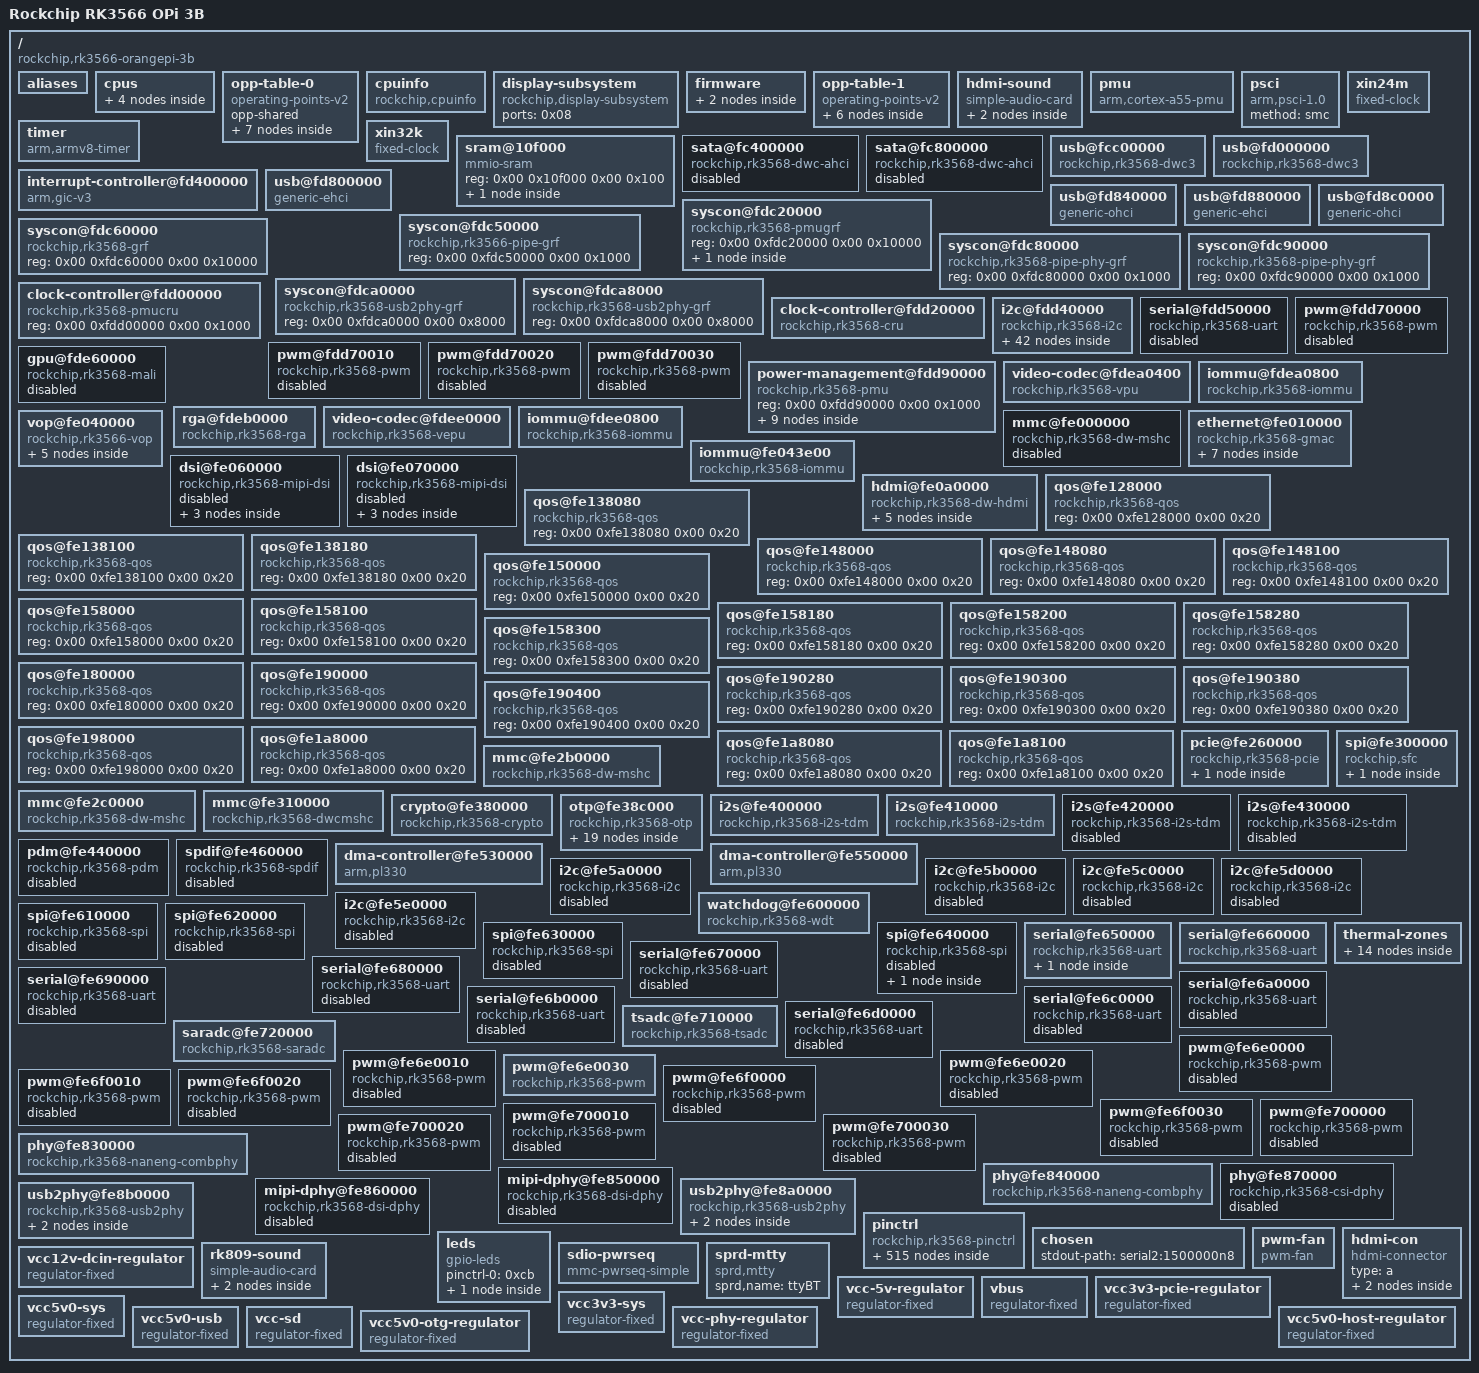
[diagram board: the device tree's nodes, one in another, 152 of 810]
/dts-v1/;

/ {
	interrupt-parent = <0x01>;
	#address-cells = <0x02>;
	#size-cells = <0x02>;
	compatible = "rockchip,rk3566-orangepi-3b\0rockchip,rk3566";
	model = "Rockchip RK3566 OPi 3B";

	aliases {
		gpio0 = "/pinctrl/gpio@fdd60000";
		gpio1 = "/pinctrl/gpio@fe740000";
		gpio2 = "/pinctrl/gpio@fe750000";
		gpio3 = "/pinctrl/gpio@fe760000";
		gpio4 = "/pinctrl/gpio@fe770000";
		i2c0 = "/i2c@fdd40000";
		i2c1 = "/i2c@fe5a0000";
		i2c2 = "/i2c@fe5b0000";
		i2c3 = "/i2c@fe5c0000";
		i2c4 = "/i2c@fe5d0000";
		i2c5 = "/i2c@fe5e0000";
		serial0 = "/serial@fdd50000";
		serial1 = "/serial@fe650000";
		serial2 = "/serial@fe660000";
		serial3 = "/serial@fe670000";
		serial4 = "/serial@fe680000";
		serial5 = "/serial@fe690000";
		serial6 = "/serial@fe6a0000";
		serial7 = "/serial@fe6b0000";
		serial8 = "/serial@fe6c0000";
		serial9 = "/serial@fe6d0000";
		spi0 = "/spi@fe610000";
		spi1 = "/spi@fe620000";
		spi2 = "/spi@fe630000";
		spi3 = "/spi@fe640000";
		ethernet0 = "/ethernet@fe010000";
		mmc0 = "/mmc@fe310000";
		mmc1 = "/mmc@fe2b0000";
	};

	cpus {
		#address-cells = <0x02>;
		#size-cells = <0x00>;

		cpu@0 {
			device_type = "cpu";
			compatible = "arm,cortex-a55";
			reg = <0x00 0x00>;
			clocks = <0x02 0x00>;
			#cooling-cells = <0x02>;
			enable-method = "psci";
			operating-points-v2 = <0x03>;
			cpu-supply = <0x04>;
			phandle = <0x0c>;
		};

		cpu@100 {
			device_type = "cpu";
			compatible = "arm,cortex-a55";
			reg = <0x00 0x100>;
			#cooling-cells = <0x02>;
			enable-method = "psci";
			operating-points-v2 = <0x03>;
			cpu-supply = <0x04>;
			phandle = <0x0d>;
		};

		cpu@200 {
			device_type = "cpu";
			compatible = "arm,cortex-a55";
			reg = <0x00 0x200>;
			#cooling-cells = <0x02>;
			enable-method = "psci";
			operating-points-v2 = <0x03>;
			cpu-supply = <0x04>;
			phandle = <0x0e>;
		};

		cpu@300 {
			device_type = "cpu";
			compatible = "arm,cortex-a55";
			reg = <0x00 0x300>;
			#cooling-cells = <0x02>;
			enable-method = "psci";
			operating-points-v2 = <0x03>;
			cpu-supply = <0x04>;
			phandle = <0x0f>;
		};
	};

	opp-table-0 {
		compatible = "operating-points-v2";
		opp-shared;
		phandle = <0x03>;

		opp-408000000 {
			opp-hz = <0x00 0x18519600>;
			opp-microvolt = <0xdbba0 0xdbba0 0x118c30>;
			clock-latency-ns = <0x9c40>;
		};

		opp-600000000 {
			opp-hz = <0x00 0x23c34600>;
			opp-microvolt = <0xdbba0 0xdbba0 0x118c30>;
		};

		opp-816000000 {
			opp-hz = <0x00 0x30a32c00>;
			opp-microvolt = <0xdbba0 0xdbba0 0x118c30>;
			opp-suspend;
		};

		opp-1104000000 {
			opp-hz = <0x00 0x41cdb400>;
			opp-microvolt = <0xdbba0 0xdbba0 0x118c30>;
		};

		opp-1416000000 {
			opp-hz = <0x00 0x54667200>;
			opp-microvolt = <0xdbba0 0xdbba0 0x118c30>;
		};

		opp-1608000000 {
			opp-hz = <0x00 0x5fd82200>;
			opp-microvolt = <0xee098 0xee098 0x118c30>;
		};

		opp-1800000000 {
			opp-hz = <0x00 0x6b49d200>;
			opp-microvolt = <0x100590 0x100590 0x118c30>;
		};
	};

	cpuinfo {
		compatible = "rockchip,cpuinfo";
		nvmem-cells = <0x05 0x06 0x07>;
		nvmem-cell-names = "id\0cpu-version\0cpu-code";
	};

	display-subsystem {
		compatible = "rockchip,display-subsystem";
		ports = <0x08>;
		phandle = <0xd2>;
	};

	firmware {

		scmi {
			compatible = "arm,scmi-smc";
			arm,smc-id = <0x82000010>;
			shmem = <0x09>;
			#address-cells = <0x01>;
			#size-cells = <0x00>;
			phandle = <0xd3>;

			protocol@14 {
				reg = <0x14>;
				#clock-cells = <0x01>;
				phandle = <0x02>;
			};
		};
	};

	opp-table-1 {
		compatible = "operating-points-v2";
		phandle = <0x4a>;

		opp-200000000 {
			opp-hz = <0x00 0xbebc200>;
			opp-microvolt = <0xc96a8>;
		};

		opp-300000000 {
			opp-hz = <0x00 0x11e1a300>;
			opp-microvolt = <0xc96a8>;
		};

		opp-400000000 {
			opp-hz = <0x00 0x17d78400>;
			opp-microvolt = <0xc96a8>;
		};

		opp-600000000 {
			opp-hz = <0x00 0x23c34600>;
			opp-microvolt = <0xc96a8>;
		};

		opp-700000000 {
			opp-hz = <0x00 0x29b92700>;
			opp-microvolt = <0xdbba0>;
		};

		opp-800000000 {
			opp-hz = <0x00 0x2faf0800>;
			opp-microvolt = <0xf4240>;
		};
	};

	hdmi-sound {
		compatible = "simple-audio-card";
		simple-audio-card,name = "HDMI";
		simple-audio-card,format = "i2s";
		simple-audio-card,mclk-fs = <0x100>;
		status = "okay";
		phandle = <0xd4>;

		simple-audio-card,codec {
			sound-dai = <0x0a>;
		};

		simple-audio-card,cpu {
			sound-dai = <0x0b>;
		};
	};

	pmu {
		compatible = "arm,cortex-a55-pmu";
		interrupts = <0x00 0xe4 0x04 0x00 0xe5 0x04 0x00 0xe6 0x04 0x00 0xe7 0x04>;
		interrupt-affinity = <0x0c 0x0d 0x0e 0x0f>;
	};

	psci {
		compatible = "arm,psci-1.0";
		method = "smc";
	};

	timer {
		compatible = "arm,armv8-timer";
		interrupts = <0x01 0x0d 0x04 0x01 0x0e 0x04 0x01 0x0b 0x04 0x01 0x0a 0x04>;
		arm,no-tick-in-suspend;
	};

	xin24m {
		compatible = "fixed-clock";
		clock-frequency = <0x16e3600>;
		clock-output-names = "xin24m";
		#clock-cells = <0x00>;
		phandle = <0x1f>;
	};

	xin32k {
		compatible = "fixed-clock";
		clock-frequency = <0x8000>;
		clock-output-names = "xin32k";
		pinctrl-0 = <0x10>;
		pinctrl-names = "default";
		#clock-cells = <0x00>;
		phandle = <0xd5>;
	};

	sram@10f000 {
		compatible = "mmio-sram";
		reg = <0x00 0x10f000 0x00 0x100>;
		#address-cells = <0x01>;
		#size-cells = <0x01>;
		ranges = <0x00 0x00 0x10f000 0x100>;

		sram@0 {
			compatible = "arm,scmi-shmem";
			reg = <0x00 0x100>;
			phandle = <0x09>;
		};
	};

	sata@fc400000 {
		compatible = "rockchip,rk3568-dwc-ahci\0snps,dwc-ahci";
		reg = <0x00 0xfc400000 0x00 0x1000>;
		clocks = <0x11 0x9b 0x11 0x9c 0x11 0x9d>;
		clock-names = "sata\0pmalive\0rxoob";
		interrupts = <0x00 0x5f 0x04>;
		phys = <0x12 0x01>;
		phy-names = "sata-phy";
		ports-implemented = <0x01>;
		power-domains = <0x13 0x0f>;
		status = "disabled";
		phandle = <0xd6>;
	};

	sata@fc800000 {
		compatible = "rockchip,rk3568-dwc-ahci\0snps,dwc-ahci";
		reg = <0x00 0xfc800000 0x00 0x1000>;
		clocks = <0x11 0xa0 0x11 0xa1 0x11 0xa2>;
		clock-names = "sata\0pmalive\0rxoob";
		interrupts = <0x00 0x60 0x04>;
		phys = <0x14 0x01>;
		phy-names = "sata-phy";
		ports-implemented = <0x01>;
		power-domains = <0x13 0x0f>;
		status = "disabled";
		phandle = <0xd7>;
	};

	usb@fcc00000 {
		compatible = "rockchip,rk3568-dwc3\0snps,dwc3";
		reg = <0x00 0xfcc00000 0x00 0x400000>;
		interrupts = <0x00 0xa9 0x04>;
		clocks = <0x11 0xa6 0x11 0xa7 0x11 0xa5>;
		clock-names = "ref_clk\0suspend_clk\0bus_clk";
		dr_mode = "host";
		phy_type = "utmi_wide";
		power-domains = <0x13 0x0f>;
		resets = <0x11 0x94>;
		snps,dis_u2_susphy_quirk;
		status = "okay";
		phys = <0x15>;
		phy-names = "usb2-phy";
		extcon = <0x16>;
		maximum-speed = "high-speed";
		phandle = <0xd8>;
	};

	usb@fd000000 {
		compatible = "rockchip,rk3568-dwc3\0snps,dwc3";
		reg = <0x00 0xfd000000 0x00 0x400000>;
		interrupts = <0x00 0xaa 0x04>;
		clocks = <0x11 0xa9 0x11 0xaa 0x11 0xa8>;
		clock-names = "ref_clk\0suspend_clk\0bus_clk";
		dr_mode = "host";
		phys = <0x17 0x12 0x04>;
		phy-names = "usb2-phy\0usb3-phy";
		phy_type = "utmi_wide";
		power-domains = <0x13 0x0f>;
		resets = <0x11 0x95>;
		snps,dis_u2_susphy_quirk;
		status = "okay";
		phandle = <0xd9>;
	};

	interrupt-controller@fd400000 {
		compatible = "arm,gic-v3";
		reg = <0x00 0xfd400000 0x00 0x10000 0x00 0xfd460000 0x00 0x80000>;
		interrupts = <0x01 0x09 0x04>;
		interrupt-controller;
		#interrupt-cells = <0x03>;
		mbi-alias = <0x00 0xfd410000>;
		mbi-ranges = <0x128 0x18>;
		msi-controller;
		phandle = <0x01>;
	};

	usb@fd800000 {
		compatible = "generic-ehci";
		reg = <0x00 0xfd800000 0x00 0x40000>;
		interrupts = <0x00 0x82 0x04>;
		clocks = <0x11 0xbd 0x11 0xbe 0x11 0xbc>;
		phys = <0x18>;
		phy-names = "usb";
		status = "okay";
		phandle = <0xda>;
	};

	usb@fd840000 {
		compatible = "generic-ohci";
		reg = <0x00 0xfd840000 0x00 0x40000>;
		interrupts = <0x00 0x83 0x04>;
		clocks = <0x11 0xbd 0x11 0xbe 0x11 0xbc>;
		phys = <0x18>;
		phy-names = "usb";
		status = "okay";
		phandle = <0xdb>;
	};

	usb@fd880000 {
		compatible = "generic-ehci";
		reg = <0x00 0xfd880000 0x00 0x40000>;
		interrupts = <0x00 0x85 0x04>;
		clocks = <0x11 0xbf 0x11 0xc0 0x11 0xbc>;
		phys = <0x19>;
		phy-names = "usb";
		status = "okay";
		phandle = <0xdc>;
	};

	usb@fd8c0000 {
		compatible = "generic-ohci";
		reg = <0x00 0xfd8c0000 0x00 0x40000>;
		interrupts = <0x00 0x86 0x04>;
		clocks = <0x11 0xbf 0x11 0xc0 0x11 0xbc>;
		phys = <0x19>;
		phy-names = "usb";
		status = "okay";
		phandle = <0xdd>;
	};

	syscon@fdc20000 {
		compatible = "rockchip,rk3568-pmugrf\0syscon\0simple-mfd";
		reg = <0x00 0xfdc20000 0x00 0x10000>;
		phandle = <0xbc>;

		io-domains {
			compatible = "rockchip,rk3568-pmu-io-voltage-domain";
			status = "okay";
			pmuio1-supply = <0x1a>;
			pmuio2-supply = <0x1a>;
			vccio1-supply = <0x1b>;
			vccio2-supply = <0x1c>;
			vccio3-supply = <0x1d>;
			vccio4-supply = <0x1c>;
			vccio5-supply = <0x1e>;
			vccio6-supply = <0x1b>;
			vccio7-supply = <0x1b>;
			phandle = <0xde>;
		};
	};

	syscon@fdc50000 {
		reg = <0x00 0xfdc50000 0x00 0x1000>;
		compatible = "rockchip,rk3566-pipe-grf\0syscon";
		phandle = <0xb6>;
	};

	syscon@fdc60000 {
		compatible = "rockchip,rk3568-grf\0syscon\0simple-mfd";
		reg = <0x00 0xfdc60000 0x00 0x10000>;
		phandle = <0x21>;
	};

	syscon@fdc80000 {
		compatible = "rockchip,rk3568-pipe-phy-grf\0syscon";
		reg = <0x00 0xfdc80000 0x00 0x1000>;
		phandle = <0xb7>;
	};

	syscon@fdc90000 {
		compatible = "rockchip,rk3568-pipe-phy-grf\0syscon";
		reg = <0x00 0xfdc90000 0x00 0x1000>;
		phandle = <0xb8>;
	};

	syscon@fdca0000 {
		compatible = "rockchip,rk3568-usb2phy-grf\0syscon";
		reg = <0x00 0xfdca0000 0x00 0x8000>;
		phandle = <0xb9>;
	};

	syscon@fdca8000 {
		compatible = "rockchip,rk3568-usb2phy-grf\0syscon";
		reg = <0x00 0xfdca8000 0x00 0x8000>;
		phandle = <0xbb>;
	};

	clock-controller@fdd00000 {
		compatible = "rockchip,rk3568-pmucru";
		reg = <0x00 0xfdd00000 0x00 0x1000>;
		#clock-cells = <0x01>;
		#reset-cells = <0x01>;
		phandle = <0x20>;
	};

	clock-controller@fdd20000 {
		compatible = "rockchip,rk3568-cru";
		reg = <0x00 0xfdd20000 0x00 0x1000>;
		clocks = <0x1f>;
		clock-names = "xin24m";
		#clock-cells = <0x01>;
		#reset-cells = <0x01>;
		assigned-clocks = <0x20 0x05 0x11 0x04 0x20 0x01>;
		assigned-clock-rates = <0x8000 0x47868c00 0xbebc200>;
		assigned-clock-parents = <0x20 0x08>;
		rockchip,grf = <0x21>;
		phandle = <0x11>;
	};

	i2c@fdd40000 {
		compatible = "rockchip,rk3568-i2c\0rockchip,rk3399-i2c";
		reg = <0x00 0xfdd40000 0x00 0x1000>;
		interrupts = <0x00 0x2e 0x04>;
		clocks = <0x20 0x07 0x20 0x2d>;
		clock-names = "i2c\0pclk";
		pinctrl-0 = <0x22>;
		pinctrl-names = "default";
		#address-cells = <0x01>;
		#size-cells = <0x00>;
		status = "okay";
		phandle = <0xdf>;

		syr837@40 {
			compatible = "silergy,syr827";
			reg = <0x40>;
			vin-supply = <0x23>;
			regulator-compatible = "fan53555-reg";
			regulator-name = "vdd_cpu";
			regulator-min-microvolt = <0xadf34>;
			regulator-max-microvolt = <0x1535b0>;
			regulator-init-microvolt = <0xdbba0>;
			regulator-initial-mode = <0x01>;
			regulator-ramp-delay = <0x8fc>;
			fcs,suspend-voltage-selector = <0x01>;
			regulator-boot-on;
			regulator-always-on;
			phandle = <0x04>;

			regulator-state-mem {
				regulator-off-in-suspend;
			};
		};

		pmic@20 {
			compatible = "rockchip,rk809";
			reg = <0x20>;
			interrupt-parent = <0x24>;
			interrupts = <0x03 0x08>;
			assigned-clocks = <0x11 0x48>;
			assigned-clock-parents = <0x11 0x196>;
			#clock-cells = <0x01>;
			clock-names = "mclk";
			clocks = <0x11 0x48>;
			pinctrl-names = "default\0pmic-sleep\0pmic-power-off\0pmic-reset";
			pinctrl-0 = <0x25 0x26>;
			pinctrl-1 = <0x27 0x28>;
			pinctrl-2 = <0x29 0x2a>;
			pinctrl-3 = <0x29 0x2b>;
			#sound-dai-cells = <0x00>;
			rockchip,system-power-controller;
			wakeup-source;
			vcc1-supply = <0x2c>;
			vcc2-supply = <0x2c>;
			vcc3-supply = <0x2c>;
			vcc4-supply = <0x2c>;
			vcc5-supply = <0x2c>;
			vcc6-supply = <0x2c>;
			vcc7-supply = <0x2c>;
			vcc8-supply = <0x2c>;
			vcc9-supply = <0x2c>;
			phandle = <0x96>;

			pinctrl_rk8xx {
				gpio-controller;
				#gpio-cells = <0x02>;
				phandle = <0xe0>;

				rk817_slppin_null {
					pins = "gpio_slp";
					function = "pin_fun0";
					phandle = <0xe1>;
				};

				rk817_slppin_slp {
					pins = "gpio_slp";
					function = "pin_fun1";
					phandle = <0x28>;
				};

				rk817_slppin_pwrdn {
					pins = "gpio_slp";
					function = "pin_fun2";
					phandle = <0x2a>;
				};

				rk817_slppin_rst {
					pins = "gpio_slp";
					function = "pin_fun3";
					phandle = <0x2b>;
				};
			};

			regulators {

				DCDC_REG1 {
					regulator-always-on;
					regulator-boot-on;
					regulator-min-microvolt = <0x7a120>;
					regulator-max-microvolt = <0x149970>;
					regulator-init-microvolt = <0xdbba0>;
					regulator-ramp-delay = <0x1771>;
					regulator-initial-mode = <0x02>;
					regulator-name = "vdd_logic";
					phandle = <0xe2>;

					regulator-state-mem {
						regulator-off-in-suspend;
					};
				};

				DCDC_REG2 {
					regulator-always-on;
					regulator-boot-on;
					regulator-min-microvolt = <0x7a120>;
					regulator-max-microvolt = <0x149970>;
					regulator-init-microvolt = <0xdbba0>;
					regulator-ramp-delay = <0x1771>;
					regulator-initial-mode = <0x02>;
					regulator-name = "vdd_gpu";
					phandle = <0x4b>;

					regulator-state-mem {
						regulator-off-in-suspend;
					};
				};

				DCDC_REG3 {
					regulator-always-on;
					regulator-boot-on;
					regulator-initial-mode = <0x02>;
					regulator-name = "vcc_ddr";
					phandle = <0xe3>;

					regulator-state-mem {
						regulator-on-in-suspend;
					};
				};

				DCDC_REG4 {
					regulator-always-on;
					regulator-boot-on;
					regulator-min-microvolt = <0x7a120>;
					regulator-max-microvolt = <0x149970>;
					regulator-init-microvolt = <0xdbba0>;
					regulator-ramp-delay = <0x1771>;
					regulator-initial-mode = <0x02>;
					regulator-name = "vdd_npu";
					phandle = <0xe4>;

					regulator-state-mem {
						regulator-off-in-suspend;
					};
				};

				LDO_REG1 {
					regulator-boot-on;
					regulator-always-on;
					regulator-min-microvolt = <0xdbba0>;
					regulator-max-microvolt = <0xdbba0>;
					regulator-name = "vdda0v9_image";
					phandle = <0x60>;

					regulator-state-mem {
						regulator-off-in-suspend;
					};
				};

				LDO_REG2 {
					regulator-always-on;
					regulator-boot-on;
					regulator-min-microvolt = <0xdbba0>;
					regulator-max-microvolt = <0xdbba0>;
					regulator-name = "vdda_0v9";
					phandle = <0xe5>;

					regulator-state-mem {
						regulator-off-in-suspend;
					};
				};

				LDO_REG3 {
					regulator-always-on;
					regulator-boot-on;
					regulator-min-microvolt = <0xdbba0>;
					regulator-max-microvolt = <0xdbba0>;
					regulator-name = "vdda0v9_pmu";
					phandle = <0xe6>;

					regulator-state-mem {
						regulator-on-in-suspend;
						regulator-suspend-microvolt = <0xdbba0>;
					};
				};

				LDO_REG4 {
					regulator-always-on;
					regulator-boot-on;
					regulator-min-microvolt = <0x2dc6c0>;
					regulator-max-microvolt = <0x2dc6c0>;
					regulator-name = "vccio_acodec";
					phandle = <0xe7>;

					regulator-state-mem {
						regulator-off-in-suspend;
					};
				};

				LDO_REG5 {
					regulator-always-on;
					regulator-boot-on;
					regulator-min-microvolt = <0x1b7740>;
					regulator-max-microvolt = <0x325aa0>;
					regulator-name = "vccio_sd";
					phandle = <0x1d>;

					regulator-state-mem {
						regulator-off-in-suspend;
					};
				};

				LDO_REG6 {
					regulator-always-on;
					regulator-boot-on;
					regulator-min-microvolt = <0x325aa0>;
					regulator-max-microvolt = <0x325aa0>;
					regulator-name = "vcc3v3_pmu";
					phandle = <0x1a>;

					regulator-state-mem {
						regulator-on-in-suspend;
						regulator-suspend-microvolt = <0x325aa0>;
					};
				};

				LDO_REG7 {
					regulator-always-on;
					regulator-boot-on;
					regulator-min-microvolt = <0x1b7740>;
					regulator-max-microvolt = <0x1b7740>;
					regulator-name = "vcca_1v8";
					phandle = <0xa9>;

					regulator-state-mem {
						regulator-off-in-suspend;
					};
				};

				LDO_REG8 {
					regulator-always-on;
					regulator-boot-on;
					regulator-min-microvolt = <0x1b7740>;
					regulator-max-microvolt = <0x1b7740>;
					regulator-name = "vcca1v8_pmu";
					phandle = <0xe8>;

					regulator-state-mem {
						regulator-on-in-suspend;
						regulator-suspend-microvolt = <0x1b7740>;
					};
				};

				LDO_REG9 {
					regulator-always-on;
					regulator-boot-on;
					regulator-min-microvolt = <0x1b7740>;
					regulator-max-microvolt = <0x1b7740>;
					regulator-name = "vcca1v8_image";
					phandle = <0x61>;

					regulator-state-mem {
						regulator-off-in-suspend;
					};
				};

				DCDC_REG5 {
					regulator-always-on;
					regulator-boot-on;
					regulator-min-microvolt = <0x1b7740>;
					regulator-max-microvolt = <0x1b7740>;
					regulator-name = "vcc_1v8";
					phandle = <0x1c>;

					regulator-state-mem {
						regulator-off-in-suspend;
					};
				};

				SWITCH_REG1 {
					regulator-always-on;
					regulator-boot-on;
					regulator-name = "vcc_3v3";
					phandle = <0x1b>;

					regulator-state-mem {
						regulator-off-in-suspend;
					};
				};

				SWITCH_REG2 {
					regulator-always-on;
					regulator-boot-on;
					regulator-name = "vcc3v3_sd";
					phandle = <0xe9>;

					regulator-state-mem {
						regulator-off-in-suspend;
					};
				};
			};

			codec {
				mic-in-differential;
			};
		};
	};

	serial@fdd50000 {
		compatible = "rockchip,rk3568-uart\0snps,dw-apb-uart";
		reg = <0x00 0xfdd50000 0x00 0x100>;
		interrupts = <0x00 0x74 0x04>;
		clocks = <0x20 0x0b 0x20 0x2c>;
		clock-names = "baudclk\0apb_pclk";
		dmas = <0x2d 0x00 0x2d 0x01>;
		pinctrl-0 = <0x2e>;
		pinctrl-names = "default";
		reg-io-width = <0x04>;
		reg-shift = <0x02>;
		status = "disabled";
		phandle = <0xea>;
	};

	pwm@fdd70000 {
		compatible = "rockchip,rk3568-pwm\0rockchip,rk3328-pwm";
		reg = <0x00 0xfdd70000 0x00 0x10>;
		clocks = <0x20 0x0d 0x20 0x30>;
		clock-names = "pwm\0pclk";
		pinctrl-0 = <0x2f>;
		pinctrl-names = "default";
		#pwm-cells = <0x03>;
		status = "disabled";
		phandle = <0xeb>;
	};

	pwm@fdd70010 {
		compatible = "rockchip,rk3568-pwm\0rockchip,rk3328-pwm";
		reg = <0x00 0xfdd70010 0x00 0x10>;
		clocks = <0x20 0x0d 0x20 0x30>;
		clock-names = "pwm\0pclk";
		pinctrl-0 = <0x30>;
		pinctrl-names = "default";
		#pwm-cells = <0x03>;
		status = "disabled";
		phandle = <0xec>;
	};

	pwm@fdd70020 {
		compatible = "rockchip,rk3568-pwm\0rockchip,rk3328-pwm";
		reg = <0x00 0xfdd70020 0x00 0x10>;
		clocks = <0x20 0x0d 0x20 0x30>;
		clock-names = "pwm\0pclk";
		pinctrl-0 = <0x31>;
		pinctrl-names = "default";
		#pwm-cells = <0x03>;
		status = "disabled";
		phandle = <0xed>;
	};

	pwm@fdd70030 {
		compatible = "rockchip,rk3568-pwm\0rockchip,rk3328-pwm";
		reg = <0x00 0xfdd70030 0x00 0x10>;
		clocks = <0x20 0x0d 0x20 0x30>;
		clock-names = "pwm\0pclk";
		pinctrl-0 = <0x32>;
		pinctrl-names = "default";
		#pwm-cells = <0x03>;
		status = "disabled";
		phandle = <0xee>;
	};

	power-management@fdd90000 {
		compatible = "rockchip,rk3568-pmu\0syscon\0simple-mfd";
		reg = <0x00 0xfdd90000 0x00 0x1000>;
		phandle = <0xef>;

		power-controller {
			compatible = "rockchip,rk3568-power-controller";
			#power-domain-cells = <0x01>;
			#address-cells = <0x01>;
			#size-cells = <0x00>;
			phandle = <0x13>;

			power-domain@7 {
				reg = <0x07>;
				clocks = <0x11 0x19 0x11 0x1a>;
				pm_qos = <0x33>;
				#power-domain-cells = <0x00>;
			};

			power-domain@8 {
				reg = <0x08>;
				clocks = <0x11 0xcc 0x11 0xcd>;
				pm_qos = <0x34 0x35 0x36>;
				#power-domain-cells = <0x00>;
			};

			power-domain@9 {
				reg = <0x09>;
				clocks = <0x11 0xda 0x11 0xdb 0x11 0xdc>;
				pm_qos = <0x37 0x38 0x39>;
				#power-domain-cells = <0x00>;
			};

			power-domain@10 {
				reg = <0x0a>;
				clocks = <0x11 0xf1 0x11 0xf2>;
				pm_qos = <0x3a 0x3b 0x3c 0x3d 0x3e 0x3f>;
				#power-domain-cells = <0x00>;
			};

			power-domain@11 {
				reg = <0x0b>;
				clocks = <0x11 0xed>;
				pm_qos = <0x40>;
				#power-domain-cells = <0x00>;
			};

			power-domain@13 {
				clocks = <0x11 0x107>;
				reg = <0x0d>;
				pm_qos = <0x41>;
				#power-domain-cells = <0x00>;
			};

			power-domain@14 {
				reg = <0x0e>;
				clocks = <0x11 0x102>;
				pm_qos = <0x42 0x43 0x44>;
				#power-domain-cells = <0x00>;
			};

			power-domain@15 {
				reg = <0x0f>;
				clocks = <0x11 0x7f>;
				pm_qos = <0x45 0x46 0x47 0x48 0x49>;
				#power-domain-cells = <0x00>;
			};
		};
	};

	gpu@fde60000 {
		compatible = "rockchip,rk3568-mali\0arm,mali-bifrost";
		reg = <0x00 0xfde60000 0x00 0x4000>;
		interrupts = <0x00 0x28 0x04 0x00 0x29 0x04 0x00 0x27 0x04>;
		interrupt-names = "job\0mmu\0gpu";
		clocks = <0x02 0x01 0x11 0x1b>;
		clock-names = "gpu\0bus";
		#cooling-cells = <0x02>;
		operating-points-v2 = <0x4a>;
		power-domains = <0x13 0x07>;
		status = "disabled";
		mali-supply = <0x4b>;
		phandle = <0xa6>;
	};

	video-codec@fdea0400 {
		compatible = "rockchip,rk3568-vpu";
		reg = <0x00 0xfdea0000 0x00 0x800>;
		interrupts = <0x00 0x8b 0x04>;
		clocks = <0x11 0xee 0x11 0xef>;
		clock-names = "aclk\0hclk";
		iommus = <0x4c>;
		power-domains = <0x13 0x0b>;
		phandle = <0xf0>;
	};

	iommu@fdea0800 {
		compatible = "rockchip,rk3568-iommu";
		reg = <0x00 0xfdea0800 0x00 0x40>;
		interrupts = <0x00 0x8a 0x04>;
		clock-names = "aclk\0iface";
		clocks = <0x11 0xee 0x11 0xef>;
		power-domains = <0x13 0x0b>;
		#iommu-cells = <0x00>;
		phandle = <0x4c>;
	};

	rga@fdeb0000 {
		compatible = "rockchip,rk3568-rga\0rockchip,rk3288-rga";
		reg = <0x00 0xfdeb0000 0x00 0x180>;
		interrupts = <0x00 0x5a 0x04>;
		clocks = <0x11 0xf3 0x11 0xf4 0x11 0xf5>;
		clock-names = "aclk\0hclk\0sclk";
		resets = <0x11 0x126 0x11 0x124 0x11 0x125>;
		reset-names = "core\0axi\0ahb";
		power-domains = <0x13 0x0a>;
		phandle = <0xf1>;
	};

	video-codec@fdee0000 {
		compatible = "rockchip,rk3568-vepu";
		reg = <0x00 0xfdee0000 0x00 0x800>;
		interrupts = <0x00 0x40 0x04>;
		clocks = <0x11 0xfd 0x11 0xfe>;
		clock-names = "aclk\0hclk";
		iommus = <0x4d>;
		power-domains = <0x13 0x0a>;
		phandle = <0xf2>;
	};

	iommu@fdee0800 {
		compatible = "rockchip,rk3568-iommu";
		reg = <0x00 0xfdee0800 0x00 0x40>;
		interrupts = <0x00 0x3f 0x04>;
		clocks = <0x11 0xfd 0x11 0xfe>;
		clock-names = "aclk\0iface";
		power-domains = <0x13 0x0a>;
		#iommu-cells = <0x00>;
		phandle = <0x4d>;
	};

	mmc@fe000000 {
		compatible = "rockchip,rk3568-dw-mshc\0rockchip,rk3288-dw-mshc";
		reg = <0x00 0xfe000000 0x00 0x4000>;
		interrupts = <0x00 0x64 0x04>;
		clocks = <0x11 0xc1 0x11 0xc2 0x11 0x18e 0x11 0x18f>;
		clock-names = "biu\0ciu\0ciu-drive\0ciu-sample";
		fifo-depth = <0x100>;
		max-frequency = <0x8f0d180>;
		resets = <0x11 0xeb>;
		reset-names = "reset";
		status = "disabled";
		phandle = <0xf3>;
	};

	ethernet@fe010000 {
		compatible = "rockchip,rk3568-gmac\0snps,dwmac-4.20a";
		reg = <0x00 0xfe010000 0x00 0x10000>;
		interrupts = <0x00 0x20 0x04 0x00 0x1d 0x04>;
		interrupt-names = "macirq\0eth_wake_irq";
		clocks = <0x11 0x186 0x11 0x189 0x11 0x189 0x11 0xc7 0x11 0xc3 0x11 0xc4 0x11 0x189 0x11 0xc8>;
		clock-names = "stmmaceth\0mac_clk_rx\0mac_clk_tx\0clk_mac_refout\0aclk_mac\0pclk_mac\0clk_mac_speed\0ptp_ref";
		resets = <0x11 0xec>;
		reset-names = "stmmaceth";
		rockchip,grf = <0x21>;
		snps,axi-config = <0x4e>;
		snps,mixed-burst;
		snps,mtl-rx-config = <0x4f>;
		snps,mtl-tx-config = <0x50>;
		snps,tso;
		status = "okay";
		assigned-clocks = <0x11 0x189 0x11 0x186>;
		assigned-clock-parents = <0x11 0x187 0x11 0xc5>;
		assigned-clock-rates = <0x00 0x7735940>;
		clock_in_out = "input";
		phy-mode = "rgmii";
		pinctrl-names = "default";
		pinctrl-0 = <0x51 0x52 0x53 0x54 0x55 0x56>;
		snps,reset-gpio = <0x57 0x14 0x01>;
		snps,reset-active-low;
		snps,reset-delays-us = <0x00 0xc350 0x30d40>;
		tx_delay = <0x30>;
		rx_delay = <0x10>;
		phy-handle = <0x58>;
		phandle = <0xf4>;

		mdio {
			compatible = "snps,dwmac-mdio";
			#address-cells = <0x01>;
			#size-cells = <0x00>;
			phandle = <0xf5>;

			phy@0 {
				compatible = "ethernet-phy-ieee802.3-c22";
				reg = <0x00>;
				phandle = <0x58>;
			};
		};

		stmmac-axi-config {
			snps,blen = <0x00 0x00 0x00 0x00 0x10 0x08 0x04>;
			snps,rd_osr_lmt = <0x08>;
			snps,wr_osr_lmt = <0x04>;
			phandle = <0x4e>;
		};

		rx-queues-config {
			snps,rx-queues-to-use = <0x01>;
			phandle = <0x4f>;

			queue0 {
			};
		};

		tx-queues-config {
			snps,tx-queues-to-use = <0x01>;
			phandle = <0x50>;

			queue0 {
			};
		};
	};

	vop@fe040000 {
		reg = <0x00 0xfe040000 0x00 0x3000 0x00 0xfe044000 0x00 0x1000>;
		reg-names = "vop\0gamma-lut";
		interrupts = <0x00 0x94 0x04>;
		clocks = <0x11 0xdd 0x11 0xde 0x11 0xdf 0x11 0xe0 0x11 0xe1>;
		clock-names = "aclk\0hclk\0dclk_vp0\0dclk_vp1\0dclk_vp2";
		iommus = <0x59>;
		power-domains = <0x13 0x09>;
		rockchip,grf = <0x21>;
		status = "okay";
		compatible = "rockchip,rk3566-vop";
		assigned-clocks = <0x11 0xdf 0x11 0xe0>;
		assigned-clock-parents = <0x20 0x02 0x11 0x05>;
		phandle = <0xf6>;

		ports {
			#address-cells = <0x01>;
			#size-cells = <0x00>;
			phandle = <0x08>;

			port@0 {
				reg = <0x00>;
				#address-cells = <0x01>;
				#size-cells = <0x00>;
				phandle = <0xf7>;

				endpoint@2 {
					reg = <0x02>;
					remote-endpoint = <0x5a>;
					status = "okay";
					phandle = <0x62>;
				};
			};

			port@1 {
				reg = <0x01>;
				#address-cells = <0x01>;
				#size-cells = <0x00>;
				phandle = <0xf8>;
			};

			port@2 {
				reg = <0x02>;
				#address-cells = <0x01>;
				#size-cells = <0x00>;
				phandle = <0xf9>;
			};
		};
	};

	iommu@fe043e00 {
		compatible = "rockchip,rk3568-iommu";
		reg = <0x00 0xfe043e00 0x00 0x100 0x00 0xfe043f00 0x00 0x100>;
		interrupts = <0x00 0x94 0x04>;
		clocks = <0x11 0xdd 0x11 0xde>;
		clock-names = "aclk\0iface";
		#iommu-cells = <0x00>;
		status = "okay";
		phandle = <0x59>;
	};

	dsi@fe060000 {
		compatible = "rockchip,rk3568-mipi-dsi\0snps,dw-mipi-dsi";
		reg = <0x00 0xfe060000 0x00 0x10000>;
		interrupts = <0x00 0x44 0x04>;
		clock-names = "pclk";
		clocks = <0x11 0xe8>;
		phy-names = "dphy";
		phys = <0x5b>;
		power-domains = <0x13 0x09>;
		reset-names = "apb";
		resets = <0x11 0x110>;
		rockchip,grf = <0x21>;
		status = "disabled";
		phandle = <0xfa>;

		ports {
			#address-cells = <0x01>;
			#size-cells = <0x00>;

			port@0 {
				reg = <0x00>;
				phandle = <0xfb>;
			};

			port@1 {
				reg = <0x01>;
				phandle = <0xfc>;
			};
		};
	};

	dsi@fe070000 {
		compatible = "rockchip,rk3568-mipi-dsi\0snps,dw-mipi-dsi";
		reg = <0x00 0xfe070000 0x00 0x10000>;
		interrupts = <0x00 0x45 0x04>;
		clock-names = "pclk";
		clocks = <0x11 0xe9>;
		phy-names = "dphy";
		phys = <0x5c>;
		power-domains = <0x13 0x09>;
		reset-names = "apb";
		resets = <0x11 0x111>;
		rockchip,grf = <0x21>;
		status = "disabled";
		phandle = <0xfd>;

		ports {
			#address-cells = <0x01>;
			#size-cells = <0x00>;

			port@0 {
				reg = <0x00>;
				phandle = <0xfe>;
			};

			port@1 {
				reg = <0x01>;
				phandle = <0xff>;
			};
		};
	};

	hdmi@fe0a0000 {
		compatible = "rockchip,rk3568-dw-hdmi";
		reg = <0x00 0xfe0a0000 0x00 0x20000>;
		interrupts = <0x00 0x2d 0x04>;
		clocks = <0x11 0xe6 0x11 0xe7 0x11 0x193 0x20 0x28 0x11 0xda>;
		clock-names = "iahb\0isfr\0cec\0ref";
		pinctrl-names = "default";
		pinctrl-0 = <0x5d 0x5e 0x5f>;
		power-domains = <0x13 0x09>;
		reg-io-width = <0x04>;
		rockchip,grf = <0x21>;
		#sound-dai-cells = <0x00>;
		status = "okay";
		avdd-0v9-supply = <0x60>;
		avdd-1v8-supply = <0x61>;
		phandle = <0x0a>;

		ports {
			#address-cells = <0x01>;
			#size-cells = <0x00>;

			port@0 {
				reg = <0x00>;
				phandle = <0x100>;

				endpoint {
					remote-endpoint = <0x62>;
					status = "okay";
					phandle = <0x5a>;
				};
			};

			port@1 {
				reg = <0x01>;
				phandle = <0x101>;

				endpoint {
					remote-endpoint = <0x63>;
					status = "okay";
					phandle = <0xca>;
				};
			};
		};
	};

	qos@fe128000 {
		compatible = "rockchip,rk3568-qos\0syscon";
		reg = <0x00 0xfe128000 0x00 0x20>;
		phandle = <0x33>;
	};

	qos@fe138080 {
		compatible = "rockchip,rk3568-qos\0syscon";
		reg = <0x00 0xfe138080 0x00 0x20>;
		phandle = <0x42>;
	};

	qos@fe138100 {
		compatible = "rockchip,rk3568-qos\0syscon";
		reg = <0x00 0xfe138100 0x00 0x20>;
		phandle = <0x43>;
	};

	qos@fe138180 {
		compatible = "rockchip,rk3568-qos\0syscon";
		reg = <0x00 0xfe138180 0x00 0x20>;
		phandle = <0x44>;
	};

	qos@fe148000 {
		compatible = "rockchip,rk3568-qos\0syscon";
		reg = <0x00 0xfe148000 0x00 0x20>;
		phandle = <0x34>;
	};

	qos@fe148080 {
		compatible = "rockchip,rk3568-qos\0syscon";
		reg = <0x00 0xfe148080 0x00 0x20>;
		phandle = <0x35>;
	};

	qos@fe148100 {
		compatible = "rockchip,rk3568-qos\0syscon";
		reg = <0x00 0xfe148100 0x00 0x20>;
		phandle = <0x36>;
	};

	qos@fe150000 {
		compatible = "rockchip,rk3568-qos\0syscon";
		reg = <0x00 0xfe150000 0x00 0x20>;
		phandle = <0x40>;
	};

	qos@fe158000 {
		compatible = "rockchip,rk3568-qos\0syscon";
		reg = <0x00 0xfe158000 0x00 0x20>;
		phandle = <0x3a>;
	};

	qos@fe158100 {
		compatible = "rockchip,rk3568-qos\0syscon";
		reg = <0x00 0xfe158100 0x00 0x20>;
		phandle = <0x3b>;
	};

	qos@fe158180 {
		compatible = "rockchip,rk3568-qos\0syscon";
		reg = <0x00 0xfe158180 0x00 0x20>;
		phandle = <0x3c>;
	};

	qos@fe158200 {
		compatible = "rockchip,rk3568-qos\0syscon";
		reg = <0x00 0xfe158200 0x00 0x20>;
		phandle = <0x3d>;
	};

	qos@fe158280 {
		compatible = "rockchip,rk3568-qos\0syscon";
		reg = <0x00 0xfe158280 0x00 0x20>;
		phandle = <0x3e>;
	};

	qos@fe158300 {
		compatible = "rockchip,rk3568-qos\0syscon";
		reg = <0x00 0xfe158300 0x00 0x20>;
		phandle = <0x3f>;
	};

	qos@fe180000 {
		compatible = "rockchip,rk3568-qos\0syscon";
		reg = <0x00 0xfe180000 0x00 0x20>;
		phandle = <0x102>;
	};

	qos@fe190000 {
		compatible = "rockchip,rk3568-qos\0syscon";
		reg = <0x00 0xfe190000 0x00 0x20>;
		phandle = <0x45>;
	};

	qos@fe190280 {
		compatible = "rockchip,rk3568-qos\0syscon";
		reg = <0x00 0xfe190280 0x00 0x20>;
		phandle = <0x46>;
	};

	qos@fe190300 {
		compatible = "rockchip,rk3568-qos\0syscon";
		reg = <0x00 0xfe190300 0x00 0x20>;
		phandle = <0x47>;
	};

	qos@fe190380 {
		compatible = "rockchip,rk3568-qos\0syscon";
		reg = <0x00 0xfe190380 0x00 0x20>;
		phandle = <0x48>;
	};

	qos@fe190400 {
		compatible = "rockchip,rk3568-qos\0syscon";
		reg = <0x00 0xfe190400 0x00 0x20>;
		phandle = <0x49>;
	};

	qos@fe198000 {
		compatible = "rockchip,rk3568-qos\0syscon";
		reg = <0x00 0xfe198000 0x00 0x20>;
		phandle = <0x41>;
	};

	qos@fe1a8000 {
		compatible = "rockchip,rk3568-qos\0syscon";
		reg = <0x00 0xfe1a8000 0x00 0x20>;
		phandle = <0x37>;
	};

	qos@fe1a8080 {
		compatible = "rockchip,rk3568-qos\0syscon";
		reg = <0x00 0xfe1a8080 0x00 0x20>;
		phandle = <0x38>;
	};

	qos@fe1a8100 {
		compatible = "rockchip,rk3568-qos\0syscon";
		reg = <0x00 0xfe1a8100 0x00 0x20>;
		phandle = <0x39>;
	};

	pcie@fe260000 {
		compatible = "rockchip,rk3568-pcie";
		reg = <0x03 0xc0000000 0x00 0x400000 0x00 0xfe260000 0x00 0x10000 0x00 0xf4000000 0x00 0x100000>;
		reg-names = "dbi\0apb\0config";
		interrupts = <0x00 0x4b 0x04 0x00 0x4a 0x04 0x00 0x49 0x04 0x00 0x48 0x04 0x00 0x47 0x04>;
		interrupt-names = "sys\0pmc\0msi\0legacy\0err";
		bus-range = <0x00 0x0f>;
		clocks = <0x11 0x81 0x11 0x82 0x11 0x83 0x11 0x84 0x11 0x85>;
		clock-names = "aclk_mst\0aclk_slv\0aclk_dbi\0pclk\0aux";
		device_type = "pci";
		#interrupt-cells = <0x01>;
		interrupt-map-mask = <0x00 0x00 0x00 0x07>;
		interrupt-map = <0x00 0x00 0x00 0x01 0x64 0x00 0x00 0x00 0x00 0x02 0x64 0x01 0x00 0x00 0x00 0x03 0x64 0x02 0x00 0x00 0x00 0x04 0x64 0x03>;
		linux,pci-domain = <0x00>;
		num-ib-windows = <0x06>;
		num-ob-windows = <0x02>;
		max-link-speed = <0x02>;
		msi-map = <0x00 0x01 0x00 0x1000>;
		num-lanes = <0x01>;
		phys = <0x14 0x02>;
		phy-names = "pcie-phy";
		power-domains = <0x13 0x0f>;
		ranges = <0x1000000 0x00 0xf4100000 0x00 0xf4100000 0x00 0x100000 0x2000000 0x00 0xf4200000 0x00 0xf4200000 0x00 0x1e00000 0x3000000 0x00 0x40000000 0x03 0x00 0x00 0x40000000>;
		resets = <0x11 0xa1>;
		reset-names = "pipe";
		#address-cells = <0x03>;
		#size-cells = <0x02>;
		status = "okay";
		reset-gpios = <0x24 0x0e 0x00>;
		vpcie3v3-supply = <0x65>;
		phandle = <0x103>;

		legacy-interrupt-controller {
			#address-cells = <0x00>;
			#interrupt-cells = <0x01>;
			interrupt-controller;
			interrupt-parent = <0x01>;
			interrupts = <0x00 0x48 0x01>;
			phandle = <0x64>;
		};
	};

	mmc@fe2b0000 {
		compatible = "rockchip,rk3568-dw-mshc\0rockchip,rk3288-dw-mshc";
		reg = <0x00 0xfe2b0000 0x00 0x4000>;
		interrupts = <0x00 0x62 0x04>;
		clocks = <0x11 0xb0 0x11 0xb1 0x11 0x18a 0x11 0x18b>;
		clock-names = "biu\0ciu\0ciu-drive\0ciu-sample";
		fifo-depth = <0x100>;
		max-frequency = <0x8f0d180>;
		resets = <0x11 0xd4>;
		reset-names = "reset";
		status = "okay";
		bus-width = <0x04>;
		cap-mmc-highspeed;
		cap-sd-highspeed;
		disable-wp;
		sd-uhs-sdr104;
		vmmc-supply = <0x66>;
		vqmmc-supply = <0x1d>;
		pinctrl-names = "default";
		pinctrl-0 = <0x67 0x68 0x69 0x6a>;
		phandle = <0x104>;
	};

	mmc@fe2c0000 {
		compatible = "rockchip,rk3568-dw-mshc\0rockchip,rk3288-dw-mshc";
		reg = <0x00 0xfe2c0000 0x00 0x4000>;
		interrupts = <0x00 0x63 0x04>;
		clocks = <0x11 0xb2 0x11 0xb3 0x11 0x18c 0x11 0x18d>;
		clock-names = "biu\0ciu\0ciu-drive\0ciu-sample";
		fifo-depth = <0x100>;
		max-frequency = <0x8f0d180>;
		resets = <0x11 0xd6>;
		reset-names = "reset";
		status = "okay";
		bus-width = <0x04>;
		disable-wp;
		cap-sd-highspeed;
		cap-sdio-irq;
		keep-power-in-suspend;
		mmc-pwrseq = <0x6b>;
		non-removable;
		pinctrl-names = "default";
		pinctrl-0 = <0x6c 0x6d 0x6e>;
		sd-uhs-sdr104;
		phandle = <0x105>;
	};

	spi@fe300000 {
		compatible = "rockchip,sfc";
		reg = <0x00 0xfe300000 0x00 0x4000>;
		interrupts = <0x00 0x65 0x04>;
		clocks = <0x11 0x78 0x11 0x76>;
		clock-names = "clk_sfc\0hclk_sfc";
		pinctrl-0 = <0x6f>;
		pinctrl-names = "default";
		status = "okay";
		#address-cells = <0x01>;
		#size-cells = <0x00>;
		phandle = <0x106>;

		flash@0 {
			compatible = "jedec,spi-nor";
			reg = <0x00>;
			spi-max-frequency = <0x5f5e100>;
			spi-rx-bus-width = <0x04>;
			spi-tx-bus-width = <0x01>;
		};
	};

	mmc@fe310000 {
		compatible = "rockchip,rk3568-dwcmshc";
		reg = <0x00 0xfe310000 0x00 0x10000>;
		interrupts = <0x00 0x13 0x04>;
		assigned-clocks = <0x11 0x7b 0x11 0x7d>;
		assigned-clock-rates = <0xbebc200 0x16e3600>;
		clocks = <0x11 0x7c 0x11 0x7a 0x11 0x79 0x11 0x7b 0x11 0x7d>;
		clock-names = "core\0bus\0axi\0block\0timer";
		status = "okay";
		bus-width = <0x08>;
		max-frequency = <0xbebc200>;
		non-removable;
		pinctrl-names = "default";
		pinctrl-0 = <0x70 0x71 0x72>;
		phandle = <0x107>;
	};

	crypto@fe380000 {
		compatible = "rockchip,rk3568-crypto";
		reg = <0x00 0xfe380000 0x00 0x2000>;
		interrupts = <0x00 0x04 0x04>;
		clocks = <0x11 0x6a 0x11 0x6b 0x11 0x6c>;
		clock-names = "aclk\0hclk\0core";
		resets = <0x11 0x69>;
		reset-names = "core";
		status = "okay";
		phandle = <0x108>;
	};

	otp@fe38c000 {
		compatible = "rockchip,rk3568-otp";
		reg = <0x00 0xfe38c000 0x00 0x4000>;
		#address-cells = <0x01>;
		#size-cells = <0x01>;
		clocks = <0x11 0x73 0x11 0x72 0x11 0x71 0x11 0x181>;
		clock-names = "usr\0sbpi\0apb\0phy";
		resets = <0x11 0x1cf>;
		reset-names = "otp_phy";
		phandle = <0x109>;

		cpu-code@2 {
			reg = <0x02 0x02>;
			phandle = <0x07>;
		};

		cpu-version@8 {
			reg = <0x08 0x01>;
			bits = <0x03 0x03>;
			phandle = <0x06>;
		};

		mbist-vmin@9 {
			reg = <0x09 0x01>;
			bits = <0x00 0x04>;
			phandle = <0x10a>;
		};

		id@a {
			reg = <0x0a 0x10>;
			phandle = <0x05>;
		};

		cpu-leakage@1a {
			reg = <0x1a 0x01>;
			phandle = <0x10b>;
		};

		log-leakage@1b {
			reg = <0x1b 0x01>;
			phandle = <0x10c>;
		};

		npu-leakage@1c {
			reg = <0x1c 0x01>;
			phandle = <0x10d>;
		};

		gpu-leakage@1d {
			reg = <0x1d 0x01>;
			phandle = <0x10e>;
		};

		core-pvtm@2a {
			reg = <0x2a 0x02>;
			phandle = <0x10f>;
		};

		cpu-tsadc-trim-l@2e {
			reg = <0x2e 0x01>;
			phandle = <0x110>;
		};

		cpu-tsadc-trim-h@2f {
			reg = <0x2f 0x01>;
			bits = <0x00 0x04>;
			phandle = <0x111>;
		};

		npu-tsadc-trim-l@30 {
			reg = <0x30 0x01>;
			phandle = <0x112>;
		};

		npu-tsadc-trim-h@31 {
			reg = <0x31 0x01>;
			bits = <0x00 0x04>;
			phandle = <0x113>;
		};

		tsadc-trim-base-frac@31 {
			reg = <0x31 0x01>;
			bits = <0x04 0x04>;
			phandle = <0x114>;
		};

		tsadc-trim-base@32 {
			reg = <0x32 0x01>;
			phandle = <0x115>;
		};

		cpu-opp-info@36 {
			reg = <0x36 0x06>;
			phandle = <0x116>;
		};

		gpu-opp-info@3c {
			reg = <0x3c 0x06>;
			phandle = <0x117>;
		};

		npu-opp-info@42 {
			reg = <0x42 0x06>;
			phandle = <0x118>;
		};

		dmc-opp-info@48 {
			reg = <0x48 0x06>;
			phandle = <0x119>;
		};
	};

	i2s@fe400000 {
		compatible = "rockchip,rk3568-i2s-tdm";
		reg = <0x00 0xfe400000 0x00 0x1000>;
		interrupts = <0x00 0x34 0x04>;
		assigned-clocks = <0x11 0x3d 0x11 0x41>;
		assigned-clock-rates = <0x46cf7100 0x46cf7100>;
		clocks = <0x11 0x3f 0x11 0x43 0x11 0x39>;
		clock-names = "mclk_tx\0mclk_rx\0hclk";
		dmas = <0x73 0x00>;
		dma-names = "tx";
		resets = <0x11 0x50 0x11 0x51>;
		reset-names = "tx-m\0rx-m";
		rockchip,grf = <0x21>;
		#sound-dai-cells = <0x00>;
		status = "okay";
		phandle = <0x0b>;
	};

	i2s@fe410000 {
		compatible = "rockchip,rk3568-i2s-tdm";
		reg = <0x00 0xfe410000 0x00 0x1000>;
		interrupts = <0x00 0x35 0x04>;
		assigned-clocks = <0x11 0x45 0x11 0x49>;
		assigned-clock-rates = <0x46cf7100 0x46cf7100>;
		clocks = <0x11 0x47 0x11 0x4b 0x11 0x3a>;
		clock-names = "mclk_tx\0mclk_rx\0hclk";
		dmas = <0x73 0x03 0x73 0x02>;
		dma-names = "rx\0tx";
		resets = <0x11 0x52 0x11 0x53>;
		reset-names = "tx-m\0rx-m";
		rockchip,grf = <0x21>;
		pinctrl-names = "default";
		pinctrl-0 = <0x74 0x75 0x76 0x77>;
		#sound-dai-cells = <0x00>;
		status = "okay";
		rockchip,trcm-sync-tx-only;
		phandle = <0xcc>;
	};

	i2s@fe420000 {
		compatible = "rockchip,rk3568-i2s-tdm";
		reg = <0x00 0xfe420000 0x00 0x1000>;
		interrupts = <0x00 0x36 0x04>;
		assigned-clocks = <0x11 0x4d>;
		assigned-clock-rates = <0x46cf7100>;
		clocks = <0x11 0x4f 0x11 0x4f 0x11 0x3b>;
		clock-names = "mclk_tx\0mclk_rx\0hclk";
		dmas = <0x73 0x04 0x73 0x05>;
		dma-names = "tx\0rx";
		resets = <0x11 0x54>;
		reset-names = "m";
		rockchip,grf = <0x21>;
		pinctrl-names = "default";
		pinctrl-0 = <0x78 0x79 0x7a 0x7b>;
		#sound-dai-cells = <0x00>;
		status = "disabled";
		phandle = <0x11a>;
	};

	i2s@fe430000 {
		compatible = "rockchip,rk3568-i2s-tdm";
		reg = <0x00 0xfe430000 0x00 0x1000>;
		interrupts = <0x00 0x37 0x04>;
		clocks = <0x11 0x53 0x11 0x57 0x11 0x3c>;
		clock-names = "mclk_tx\0mclk_rx\0hclk";
		dmas = <0x73 0x06 0x73 0x07>;
		dma-names = "tx\0rx";
		resets = <0x11 0x55 0x11 0x56>;
		reset-names = "tx-m\0rx-m";
		rockchip,grf = <0x21>;
		#sound-dai-cells = <0x00>;
		status = "disabled";
		phandle = <0x11b>;
	};

	pdm@fe440000 {
		compatible = "rockchip,rk3568-pdm";
		reg = <0x00 0xfe440000 0x00 0x1000>;
		interrupts = <0x00 0x4c 0x04>;
		clocks = <0x11 0x5a 0x11 0x59>;
		clock-names = "pdm_clk\0pdm_hclk";
		dmas = <0x73 0x09>;
		dma-names = "rx";
		pinctrl-0 = <0x7c 0x7d 0x7e 0x7f 0x80 0x81>;
		pinctrl-names = "default";
		resets = <0x11 0x58>;
		reset-names = "pdm-m";
		#sound-dai-cells = <0x00>;
		status = "disabled";
		phandle = <0x11c>;
	};

	spdif@fe460000 {
		compatible = "rockchip,rk3568-spdif";
		reg = <0x00 0xfe460000 0x00 0x1000>;
		interrupts = <0x00 0x66 0x04>;
		clock-names = "mclk\0hclk";
		clocks = <0x11 0x5f 0x11 0x5c>;
		dmas = <0x73 0x01>;
		dma-names = "tx";
		pinctrl-names = "default";
		pinctrl-0 = <0x82>;
		#sound-dai-cells = <0x00>;
		status = "disabled";
		phandle = <0x11d>;
	};

	dma-controller@fe530000 {
		compatible = "arm,pl330\0arm,primecell";
		reg = <0x00 0xfe530000 0x00 0x4000>;
		interrupts = <0x00 0x0e 0x04 0x00 0x0d 0x04>;
		arm,pl330-periph-burst;
		clocks = <0x11 0x10d>;
		clock-names = "apb_pclk";
		#dma-cells = <0x01>;
		phandle = <0x2d>;
	};

	dma-controller@fe550000 {
		compatible = "arm,pl330\0arm,primecell";
		reg = <0x00 0xfe550000 0x00 0x4000>;
		interrupts = <0x00 0x10 0x04 0x00 0x0f 0x04>;
		arm,pl330-periph-burst;
		clocks = <0x11 0x10d>;
		clock-names = "apb_pclk";
		#dma-cells = <0x01>;
		phandle = <0x73>;
	};

	i2c@fe5a0000 {
		compatible = "rockchip,rk3568-i2c\0rockchip,rk3399-i2c";
		reg = <0x00 0xfe5a0000 0x00 0x1000>;
		interrupts = <0x00 0x2f 0x04>;
		clocks = <0x11 0x148 0x11 0x147>;
		clock-names = "i2c\0pclk";
		pinctrl-0 = <0x83>;
		pinctrl-names = "default";
		#address-cells = <0x01>;
		#size-cells = <0x00>;
		status = "disabled";
		phandle = <0x11e>;
	};

	i2c@fe5b0000 {
		compatible = "rockchip,rk3568-i2c\0rockchip,rk3399-i2c";
		reg = <0x00 0xfe5b0000 0x00 0x1000>;
		interrupts = <0x00 0x30 0x04>;
		clocks = <0x11 0x14a 0x11 0x149>;
		clock-names = "i2c\0pclk";
		pinctrl-0 = <0x84>;
		pinctrl-names = "default";
		#address-cells = <0x01>;
		#size-cells = <0x00>;
		status = "disabled";
		phandle = <0x11f>;
	};

	i2c@fe5c0000 {
		compatible = "rockchip,rk3568-i2c\0rockchip,rk3399-i2c";
		reg = <0x00 0xfe5c0000 0x00 0x1000>;
		interrupts = <0x00 0x31 0x04>;
		clocks = <0x11 0x14c 0x11 0x14b>;
		clock-names = "i2c\0pclk";
		pinctrl-0 = <0x85>;
		pinctrl-names = "default";
		#address-cells = <0x01>;
		#size-cells = <0x00>;
		status = "disabled";
		phandle = <0x120>;
	};

	i2c@fe5d0000 {
		compatible = "rockchip,rk3568-i2c\0rockchip,rk3399-i2c";
		reg = <0x00 0xfe5d0000 0x00 0x1000>;
		interrupts = <0x00 0x32 0x04>;
		clocks = <0x11 0x14e 0x11 0x14d>;
		clock-names = "i2c\0pclk";
		pinctrl-0 = <0x86>;
		pinctrl-names = "default";
		#address-cells = <0x01>;
		#size-cells = <0x00>;
		status = "disabled";
		phandle = <0x121>;
	};

	i2c@fe5e0000 {
		compatible = "rockchip,rk3568-i2c\0rockchip,rk3399-i2c";
		reg = <0x00 0xfe5e0000 0x00 0x1000>;
		interrupts = <0x00 0x33 0x04>;
		clocks = <0x11 0x150 0x11 0x14f>;
		clock-names = "i2c\0pclk";
		pinctrl-0 = <0x87>;
		pinctrl-names = "default";
		#address-cells = <0x01>;
		#size-cells = <0x00>;
		status = "disabled";
		phandle = <0x122>;
	};

	watchdog@fe600000 {
		compatible = "rockchip,rk3568-wdt\0snps,dw-wdt";
		reg = <0x00 0xfe600000 0x00 0x100>;
		interrupts = <0x00 0x95 0x04>;
		clocks = <0x11 0x116 0x11 0x115>;
		clock-names = "tclk\0pclk";
		phandle = <0x123>;
	};

	spi@fe610000 {
		compatible = "rockchip,rk3568-spi\0rockchip,rk3066-spi";
		reg = <0x00 0xfe610000 0x00 0x1000>;
		interrupts = <0x00 0x67 0x04>;
		clocks = <0x11 0x152 0x11 0x151>;
		clock-names = "spiclk\0apb_pclk";
		dmas = <0x2d 0x14 0x2d 0x15>;
		dma-names = "tx\0rx";
		pinctrl-names = "default";
		pinctrl-0 = <0x88 0x89 0x8a>;
		#address-cells = <0x01>;
		#size-cells = <0x00>;
		status = "disabled";
		phandle = <0x124>;
	};

	spi@fe620000 {
		compatible = "rockchip,rk3568-spi\0rockchip,rk3066-spi";
		reg = <0x00 0xfe620000 0x00 0x1000>;
		interrupts = <0x00 0x68 0x04>;
		clocks = <0x11 0x154 0x11 0x153>;
		clock-names = "spiclk\0apb_pclk";
		dmas = <0x2d 0x16 0x2d 0x17>;
		dma-names = "tx\0rx";
		pinctrl-names = "default";
		pinctrl-0 = <0x8b 0x8c 0x8d>;
		#address-cells = <0x01>;
		#size-cells = <0x00>;
		status = "disabled";
		phandle = <0x125>;
	};

	spi@fe630000 {
		compatible = "rockchip,rk3568-spi\0rockchip,rk3066-spi";
		reg = <0x00 0xfe630000 0x00 0x1000>;
		interrupts = <0x00 0x69 0x04>;
		clocks = <0x11 0x156 0x11 0x155>;
		clock-names = "spiclk\0apb_pclk";
		dmas = <0x2d 0x18 0x2d 0x19>;
		dma-names = "tx\0rx";
		pinctrl-names = "default";
		pinctrl-0 = <0x8e 0x8f 0x90>;
		#address-cells = <0x01>;
		#size-cells = <0x00>;
		status = "disabled";
		phandle = <0x126>;
	};

	spi@fe640000 {
		compatible = "rockchip,rk3568-spi\0rockchip,rk3066-spi";
		reg = <0x00 0xfe640000 0x00 0x1000>;
		interrupts = <0x00 0x6a 0x04>;
		clocks = <0x11 0x158 0x11 0x157>;
		clock-names = "spiclk\0apb_pclk";
		dmas = <0x2d 0x1a 0x2d 0x1b>;
		dma-names = "tx\0rx";
		pinctrl-names = "default";
		pinctrl-0 = <0x91 0x92>;
		#address-cells = <0x01>;
		#size-cells = <0x00>;
		status = "disabled";
		phandle = <0x127>;

		spi_dev@0 {
			compatible = "armbian,spi-dev";
			reg = <0x00>;
			spi-max-frequency = <0x2faf080>;
		};
	};

	serial@fe650000 {
		compatible = "rockchip,rk3568-uart\0snps,dw-apb-uart";
		reg = <0x00 0xfe650000 0x00 0x100>;
		interrupts = <0x00 0x75 0x04>;
		clocks = <0x11 0x11f 0x11 0x11c>;
		clock-names = "baudclk\0apb_pclk";
		dmas = <0x2d 0x02 0x2d 0x03>;
		pinctrl-0 = <0x93 0x94 0x95>;
		pinctrl-names = "default";
		reg-io-width = <0x04>;
		reg-shift = <0x02>;
		status = "okay";
		uart-has-rtscts;
		phandle = <0x128>;

		bluetooth {
			compatible = "brcm,bcm4345c5";
			clocks = <0x96 0x01>;
			clock-names = "lpo";
			device-wakeup-gpios = <0x97 0x11 0x00>;
			host-wakeup-gpios = <0x97 0x10 0x00>;
			shutdown-gpios = <0x97 0x0f 0x00>;
			pinctrl-names = "default";
			pinctrl-0 = <0x98 0x99 0x9a>;
		};
	};

	serial@fe660000 {
		compatible = "rockchip,rk3568-uart\0snps,dw-apb-uart";
		reg = <0x00 0xfe660000 0x00 0x100>;
		interrupts = <0x00 0x76 0x04>;
		clocks = <0x11 0x123 0x11 0x120>;
		clock-names = "baudclk\0apb_pclk";
		dmas = <0x2d 0x04 0x2d 0x05>;
		pinctrl-0 = <0x9b>;
		pinctrl-names = "default";
		reg-io-width = <0x04>;
		reg-shift = <0x02>;
		status = "okay";
		phandle = <0x129>;
	};

	serial@fe670000 {
		compatible = "rockchip,rk3568-uart\0snps,dw-apb-uart";
		reg = <0x00 0xfe670000 0x00 0x100>;
		interrupts = <0x00 0x77 0x04>;
		clocks = <0x11 0x127 0x11 0x124>;
		clock-names = "baudclk\0apb_pclk";
		dmas = <0x2d 0x06 0x2d 0x07>;
		pinctrl-0 = <0x9c>;
		pinctrl-names = "default";
		reg-io-width = <0x04>;
		reg-shift = <0x02>;
		status = "disabled";
		phandle = <0x12a>;
	};

	serial@fe680000 {
		compatible = "rockchip,rk3568-uart\0snps,dw-apb-uart";
		reg = <0x00 0xfe680000 0x00 0x100>;
		interrupts = <0x00 0x78 0x04>;
		clocks = <0x11 0x12b 0x11 0x128>;
		clock-names = "baudclk\0apb_pclk";
		dmas = <0x2d 0x08 0x2d 0x09>;
		pinctrl-0 = <0x9d>;
		pinctrl-names = "default";
		reg-io-width = <0x04>;
		reg-shift = <0x02>;
		status = "disabled";
		phandle = <0x12b>;
	};

	serial@fe690000 {
		compatible = "rockchip,rk3568-uart\0snps,dw-apb-uart";
		reg = <0x00 0xfe690000 0x00 0x100>;
		interrupts = <0x00 0x79 0x04>;
		clocks = <0x11 0x12f 0x11 0x12c>;
		clock-names = "baudclk\0apb_pclk";
		dmas = <0x2d 0x0a 0x2d 0x0b>;
		pinctrl-0 = <0x9e>;
		pinctrl-names = "default";
		reg-io-width = <0x04>;
		reg-shift = <0x02>;
		status = "disabled";
		phandle = <0x12c>;
	};

	serial@fe6a0000 {
		compatible = "rockchip,rk3568-uart\0snps,dw-apb-uart";
		reg = <0x00 0xfe6a0000 0x00 0x100>;
		interrupts = <0x00 0x7a 0x04>;
		clocks = <0x11 0x133 0x11 0x130>;
		clock-names = "baudclk\0apb_pclk";
		dmas = <0x2d 0x0c 0x2d 0x0d>;
		pinctrl-0 = <0x9f>;
		pinctrl-names = "default";
		reg-io-width = <0x04>;
		reg-shift = <0x02>;
		status = "disabled";
		phandle = <0x12d>;
	};

	serial@fe6b0000 {
		compatible = "rockchip,rk3568-uart\0snps,dw-apb-uart";
		reg = <0x00 0xfe6b0000 0x00 0x100>;
		interrupts = <0x00 0x7b 0x04>;
		clocks = <0x11 0x137 0x11 0x134>;
		clock-names = "baudclk\0apb_pclk";
		dmas = <0x2d 0x0e 0x2d 0x0f>;
		pinctrl-0 = <0xa0>;
		pinctrl-names = "default";
		reg-io-width = <0x04>;
		reg-shift = <0x02>;
		status = "disabled";
		phandle = <0x12e>;
	};

	serial@fe6c0000 {
		compatible = "rockchip,rk3568-uart\0snps,dw-apb-uart";
		reg = <0x00 0xfe6c0000 0x00 0x100>;
		interrupts = <0x00 0x7c 0x04>;
		clocks = <0x11 0x13b 0x11 0x138>;
		clock-names = "baudclk\0apb_pclk";
		dmas = <0x2d 0x10 0x2d 0x11>;
		pinctrl-0 = <0xa1>;
		pinctrl-names = "default";
		reg-io-width = <0x04>;
		reg-shift = <0x02>;
		status = "disabled";
		phandle = <0x12f>;
	};

	serial@fe6d0000 {
		compatible = "rockchip,rk3568-uart\0snps,dw-apb-uart";
		reg = <0x00 0xfe6d0000 0x00 0x100>;
		interrupts = <0x00 0x7d 0x04>;
		clocks = <0x11 0x13f 0x11 0x13c>;
		clock-names = "baudclk\0apb_pclk";
		dmas = <0x2d 0x12 0x2d 0x13>;
		pinctrl-0 = <0xa2>;
		pinctrl-names = "default";
		reg-io-width = <0x04>;
		reg-shift = <0x02>;
		status = "disabled";
		phandle = <0x130>;
	};

	thermal-zones {
		phandle = <0x131>;

		cpu-thermal {
			polling-delay-passive = <0x64>;
			polling-delay = <0x3e8>;
			thermal-sensors = <0xa3 0x00>;
			phandle = <0x132>;

			trips {

				cpu_alert0 {
					temperature = <0x11170>;
					hysteresis = <0x7d0>;
					type = "passive";
					phandle = <0xa4>;
				};

				cpu_alert1 {
					temperature = <0x124f8>;
					hysteresis = <0x7d0>;
					type = "passive";
					phandle = <0x133>;
				};

				cpu_crit {
					temperature = <0x17318>;
					hysteresis = <0x7d0>;
					type = "critical";
					phandle = <0x134>;
				};
			};

			cooling-maps {

				map0 {
					trip = <0xa4>;
					cooling-device = <0x0c 0xffffffff 0xffffffff 0x0d 0xffffffff 0xffffffff 0x0e 0xffffffff 0xffffffff 0x0f 0xffffffff 0xffffffff>;
				};
			};
		};

		gpu-thermal {
			polling-delay-passive = <0x14>;
			polling-delay = <0x3e8>;
			thermal-sensors = <0xa3 0x01>;
			phandle = <0x135>;

			trips {

				gpu-threshold {
					temperature = <0x11170>;
					hysteresis = <0x7d0>;
					type = "passive";
					phandle = <0x136>;
				};

				gpu-target {
					temperature = <0x124f8>;
					hysteresis = <0x7d0>;
					type = "passive";
					phandle = <0xa5>;
				};

				gpu-crit {
					temperature = <0x17318>;
					hysteresis = <0x7d0>;
					type = "critical";
					phandle = <0x137>;
				};
			};

			cooling-maps {

				map0 {
					trip = <0xa5>;
					cooling-device = <0xa6 0xffffffff 0xffffffff>;
				};
			};
		};
	};

	tsadc@fe710000 {
		compatible = "rockchip,rk3568-tsadc";
		reg = <0x00 0xfe710000 0x00 0x100>;
		interrupts = <0x00 0x73 0x04>;
		assigned-clocks = <0x11 0x110 0x11 0x111>;
		assigned-clock-rates = <0x1036640 0xaae60>;
		clocks = <0x11 0x111 0x11 0x10f>;
		clock-names = "tsadc\0apb_pclk";
		resets = <0x11 0x181 0x11 0x182 0x11 0x1d7>;
		rockchip,grf = <0x21>;
		rockchip,hw-tshut-temp = <0x17318>;
		pinctrl-names = "init\0default\0sleep";
		pinctrl-0 = <0xa7>;
		pinctrl-1 = <0xa8>;
		pinctrl-2 = <0xa7>;
		#thermal-sensor-cells = <0x01>;
		status = "okay";
		phandle = <0xa3>;
	};

	saradc@fe720000 {
		compatible = "rockchip,rk3568-saradc\0rockchip,rk3399-saradc";
		reg = <0x00 0xfe720000 0x00 0x100>;
		interrupts = <0x00 0x5d 0x04>;
		clocks = <0x11 0x113 0x11 0x112>;
		clock-names = "saradc\0apb_pclk";
		resets = <0x11 0x180>;
		reset-names = "saradc-apb";
		#io-channel-cells = <0x01>;
		status = "okay";
		vref-supply = <0xa9>;
		phandle = <0x138>;
	};

	pwm@fe6e0000 {
		compatible = "rockchip,rk3568-pwm\0rockchip,rk3328-pwm";
		reg = <0x00 0xfe6e0000 0x00 0x10>;
		clocks = <0x11 0x15a 0x11 0x159>;
		clock-names = "pwm\0pclk";
		pinctrl-0 = <0xaa>;
		pinctrl-names = "default";
		#pwm-cells = <0x03>;
		status = "disabled";
		phandle = <0x139>;
	};

	pwm@fe6e0010 {
		compatible = "rockchip,rk3568-pwm\0rockchip,rk3328-pwm";
		reg = <0x00 0xfe6e0010 0x00 0x10>;
		clocks = <0x11 0x15a 0x11 0x159>;
		clock-names = "pwm\0pclk";
		pinctrl-0 = <0xab>;
		pinctrl-names = "default";
		#pwm-cells = <0x03>;
		status = "disabled";
		phandle = <0x13a>;
	};

	pwm@fe6e0020 {
		compatible = "rockchip,rk3568-pwm\0rockchip,rk3328-pwm";
		reg = <0x00 0xfe6e0020 0x00 0x10>;
		clocks = <0x11 0x15a 0x11 0x159>;
		clock-names = "pwm\0pclk";
		pinctrl-0 = <0xac>;
		pinctrl-names = "default";
		#pwm-cells = <0x03>;
		status = "disabled";
		phandle = <0x13b>;
	};

	pwm@fe6e0030 {
		compatible = "rockchip,rk3568-pwm\0rockchip,rk3328-pwm";
		reg = <0x00 0xfe6e0030 0x00 0x10>;
		clocks = <0x11 0x15a 0x11 0x159>;
		clock-names = "pwm\0pclk";
		pinctrl-0 = <0xad>;
		pinctrl-names = "default";
		#pwm-cells = <0x03>;
		status = "okay";
		phandle = <0xc9>;
	};

	pwm@fe6f0000 {
		compatible = "rockchip,rk3568-pwm\0rockchip,rk3328-pwm";
		reg = <0x00 0xfe6f0000 0x00 0x10>;
		clocks = <0x11 0x15d 0x11 0x15c>;
		clock-names = "pwm\0pclk";
		pinctrl-0 = <0xae>;
		pinctrl-names = "default";
		#pwm-cells = <0x03>;
		status = "disabled";
		phandle = <0x13c>;
	};

	pwm@fe6f0010 {
		compatible = "rockchip,rk3568-pwm\0rockchip,rk3328-pwm";
		reg = <0x00 0xfe6f0010 0x00 0x10>;
		clocks = <0x11 0x15d 0x11 0x15c>;
		clock-names = "pwm\0pclk";
		pinctrl-0 = <0xaf>;
		pinctrl-names = "default";
		#pwm-cells = <0x03>;
		status = "disabled";
		phandle = <0x13d>;
	};

	pwm@fe6f0020 {
		compatible = "rockchip,rk3568-pwm\0rockchip,rk3328-pwm";
		reg = <0x00 0xfe6f0020 0x00 0x10>;
		clocks = <0x11 0x15d 0x11 0x15c>;
		clock-names = "pwm\0pclk";
		pinctrl-0 = <0xb0>;
		pinctrl-names = "default";
		#pwm-cells = <0x03>;
		status = "disabled";
		phandle = <0x13e>;
	};

	pwm@fe6f0030 {
		compatible = "rockchip,rk3568-pwm\0rockchip,rk3328-pwm";
		reg = <0x00 0xfe6f0030 0x00 0x10>;
		clocks = <0x11 0x15d 0x11 0x15c>;
		clock-names = "pwm\0pclk";
		pinctrl-0 = <0xb1>;
		pinctrl-names = "default";
		#pwm-cells = <0x03>;
		status = "disabled";
		phandle = <0x13f>;
	};

	pwm@fe700000 {
		compatible = "rockchip,rk3568-pwm\0rockchip,rk3328-pwm";
		reg = <0x00 0xfe700000 0x00 0x10>;
		clocks = <0x11 0x160 0x11 0x15f>;
		clock-names = "pwm\0pclk";
		pinctrl-0 = <0xb2>;
		pinctrl-names = "default";
		#pwm-cells = <0x03>;
		status = "disabled";
		phandle = <0x140>;
	};

	pwm@fe700010 {
		compatible = "rockchip,rk3568-pwm\0rockchip,rk3328-pwm";
		reg = <0x00 0xfe700010 0x00 0x10>;
		clocks = <0x11 0x160 0x11 0x15f>;
		clock-names = "pwm\0pclk";
		pinctrl-0 = <0xb3>;
		pinctrl-names = "default";
		#pwm-cells = <0x03>;
		status = "disabled";
		phandle = <0x141>;
	};

	pwm@fe700020 {
		compatible = "rockchip,rk3568-pwm\0rockchip,rk3328-pwm";
		reg = <0x00 0xfe700020 0x00 0x10>;
		clocks = <0x11 0x160 0x11 0x15f>;
		clock-names = "pwm\0pclk";
		pinctrl-0 = <0xb4>;
		pinctrl-names = "default";
		#pwm-cells = <0x03>;
		status = "disabled";
		phandle = <0x142>;
	};

	pwm@fe700030 {
		compatible = "rockchip,rk3568-pwm\0rockchip,rk3328-pwm";
		reg = <0x00 0xfe700030 0x00 0x10>;
		clocks = <0x11 0x160 0x11 0x15f>;
		clock-names = "pwm\0pclk";
		pinctrl-0 = <0xb5>;
		pinctrl-names = "default";
		#pwm-cells = <0x03>;
		status = "disabled";
		phandle = <0x143>;
	};

	phy@fe830000 {
		compatible = "rockchip,rk3568-naneng-combphy";
		reg = <0x00 0xfe830000 0x00 0x100>;
		clocks = <0x20 0x22 0x11 0x17d 0x11 0x7f>;
		clock-names = "ref\0apb\0pipe";
		assigned-clocks = <0x20 0x22>;
		assigned-clock-rates = <0x5f5e100>;
		resets = <0x11 0x1c7>;
		rockchip,pipe-grf = <0xb6>;
		rockchip,pipe-phy-grf = <0xb7>;
		#phy-cells = <0x01>;
		status = "okay";
		phandle = <0x12>;
	};

	phy@fe840000 {
		compatible = "rockchip,rk3568-naneng-combphy";
		reg = <0x00 0xfe840000 0x00 0x100>;
		clocks = <0x20 0x25 0x11 0x17e 0x11 0x7f>;
		clock-names = "ref\0apb\0pipe";
		assigned-clocks = <0x20 0x25>;
		assigned-clock-rates = <0x5f5e100>;
		resets = <0x11 0x1c9>;
		rockchip,pipe-grf = <0xb6>;
		rockchip,pipe-phy-grf = <0xb8>;
		#phy-cells = <0x01>;
		status = "okay";
		phandle = <0x14>;
	};

	phy@fe870000 {
		compatible = "rockchip,rk3568-csi-dphy";
		reg = <0x00 0xfe870000 0x00 0x10000>;
		clocks = <0x11 0x179>;
		clock-names = "pclk";
		#phy-cells = <0x00>;
		resets = <0x11 0x1ba>;
		reset-names = "apb";
		rockchip,grf = <0x21>;
		status = "disabled";
		phandle = <0x144>;
	};

	mipi-dphy@fe850000 {
		compatible = "rockchip,rk3568-dsi-dphy";
		reg = <0x00 0xfe850000 0x00 0x10000>;
		clock-names = "ref\0pclk";
		clocks = <0x20 0x17 0x11 0x17a>;
		#phy-cells = <0x00>;
		power-domains = <0x13 0x09>;
		reset-names = "apb";
		resets = <0x11 0x1bb>;
		status = "disabled";
		phandle = <0x5b>;
	};

	mipi-dphy@fe860000 {
		compatible = "rockchip,rk3568-dsi-dphy";
		reg = <0x00 0xfe860000 0x00 0x10000>;
		clock-names = "ref\0pclk";
		clocks = <0x20 0x19 0x11 0x17b>;
		#phy-cells = <0x00>;
		power-domains = <0x13 0x09>;
		reset-names = "apb";
		resets = <0x11 0x1bc>;
		status = "disabled";
		phandle = <0x5c>;
	};

	usb2phy@fe8a0000 {
		compatible = "rockchip,rk3568-usb2phy";
		reg = <0x00 0xfe8a0000 0x00 0x10000>;
		clocks = <0x20 0x13>;
		clock-names = "phyclk";
		clock-output-names = "clk_usbphy0_480m";
		interrupts = <0x00 0x87 0x04>;
		rockchip,usbgrf = <0xb9>;
		#clock-cells = <0x00>;
		status = "okay";
		phandle = <0x16>;

		host-port {
			#phy-cells = <0x00>;
			status = "okay";
			phy-supply = <0xba>;
			phandle = <0x17>;
		};

		otg-port {
			#phy-cells = <0x00>;
			status = "okay";
			phandle = <0x15>;
		};
	};

	usb2phy@fe8b0000 {
		compatible = "rockchip,rk3568-usb2phy";
		reg = <0x00 0xfe8b0000 0x00 0x10000>;
		clocks = <0x20 0x15>;
		clock-names = "phyclk";
		clock-output-names = "clk_usbphy1_480m";
		interrupts = <0x00 0x88 0x04>;
		rockchip,usbgrf = <0xbb>;
		#clock-cells = <0x00>;
		status = "okay";
		phandle = <0x145>;

		host-port {
			#phy-cells = <0x00>;
			status = "okay";
			phandle = <0x19>;
		};

		otg-port {
			#phy-cells = <0x00>;
			status = "okay";
			phandle = <0x18>;
		};
	};

	pinctrl {
		compatible = "rockchip,rk3568-pinctrl";
		rockchip,grf = <0x21>;
		rockchip,pmu = <0xbc>;
		#address-cells = <0x02>;
		#size-cells = <0x02>;
		ranges;
		phandle = <0xbd>;

		gpio@fdd60000 {
			compatible = "rockchip,gpio-bank";
			reg = <0x00 0xfdd60000 0x00 0x100>;
			interrupts = <0x00 0x21 0x04>;
			clocks = <0x20 0x2e 0x20 0x0c>;
			gpio-controller;
			gpio-ranges = <0xbd 0x00 0x00 0x20>;
			#gpio-cells = <0x02>;
			interrupt-controller;
			#interrupt-cells = <0x02>;
			phandle = <0x24>;
		};

		gpio@fe740000 {
			compatible = "rockchip,gpio-bank";
			reg = <0x00 0xfe740000 0x00 0x100>;
			interrupts = <0x00 0x22 0x04>;
			clocks = <0x11 0x163 0x11 0x164>;
			gpio-controller;
			gpio-ranges = <0xbd 0x00 0x20 0x20>;
			#gpio-cells = <0x02>;
			interrupt-controller;
			#interrupt-cells = <0x02>;
			phandle = <0x146>;
		};

		gpio@fe750000 {
			compatible = "rockchip,gpio-bank";
			reg = <0x00 0xfe750000 0x00 0x100>;
			interrupts = <0x00 0x23 0x04>;
			clocks = <0x11 0x165 0x11 0x166>;
			gpio-controller;
			gpio-ranges = <0xbd 0x00 0x40 0x20>;
			#gpio-cells = <0x02>;
			interrupt-controller;
			#interrupt-cells = <0x02>;
			phandle = <0x97>;
		};

		gpio@fe760000 {
			compatible = "rockchip,gpio-bank";
			reg = <0x00 0xfe760000 0x00 0x100>;
			interrupts = <0x00 0x24 0x04>;
			clocks = <0x11 0x167 0x11 0x168>;
			gpio-controller;
			gpio-ranges = <0xbd 0x00 0x60 0x20>;
			#gpio-cells = <0x02>;
			interrupt-controller;
			#interrupt-cells = <0x02>;
			phandle = <0x147>;
		};

		gpio@fe770000 {
			compatible = "rockchip,gpio-bank";
			reg = <0x00 0xfe770000 0x00 0x100>;
			interrupts = <0x00 0x25 0x04>;
			clocks = <0x11 0x169 0x11 0x16a>;
			gpio-controller;
			gpio-ranges = <0xbd 0x00 0x80 0x20>;
			#gpio-cells = <0x02>;
			interrupt-controller;
			#interrupt-cells = <0x02>;
			phandle = <0x57>;
		};

		pcfg-pull-up {
			bias-pull-up;
			phandle = <0xc0>;
		};

		pcfg-pull-down {
			bias-pull-down;
			phandle = <0xc7>;
		};

		pcfg-pull-none {
			bias-disable;
			phandle = <0xbe>;
		};

		pcfg-pull-none-drv-level-0 {
			bias-disable;
			drive-strength = <0x00>;
			phandle = <0x148>;
		};

		pcfg-pull-none-drv-level-1 {
			bias-disable;
			drive-strength = <0x01>;
			phandle = <0xc2>;
		};

		pcfg-pull-none-drv-level-2 {
			bias-disable;
			drive-strength = <0x02>;
			phandle = <0xc1>;
		};

		pcfg-pull-none-drv-level-3 {
			bias-disable;
			drive-strength = <0x03>;
			phandle = <0xc6>;
		};

		pcfg-pull-none-drv-level-4 {
			bias-disable;
			drive-strength = <0x04>;
			phandle = <0x149>;
		};

		pcfg-pull-none-drv-level-5 {
			bias-disable;
			drive-strength = <0x05>;
			phandle = <0x14a>;
		};

		pcfg-pull-none-drv-level-6 {
			bias-disable;
			drive-strength = <0x06>;
			phandle = <0x14b>;
		};

		pcfg-pull-none-drv-level-7 {
			bias-disable;
			drive-strength = <0x07>;
			phandle = <0x14c>;
		};

		pcfg-pull-none-drv-level-8 {
			bias-disable;
			drive-strength = <0x08>;
			phandle = <0x14d>;
		};

		pcfg-pull-none-drv-level-9 {
			bias-disable;
			drive-strength = <0x09>;
			phandle = <0x14e>;
		};

		pcfg-pull-none-drv-level-10 {
			bias-disable;
			drive-strength = <0x0a>;
			phandle = <0x14f>;
		};

		pcfg-pull-none-drv-level-11 {
			bias-disable;
			drive-strength = <0x0b>;
			phandle = <0x150>;
		};

		pcfg-pull-none-drv-level-12 {
			bias-disable;
			drive-strength = <0x0c>;
			phandle = <0x151>;
		};

		pcfg-pull-none-drv-level-13 {
			bias-disable;
			drive-strength = <0x0d>;
			phandle = <0x152>;
		};

		pcfg-pull-none-drv-level-14 {
			bias-disable;
			drive-strength = <0x0e>;
			phandle = <0x153>;
		};

		pcfg-pull-none-drv-level-15 {
			bias-disable;
			drive-strength = <0x0f>;
			phandle = <0x154>;
		};

		pcfg-pull-up-drv-level-0 {
			bias-pull-up;
			drive-strength = <0x00>;
			phandle = <0x155>;
		};

		pcfg-pull-up-drv-level-1 {
			bias-pull-up;
			drive-strength = <0x01>;
			phandle = <0xc5>;
		};

		pcfg-pull-up-drv-level-2 {
			bias-pull-up;
			drive-strength = <0x02>;
			phandle = <0xbf>;
		};

		pcfg-pull-up-drv-level-3 {
			bias-pull-up;
			drive-strength = <0x03>;
			phandle = <0x156>;
		};

		pcfg-pull-up-drv-level-4 {
			bias-pull-up;
			drive-strength = <0x04>;
			phandle = <0x157>;
		};

		pcfg-pull-up-drv-level-5 {
			bias-pull-up;
			drive-strength = <0x05>;
			phandle = <0x158>;
		};

		pcfg-pull-up-drv-level-6 {
			bias-pull-up;
			drive-strength = <0x06>;
			phandle = <0x159>;
		};

		pcfg-pull-up-drv-level-7 {
			bias-pull-up;
			drive-strength = <0x07>;
			phandle = <0x15a>;
		};

		pcfg-pull-up-drv-level-8 {
			bias-pull-up;
			drive-strength = <0x08>;
			phandle = <0x15b>;
		};

		pcfg-pull-up-drv-level-9 {
			bias-pull-up;
			drive-strength = <0x09>;
			phandle = <0x15c>;
		};

		pcfg-pull-up-drv-level-10 {
			bias-pull-up;
			drive-strength = <0x0a>;
			phandle = <0x15d>;
		};

		pcfg-pull-up-drv-level-11 {
			bias-pull-up;
			drive-strength = <0x0b>;
			phandle = <0x15e>;
		};

		pcfg-pull-up-drv-level-12 {
			bias-pull-up;
			drive-strength = <0x0c>;
			phandle = <0x15f>;
		};

		pcfg-pull-up-drv-level-13 {
			bias-pull-up;
			drive-strength = <0x0d>;
			phandle = <0x160>;
		};

		pcfg-pull-up-drv-level-14 {
			bias-pull-up;
			drive-strength = <0x0e>;
			phandle = <0x161>;
		};

		pcfg-pull-up-drv-level-15 {
			bias-pull-up;
			drive-strength = <0x0f>;
			phandle = <0x162>;
		};

		pcfg-pull-down-drv-level-0 {
			bias-pull-down;
			drive-strength = <0x00>;
			phandle = <0x163>;
		};

		pcfg-pull-down-drv-level-1 {
			bias-pull-down;
			drive-strength = <0x01>;
			phandle = <0x164>;
		};

		pcfg-pull-down-drv-level-2 {
			bias-pull-down;
			drive-strength = <0x02>;
			phandle = <0x165>;
		};

		pcfg-pull-down-drv-level-3 {
			bias-pull-down;
			drive-strength = <0x03>;
			phandle = <0x166>;
		};

		pcfg-pull-down-drv-level-4 {
			bias-pull-down;
			drive-strength = <0x04>;
			phandle = <0x167>;
		};

		pcfg-pull-down-drv-level-5 {
			bias-pull-down;
			drive-strength = <0x05>;
			phandle = <0x168>;
		};

		pcfg-pull-down-drv-level-6 {
			bias-pull-down;
			drive-strength = <0x06>;
			phandle = <0x169>;
		};

		pcfg-pull-down-drv-level-7 {
			bias-pull-down;
			drive-strength = <0x07>;
			phandle = <0x16a>;
		};

		pcfg-pull-down-drv-level-8 {
			bias-pull-down;
			drive-strength = <0x08>;
			phandle = <0x16b>;
		};

		pcfg-pull-down-drv-level-9 {
			bias-pull-down;
			drive-strength = <0x09>;
			phandle = <0x16c>;
		};

		pcfg-pull-down-drv-level-10 {
			bias-pull-down;
			drive-strength = <0x0a>;
			phandle = <0x16d>;
		};

		pcfg-pull-down-drv-level-11 {
			bias-pull-down;
			drive-strength = <0x0b>;
			phandle = <0x16e>;
		};

		pcfg-pull-down-drv-level-12 {
			bias-pull-down;
			drive-strength = <0x0c>;
			phandle = <0x16f>;
		};

		pcfg-pull-down-drv-level-13 {
			bias-pull-down;
			drive-strength = <0x0d>;
			phandle = <0x170>;
		};

		pcfg-pull-down-drv-level-14 {
			bias-pull-down;
			drive-strength = <0x0e>;
			phandle = <0x171>;
		};

		pcfg-pull-down-drv-level-15 {
			bias-pull-down;
			drive-strength = <0x0f>;
			phandle = <0x172>;
		};

		pcfg-pull-up-smt {
			bias-pull-up;
			input-schmitt-enable;
			phandle = <0x173>;
		};

		pcfg-pull-down-smt {
			bias-pull-down;
			input-schmitt-enable;
			phandle = <0x174>;
		};

		pcfg-pull-none-smt {
			bias-disable;
			input-schmitt-enable;
			phandle = <0xc3>;
		};

		pcfg-pull-none-drv-level-0-smt {
			bias-disable;
			drive-strength = <0x00>;
			input-schmitt-enable;
			phandle = <0x175>;
		};

		pcfg-output-high {
			output-high;
			phandle = <0xc8>;
		};

		pcfg-output-low {
			output-low;
			phandle = <0xc4>;
		};

		acodec {

			acodec-pins {
				rockchip,pins = <0x01 0x09 0x05 0xbe 0x01 0x01 0x05 0xbe 0x01 0x00 0x05 0xbe 0x01 0x07 0x05 0xbe 0x01 0x08 0x05 0xbe 0x01 0x03 0x05 0xbe 0x01 0x05 0x05 0xbe>;
				phandle = <0x176>;
			};
		};

		audiopwm {

			audiopwm-lout {
				rockchip,pins = <0x01 0x00 0x04 0xbe>;
				phandle = <0x177>;
			};

			audiopwm-loutn {
				rockchip,pins = <0x01 0x01 0x06 0xbe>;
				phandle = <0x178>;
			};

			audiopwm-loutp {
				rockchip,pins = <0x01 0x00 0x06 0xbe>;
				phandle = <0x179>;
			};

			audiopwm-rout {
				rockchip,pins = <0x01 0x01 0x04 0xbe>;
				phandle = <0x17a>;
			};

			audiopwm-routn {
				rockchip,pins = <0x01 0x07 0x04 0xbe>;
				phandle = <0x17b>;
			};

			audiopwm-routp {
				rockchip,pins = <0x01 0x06 0x04 0xbe>;
				phandle = <0x17c>;
			};
		};

		bt656 {

			bt656m0-pins {
				rockchip,pins = <0x03 0x00 0x02 0xbe 0x02 0x18 0x02 0xbe 0x02 0x19 0x02 0xbe 0x02 0x1a 0x02 0xbe 0x02 0x1b 0x02 0xbe 0x02 0x1c 0x02 0xbe 0x02 0x1d 0x02 0xbe 0x02 0x1e 0x02 0xbe 0x02 0x1f 0x02 0xbe>;
				phandle = <0x17d>;
			};

			bt656m1-pins {
				rockchip,pins = <0x04 0x0c 0x05 0xbe 0x03 0x16 0x05 0xbe 0x03 0x17 0x05 0xbe 0x03 0x18 0x05 0xbe 0x03 0x19 0x05 0xbe 0x03 0x1a 0x05 0xbe 0x03 0x1b 0x05 0xbe 0x03 0x1c 0x05 0xbe 0x03 0x1d 0x05 0xbe>;
				phandle = <0x17e>;
			};
		};

		bt1120 {

			bt1120-pins {
				rockchip,pins = <0x03 0x06 0x02 0xbe 0x03 0x01 0x02 0xbe 0x03 0x02 0x02 0xbe 0x03 0x03 0x02 0xbe 0x03 0x04 0x02 0xbe 0x03 0x05 0x02 0xbe 0x03 0x07 0x02 0xbe 0x03 0x08 0x02 0xbe 0x03 0x09 0x02 0xbe 0x03 0x0a 0x02 0xbe 0x03 0x0b 0x02 0xbe 0x03 0x0c 0x02 0xbe 0x03 0x0d 0x02 0xbe 0x03 0x0e 0x02 0xbe 0x03 0x11 0x02 0xbe 0x03 0x12 0x02 0xbe 0x03 0x13 0x02 0xbe>;
				phandle = <0x17f>;
			};
		};

		cam {

			cam-clkout0 {
				rockchip,pins = <0x04 0x07 0x01 0xbe>;
				phandle = <0x180>;
			};

			cam-clkout1 {
				rockchip,pins = <0x04 0x08 0x01 0xbe>;
				phandle = <0x181>;
			};
		};

		can0 {

			can0m0-pins {
				rockchip,pins = <0x00 0x0c 0x02 0xbe 0x00 0x0b 0x02 0xbe>;
				phandle = <0x182>;
			};

			can0m1-pins {
				rockchip,pins = <0x02 0x02 0x04 0xbe 0x02 0x01 0x04 0xbe>;
				phandle = <0x183>;
			};
		};

		can1 {

			can1m0-pins {
				rockchip,pins = <0x01 0x00 0x03 0xbe 0x01 0x01 0x03 0xbe>;
				phandle = <0x184>;
			};

			can1m1-pins {
				rockchip,pins = <0x04 0x12 0x03 0xbe 0x04 0x13 0x03 0xbe>;
				phandle = <0x185>;
			};
		};

		can2 {

			can2m0-pins {
				rockchip,pins = <0x04 0x0c 0x03 0xbe 0x04 0x0d 0x03 0xbe>;
				phandle = <0x186>;
			};

			can2m1-pins {
				rockchip,pins = <0x02 0x09 0x04 0xbe 0x02 0x0a 0x04 0xbe>;
				phandle = <0x187>;
			};
		};

		cif {

			cif-clk {
				rockchip,pins = <0x04 0x10 0x01 0xbe>;
				phandle = <0x188>;
			};

			cif-dvp-clk {
				rockchip,pins = <0x04 0x11 0x01 0xbe 0x04 0x0e 0x01 0xbe 0x04 0x0f 0x01 0xbe>;
				phandle = <0x189>;
			};

			cif-dvp-bus16 {
				rockchip,pins = <0x03 0x1e 0x01 0xbe 0x03 0x1f 0x01 0xbe 0x04 0x00 0x01 0xbe 0x04 0x01 0x01 0xbe 0x04 0x02 0x01 0xbe 0x04 0x03 0x01 0xbe 0x04 0x04 0x01 0xbe 0x04 0x05 0x01 0xbe>;
				phandle = <0x18a>;
			};

			cif-dvp-bus8 {
				rockchip,pins = <0x03 0x16 0x01 0xbe 0x03 0x17 0x01 0xbe 0x03 0x18 0x01 0xbe 0x03 0x19 0x01 0xbe 0x03 0x1a 0x01 0xbe 0x03 0x1b 0x01 0xbe 0x03 0x1c 0x01 0xbe 0x03 0x1d 0x01 0xbe>;
				phandle = <0x18b>;
			};
		};

		clk32k {

			clk32k-in {
				rockchip,pins = <0x00 0x08 0x01 0xbe>;
				phandle = <0x18c>;
			};

			clk32k-out0 {
				rockchip,pins = <0x00 0x08 0x02 0xbe>;
				phandle = <0x10>;
			};

			clk32k-out1 {
				rockchip,pins = <0x02 0x16 0x01 0xbe>;
				phandle = <0x18d>;
			};
		};

		cpu {

			cpu-pins {
				rockchip,pins = <0x00 0x0f 0x02 0xbe>;
				phandle = <0x18e>;
			};
		};

		ebc {

			ebc-extern {
				rockchip,pins = <0x04 0x07 0x02 0xbe 0x04 0x08 0x02 0xbe 0x04 0x09 0x02 0xbe 0x04 0x0d 0x02 0xbe 0x04 0x0a 0x02 0xbe>;
				phandle = <0x18f>;
			};

			ebc-pins {
				rockchip,pins = <0x04 0x10 0x02 0xbe 0x04 0x0b 0x02 0xbe 0x04 0x0c 0x02 0xbe 0x04 0x06 0x02 0xbe 0x04 0x11 0x02 0xbe 0x03 0x16 0x02 0xbe 0x03 0x17 0x02 0xbe 0x03 0x18 0x02 0xbe 0x03 0x19 0x02 0xbe 0x03 0x1a 0x02 0xbe 0x03 0x1b 0x02 0xbe 0x03 0x1c 0x02 0xbe 0x03 0x1d 0x02 0xbe 0x03 0x1e 0x02 0xbe 0x03 0x1f 0x02 0xbe 0x04 0x00 0x02 0xbe 0x04 0x01 0x02 0xbe 0x04 0x02 0x02 0xbe 0x04 0x03 0x02 0xbe 0x04 0x04 0x02 0xbe 0x04 0x05 0x02 0xbe 0x04 0x0e 0x02 0xbe 0x04 0x0f 0x02 0xbe>;
				phandle = <0x190>;
			};
		};

		edpdp {

			edpdpm0-pins {
				rockchip,pins = <0x04 0x14 0x01 0xbe>;
				phandle = <0x191>;
			};

			edpdpm1-pins {
				rockchip,pins = <0x00 0x12 0x02 0xbe>;
				phandle = <0x192>;
			};
		};

		emmc {

			emmc-rstnout {
				rockchip,pins = <0x01 0x17 0x01 0xbe>;
				phandle = <0x193>;
			};

			emmc-bus8 {
				rockchip,pins = <0x01 0x0c 0x01 0xbf 0x01 0x0d 0x01 0xbf 0x01 0x0e 0x01 0xbf 0x01 0x0f 0x01 0xbf 0x01 0x10 0x01 0xbf 0x01 0x11 0x01 0xbf 0x01 0x12 0x01 0xbf 0x01 0x13 0x01 0xbf>;
				phandle = <0x70>;
			};

			emmc-clk {
				rockchip,pins = <0x01 0x15 0x01 0xbf>;
				phandle = <0x71>;
			};

			emmc-cmd {
				rockchip,pins = <0x01 0x14 0x01 0xbf>;
				phandle = <0x72>;
			};

			emmc-datastrobe {
				rockchip,pins = <0x01 0x16 0x01 0xbe>;
				phandle = <0x194>;
			};
		};

		eth0 {

			eth0-pins {
				rockchip,pins = <0x02 0x11 0x02 0xbe>;
				phandle = <0x195>;
			};
		};

		eth1 {

			eth1m0-pins {
				rockchip,pins = <0x03 0x08 0x03 0xbe>;
				phandle = <0x196>;
			};

			eth1m1-pins {
				rockchip,pins = <0x04 0x0b 0x03 0xbe>;
				phandle = <0x197>;
			};
		};

		flash {

			flash-pins {
				rockchip,pins = <0x01 0x18 0x02 0xbe 0x01 0x16 0x03 0xbe 0x01 0x1b 0x02 0xbe 0x01 0x1c 0x02 0xbe 0x01 0x0c 0x02 0xbe 0x01 0x0d 0x02 0xbe 0x01 0x0e 0x02 0xbe 0x01 0x0f 0x02 0xbe 0x01 0x10 0x02 0xbe 0x01 0x11 0x02 0xbe 0x01 0x12 0x02 0xbe 0x01 0x13 0x02 0xbe 0x01 0x15 0x02 0xbe 0x01 0x1a 0x02 0xbe 0x01 0x19 0x02 0xbe 0x00 0x07 0x01 0xbe 0x01 0x17 0x03 0xbe 0x01 0x14 0x02 0xbe>;
				phandle = <0x198>;
			};
		};

		fspi {

			fspi-pins {
				rockchip,pins = <0x01 0x18 0x01 0xbe 0x01 0x1b 0x01 0xbe 0x01 0x19 0x01 0xbe 0x01 0x1a 0x01 0xbe 0x01 0x17 0x02 0xbe 0x01 0x1c 0x01 0xbe>;
				phandle = <0x6f>;
			};

			fspi-cs1 {
				rockchip,pins = <0x01 0x16 0x02 0xc0>;
				phandle = <0x199>;
			};
		};

		gmac0 {

			gmac0-miim {
				rockchip,pins = <0x02 0x13 0x02 0xbe 0x02 0x14 0x02 0xbe>;
				phandle = <0x19a>;
			};

			gmac0-clkinout {
				rockchip,pins = <0x02 0x12 0x02 0xbe>;
				phandle = <0x19b>;
			};

			gmac0-rx-er {
				rockchip,pins = <0x02 0x15 0x02 0xbe>;
				phandle = <0x19c>;
			};

			gmac0-rx-bus2 {
				rockchip,pins = <0x02 0x0e 0x01 0xbe 0x02 0x0f 0x02 0xbe 0x02 0x10 0x02 0xbe>;
				phandle = <0x19d>;
			};

			gmac0-tx-bus2 {
				rockchip,pins = <0x02 0x0b 0x01 0xc1 0x02 0x0c 0x01 0xc1 0x02 0x0d 0x01 0xbe>;
				phandle = <0x19e>;
			};

			gmac0-rgmii-clk {
				rockchip,pins = <0x02 0x05 0x02 0xbe 0x02 0x08 0x02 0xc2>;
				phandle = <0x19f>;
			};

			gmac0-rgmii-bus {
				rockchip,pins = <0x02 0x03 0x02 0xbe 0x02 0x04 0x02 0xbe 0x02 0x06 0x02 0xc1 0x02 0x07 0x02 0xc1>;
				phandle = <0x1a0>;
			};
		};

		gmac1 {

			gmac1m0-miim {
				rockchip,pins = <0x03 0x14 0x03 0xbe 0x03 0x15 0x03 0xbe>;
				phandle = <0x51>;
			};

			gmac1m0-clkinout {
				rockchip,pins = <0x03 0x10 0x03 0xbe>;
				phandle = <0x55>;
			};

			gmac1m0-rx-er {
				rockchip,pins = <0x03 0x0c 0x03 0xbe>;
				phandle = <0x1a1>;
			};

			gmac1m0-rx-bus2 {
				rockchip,pins = <0x03 0x09 0x03 0xbe 0x03 0x0a 0x03 0xbe 0x03 0x0b 0x03 0xbe>;
				phandle = <0x53>;
			};

			gmac1m0-tx-bus2 {
				rockchip,pins = <0x03 0x0d 0x03 0xc1 0x03 0x0e 0x03 0xc1 0x03 0x0f 0x03 0xbe>;
				phandle = <0x52>;
			};

			gmac1m0-rgmii-clk {
				rockchip,pins = <0x03 0x07 0x03 0xbe 0x03 0x06 0x03 0xc2>;
				phandle = <0x54>;
			};

			gmac1m0-rgmii-bus {
				rockchip,pins = <0x03 0x04 0x03 0xbe 0x03 0x05 0x03 0xbe 0x03 0x02 0x03 0xc1 0x03 0x03 0x03 0xc1>;
				phandle = <0x56>;
			};

			gmac1m1-miim {
				rockchip,pins = <0x04 0x0e 0x03 0xbe 0x04 0x0f 0x03 0xbe>;
				phandle = <0x1a2>;
			};

			gmac1m1-clkinout {
				rockchip,pins = <0x04 0x11 0x03 0xbe>;
				phandle = <0x1a3>;
			};

			gmac1m1-rx-er {
				rockchip,pins = <0x04 0x0a 0x03 0xbe>;
				phandle = <0x1a4>;
			};

			gmac1m1-rx-bus2 {
				rockchip,pins = <0x04 0x07 0x03 0xbe 0x04 0x08 0x03 0xbe 0x04 0x09 0x03 0xbe>;
				phandle = <0x1a5>;
			};

			gmac1m1-tx-bus2 {
				rockchip,pins = <0x04 0x04 0x03 0xc1 0x04 0x05 0x03 0xc1 0x04 0x06 0x03 0xbe>;
				phandle = <0x1a6>;
			};

			gmac1m1-rgmii-clk {
				rockchip,pins = <0x04 0x03 0x03 0xbe 0x04 0x00 0x03 0xc2>;
				phandle = <0x1a7>;
			};

			gmac1m1-rgmii-bus {
				rockchip,pins = <0x04 0x01 0x03 0xbe 0x04 0x02 0x03 0xbe 0x03 0x1e 0x03 0xc1 0x03 0x1f 0x03 0xc1>;
				phandle = <0x1a8>;
			};
		};

		gpu {

			gpu-pins {
				rockchip,pins = <0x00 0x10 0x02 0xbe 0x00 0x06 0x04 0xbe>;
				phandle = <0x1a9>;
			};
		};

		hdmitx {

			hdmitxm0-cec {
				rockchip,pins = <0x04 0x19 0x01 0xbe>;
				phandle = <0x5f>;
			};

			hdmitxm1-cec {
				rockchip,pins = <0x00 0x17 0x01 0xbe>;
				phandle = <0x1aa>;
			};

			hdmitx-scl {
				rockchip,pins = <0x04 0x17 0x01 0xbe>;
				phandle = <0x5d>;
			};

			hdmitx-sda {
				rockchip,pins = <0x04 0x18 0x01 0xbe>;
				phandle = <0x5e>;
			};
		};

		i2c0 {

			i2c0-xfer {
				rockchip,pins = <0x00 0x09 0x01 0xc3 0x00 0x0a 0x01 0xc3>;
				phandle = <0x22>;
			};
		};

		i2c1 {

			i2c1-xfer {
				rockchip,pins = <0x00 0x0b 0x01 0xc3 0x00 0x0c 0x01 0xc3>;
				phandle = <0x83>;
			};
		};

		i2c2 {

			i2c2m0-xfer {
				rockchip,pins = <0x00 0x0d 0x01 0xc3 0x00 0x0e 0x01 0xc3>;
				phandle = <0x1ab>;
			};

			i2c2m1-xfer {
				rockchip,pins = <0x04 0x0d 0x01 0xc3 0x04 0x0c 0x01 0xc3>;
				phandle = <0x84>;
			};
		};

		i2c3 {

			i2c3m0-xfer {
				rockchip,pins = <0x01 0x01 0x01 0xc3 0x01 0x00 0x01 0xc3>;
				phandle = <0x85>;
			};

			i2c3m1-xfer {
				rockchip,pins = <0x03 0x0d 0x04 0xc3 0x03 0x0e 0x04 0xc3>;
				phandle = <0x1ac>;
			};
		};

		i2c4 {

			i2c4m0-xfer {
				rockchip,pins = <0x04 0x0b 0x01 0xc3 0x04 0x0a 0x01 0xc3>;
				phandle = <0x86>;
			};

			i2c4m1-xfer {
				rockchip,pins = <0x02 0x0a 0x02 0xc3 0x02 0x09 0x02 0xc3>;
				phandle = <0x1ad>;
			};
		};

		i2c5 {

			i2c5m0-xfer {
				rockchip,pins = <0x03 0x0b 0x04 0xc3 0x03 0x0c 0x04 0xc3>;
				phandle = <0x87>;
			};

			i2c5m1-xfer {
				rockchip,pins = <0x04 0x17 0x02 0xc3 0x04 0x18 0x02 0xc3>;
				phandle = <0x1ae>;
			};
		};

		i2s1 {

			i2s1m0-lrckrx {
				rockchip,pins = <0x01 0x06 0x01 0xbe>;
				phandle = <0x1af>;
			};

			i2s1m0-lrcktx {
				rockchip,pins = <0x01 0x05 0x01 0xbe>;
				phandle = <0x75>;
			};

			i2s1m0-mclk {
				rockchip,pins = <0x01 0x02 0x01 0xbe>;
				phandle = <0x26>;
			};

			i2s1m0-sclkrx {
				rockchip,pins = <0x01 0x04 0x01 0xbe>;
				phandle = <0x1b0>;
			};

			i2s1m0-sclktx {
				rockchip,pins = <0x01 0x03 0x01 0xbe>;
				phandle = <0x74>;
			};

			i2s1m0-sdi0 {
				rockchip,pins = <0x01 0x0b 0x01 0xbe>;
				phandle = <0x76>;
			};

			i2s1m0-sdi1 {
				rockchip,pins = <0x01 0x0a 0x02 0xbe>;
				phandle = <0x1b1>;
			};

			i2s1m0-sdi2 {
				rockchip,pins = <0x01 0x09 0x02 0xbe>;
				phandle = <0x1b2>;
			};

			i2s1m0-sdi3 {
				rockchip,pins = <0x01 0x08 0x02 0xbe>;
				phandle = <0x1b3>;
			};

			i2s1m0-sdo0 {
				rockchip,pins = <0x01 0x07 0x01 0xbe>;
				phandle = <0x77>;
			};

			i2s1m0-sdo1 {
				rockchip,pins = <0x01 0x08 0x01 0xbe>;
				phandle = <0x1b4>;
			};

			i2s1m0-sdo2 {
				rockchip,pins = <0x01 0x09 0x01 0xbe>;
				phandle = <0x1b5>;
			};

			i2s1m0-sdo3 {
				rockchip,pins = <0x01 0x0a 0x01 0xbe>;
				phandle = <0x1b6>;
			};

			i2s1m1-lrckrx {
				rockchip,pins = <0x04 0x07 0x05 0xbe>;
				phandle = <0x1b7>;
			};

			i2s1m1-lrcktx {
				rockchip,pins = <0x03 0x18 0x04 0xbe>;
				phandle = <0x1b8>;
			};

			i2s1m1-mclk {
				rockchip,pins = <0x03 0x16 0x04 0xbe>;
				phandle = <0x1b9>;
			};

			i2s1m1-sclkrx {
				rockchip,pins = <0x04 0x06 0x05 0xbe>;
				phandle = <0x1ba>;
			};

			i2s1m1-sclktx {
				rockchip,pins = <0x03 0x17 0x04 0xbe>;
				phandle = <0x1bb>;
			};

			i2s1m1-sdi0 {
				rockchip,pins = <0x03 0x1a 0x04 0xbe>;
				phandle = <0x1bc>;
			};

			i2s1m1-sdi1 {
				rockchip,pins = <0x03 0x1b 0x04 0xbe>;
				phandle = <0x1bd>;
			};

			i2s1m1-sdi2 {
				rockchip,pins = <0x03 0x1c 0x04 0xbe>;
				phandle = <0x1be>;
			};

			i2s1m1-sdi3 {
				rockchip,pins = <0x03 0x1d 0x04 0xbe>;
				phandle = <0x1bf>;
			};

			i2s1m1-sdo0 {
				rockchip,pins = <0x03 0x19 0x04 0xbe>;
				phandle = <0x1c0>;
			};

			i2s1m1-sdo1 {
				rockchip,pins = <0x04 0x08 0x05 0xbe>;
				phandle = <0x1c1>;
			};

			i2s1m1-sdo2 {
				rockchip,pins = <0x04 0x09 0x04 0xbe>;
				phandle = <0x1c2>;
			};

			i2s1m1-sdo3 {
				rockchip,pins = <0x04 0x0d 0x04 0xbe>;
				phandle = <0x1c3>;
			};

			i2s1m2-lrckrx {
				rockchip,pins = <0x03 0x15 0x05 0xbe>;
				phandle = <0x1c4>;
			};

			i2s1m2-lrcktx {
				rockchip,pins = <0x02 0x1a 0x05 0xbe>;
				phandle = <0x1c5>;
			};

			i2s1m2-mclk {
				rockchip,pins = <0x02 0x18 0x05 0xbe>;
				phandle = <0x1c6>;
			};

			i2s1m2-sclkrx {
				rockchip,pins = <0x03 0x13 0x05 0xbe>;
				phandle = <0x1c7>;
			};

			i2s1m2-sclktx {
				rockchip,pins = <0x02 0x19 0x05 0xbe>;
				phandle = <0x1c8>;
			};

			i2s1m2-sdi0 {
				rockchip,pins = <0x02 0x1b 0x05 0xbe>;
				phandle = <0x1c9>;
			};

			i2s1m2-sdi1 {
				rockchip,pins = <0x02 0x1c 0x05 0xbe>;
				phandle = <0x1ca>;
			};

			i2s1m2-sdi2 {
				rockchip,pins = <0x02 0x1d 0x05 0xbe>;
				phandle = <0x1cb>;
			};

			i2s1m2-sdi3 {
				rockchip,pins = <0x02 0x1e 0x05 0xbe>;
				phandle = <0x1cc>;
			};

			i2s1m2-sdo0 {
				rockchip,pins = <0x02 0x1f 0x05 0xbe>;
				phandle = <0x1cd>;
			};

			i2s1m2-sdo1 {
				rockchip,pins = <0x03 0x00 0x05 0xbe>;
				phandle = <0x1ce>;
			};

			i2s1m2-sdo2 {
				rockchip,pins = <0x03 0x11 0x05 0xbe>;
				phandle = <0x1cf>;
			};

			i2s1m2-sdo3 {
				rockchip,pins = <0x03 0x12 0x05 0xbe>;
				phandle = <0x1d0>;
			};
		};

		i2s2 {

			i2s2m0-lrckrx {
				rockchip,pins = <0x02 0x10 0x01 0xbe>;
				phandle = <0x1d1>;
			};

			i2s2m0-lrcktx {
				rockchip,pins = <0x02 0x13 0x01 0xbe>;
				phandle = <0x79>;
			};

			i2s2m0-mclk {
				rockchip,pins = <0x02 0x11 0x01 0xbe>;
				phandle = <0x1d2>;
			};

			i2s2m0-sclkrx {
				rockchip,pins = <0x02 0x0f 0x01 0xbe>;
				phandle = <0x1d3>;
			};

			i2s2m0-sclktx {
				rockchip,pins = <0x02 0x12 0x01 0xbe>;
				phandle = <0x78>;
			};

			i2s2m0-sdi {
				rockchip,pins = <0x02 0x15 0x01 0xbe>;
				phandle = <0x7a>;
			};

			i2s2m0-sdo {
				rockchip,pins = <0x02 0x14 0x01 0xbe>;
				phandle = <0x7b>;
			};

			i2s2m1-lrckrx {
				rockchip,pins = <0x04 0x05 0x05 0xbe>;
				phandle = <0x1d4>;
			};

			i2s2m1-lrcktx {
				rockchip,pins = <0x04 0x04 0x05 0xbe>;
				phandle = <0x1d5>;
			};

			i2s2m1-mclk {
				rockchip,pins = <0x04 0x0e 0x05 0xbe>;
				phandle = <0x1d6>;
			};

			i2s2m1-sclkrx {
				rockchip,pins = <0x04 0x11 0x05 0xbe>;
				phandle = <0x1d7>;
			};

			i2s2m1-sclktx {
				rockchip,pins = <0x04 0x0f 0x04 0xbe>;
				phandle = <0x1d8>;
			};

			i2s2m1-sdi {
				rockchip,pins = <0x04 0x0a 0x05 0xbe>;
				phandle = <0x1d9>;
			};

			i2s2m1-sdo {
				rockchip,pins = <0x04 0x0b 0x05 0xbe>;
				phandle = <0x1da>;
			};
		};

		i2s3 {

			i2s3m0-lrck {
				rockchip,pins = <0x03 0x04 0x04 0xbe>;
				phandle = <0x1db>;
			};

			i2s3m0-mclk {
				rockchip,pins = <0x03 0x02 0x04 0xbe>;
				phandle = <0x1dc>;
			};

			i2s3m0-sclk {
				rockchip,pins = <0x03 0x03 0x04 0xbe>;
				phandle = <0x1dd>;
			};

			i2s3m0-sdi {
				rockchip,pins = <0x03 0x06 0x04 0xbe>;
				phandle = <0x1de>;
			};

			i2s3m0-sdo {
				rockchip,pins = <0x03 0x05 0x04 0xbe>;
				phandle = <0x1df>;
			};

			i2s3m1-lrck {
				rockchip,pins = <0x04 0x14 0x05 0xbe>;
				phandle = <0x1e0>;
			};

			i2s3m1-mclk {
				rockchip,pins = <0x04 0x12 0x05 0xbe>;
				phandle = <0x1e1>;
			};

			i2s3m1-sclk {
				rockchip,pins = <0x04 0x13 0x05 0xbe>;
				phandle = <0x1e2>;
			};

			i2s3m1-sdi {
				rockchip,pins = <0x04 0x16 0x05 0xbe>;
				phandle = <0x1e3>;
			};

			i2s3m1-sdo {
				rockchip,pins = <0x04 0x15 0x05 0xbe>;
				phandle = <0x1e4>;
			};
		};

		isp {

			isp-pins {
				rockchip,pins = <0x04 0x0c 0x04 0xbe 0x04 0x06 0x01 0xbe 0x04 0x09 0x01 0xbe>;
				phandle = <0x1e5>;
			};
		};

		jtag {

			jtag-pins {
				rockchip,pins = <0x01 0x1f 0x02 0xbe 0x02 0x00 0x02 0xbe>;
				phandle = <0x1e6>;
			};
		};

		lcdc {

			lcdc-ctl {
				rockchip,pins = <0x03 0x00 0x01 0xbe 0x02 0x18 0x01 0xbe 0x02 0x19 0x01 0xbe 0x02 0x1a 0x01 0xbe 0x02 0x1b 0x01 0xbe 0x02 0x1c 0x01 0xbe 0x02 0x1d 0x01 0xbe 0x02 0x1e 0x01 0xbe 0x02 0x1f 0x01 0xbe 0x03 0x01 0x01 0xbe 0x03 0x02 0x01 0xbe 0x03 0x03 0x01 0xbe 0x03 0x04 0x01 0xbe 0x03 0x05 0x01 0xbe 0x03 0x06 0x01 0xbe 0x03 0x07 0x01 0xbe 0x03 0x08 0x01 0xbe 0x03 0x09 0x01 0xbe 0x03 0x0a 0x01 0xbe 0x03 0x0b 0x01 0xbe 0x03 0x0c 0x01 0xbe 0x03 0x0d 0x01 0xbe 0x03 0x0e 0x01 0xbe 0x03 0x0f 0x01 0xbe 0x03 0x10 0x01 0xbe 0x03 0x13 0x01 0xbe 0x03 0x11 0x01 0xbe 0x03 0x12 0x01 0xbe>;
				phandle = <0x1e7>;
			};

			lcdc-clock {
				rockchip,pins = <0x03 0x00 0x01 0xbe 0x03 0x13 0x01 0xbe 0x03 0x11 0x01 0xbe 0x03 0x12 0x01 0xbe>;
				phandle = <0x1e8>;
			};

			lcdc-data16 {
				rockchip,pins = <0x02 0x1b 0x01 0xbe 0x02 0x1c 0x01 0xbe 0x02 0x1d 0x01 0xbe 0x02 0x1e 0x01 0xbe 0x02 0x1f 0x01 0xbe 0x03 0x03 0x01 0xbe 0x03 0x04 0x01 0xbe 0x03 0x05 0x01 0xbe 0x03 0x06 0x01 0xbe 0x03 0x07 0x01 0xbe 0x03 0x08 0x01 0xbe 0x03 0x0c 0x01 0xbe 0x03 0x0d 0x01 0xbe 0x03 0x0e 0x01 0xbe 0x03 0x0f 0x01 0xbe 0x03 0x10 0x01 0xbe>;
				phandle = <0x1e9>;
			};

			lcdc-data18 {
				rockchip,pins = <0x02 0x1a 0x01 0xbe 0x02 0x1b 0x01 0xbe 0x02 0x1c 0x01 0xbe 0x02 0x1d 0x01 0xbe 0x02 0x1e 0x01 0xbe 0x02 0x1f 0x01 0xbe 0x03 0x03 0x01 0xbe 0x03 0x04 0x01 0xbe 0x03 0x05 0x01 0xbe 0x03 0x06 0x01 0xbe 0x03 0x07 0x01 0xbe 0x03 0x08 0x01 0xbe 0x03 0x0b 0x01 0xbe 0x03 0x0c 0x01 0xbe 0x03 0x0d 0x01 0xbe 0x03 0x0e 0x01 0xbe 0x03 0x0f 0x01 0xbe 0x03 0x10 0x01 0xbe>;
				phandle = <0x1ea>;
			};
		};

		mcu {

			mcu-pins {
				rockchip,pins = <0x00 0x0c 0x04 0xbe 0x00 0x11 0x04 0xbe 0x00 0x0b 0x04 0xbe 0x00 0x12 0x04 0xbe 0x00 0x13 0x04 0xbe>;
				phandle = <0x1eb>;
			};
		};

		npu {

			npu-pins {
				rockchip,pins = <0x00 0x11 0x02 0xbe>;
				phandle = <0x1ec>;
			};
		};

		pcie20 {

			pcie20m0-pins {
				rockchip,pins = <0x00 0x05 0x03 0xbe 0x00 0x0e 0x03 0xbe 0x00 0x0d 0x03 0xbe>;
				phandle = <0x1ed>;
			};

			pcie20m1-pins {
				rockchip,pins = <0x02 0x18 0x04 0xbe 0x03 0x11 0x04 0xbe 0x02 0x19 0x04 0xbe>;
				phandle = <0x1ee>;
			};

			pcie20m2-pins {
				rockchip,pins = <0x01 0x08 0x04 0xbe 0x01 0x0a 0x04 0xbe 0x01 0x09 0x04 0xbe>;
				phandle = <0x1ef>;
			};

			pcie20-buttonrstn {
				rockchip,pins = <0x00 0x0c 0x03 0xbe>;
				phandle = <0x1f0>;
			};
		};

		pcie30x1 {

			pcie30x1m0-pins {
				rockchip,pins = <0x00 0x04 0x03 0xbe 0x00 0x13 0x03 0xbe 0x00 0x12 0x03 0xbe>;
				phandle = <0x1f1>;
			};

			pcie30x1m1-pins {
				rockchip,pins = <0x02 0x1a 0x04 0xbe 0x03 0x01 0x04 0xbe 0x02 0x1b 0x04 0xbe>;
				phandle = <0x1f2>;
			};

			pcie30x1m2-pins {
				rockchip,pins = <0x01 0x05 0x04 0xbe 0x01 0x02 0x04 0xbe 0x01 0x03 0x04 0xbe>;
				phandle = <0x1f3>;
			};

			pcie30x1-buttonrstn {
				rockchip,pins = <0x00 0x0b 0x03 0xbe>;
				phandle = <0x1f4>;
			};
		};

		pcie30x2 {

			pcie30x2m0-pins {
				rockchip,pins = <0x00 0x06 0x02 0xbe 0x00 0x16 0x03 0xbe 0x00 0x15 0x03 0xbe>;
				phandle = <0x1f5>;
			};

			pcie30x2m1-pins {
				rockchip,pins = <0x02 0x1c 0x04 0xbe 0x02 0x1e 0x04 0xbe 0x02 0x1d 0x04 0xbe>;
				phandle = <0x1f6>;
			};

			pcie30x2m2-pins {
				rockchip,pins = <0x04 0x12 0x04 0xbe 0x04 0x14 0x04 0xbe 0x04 0x13 0x04 0xbe>;
				phandle = <0x1f7>;
			};

			pcie30x2-buttonrstn {
				rockchip,pins = <0x00 0x08 0x03 0xbe>;
				phandle = <0x1f8>;
			};
		};

		pdm {

			pdmm0-clk {
				rockchip,pins = <0x01 0x06 0x03 0xbe>;
				phandle = <0x7c>;
			};

			pdmm0-clk1 {
				rockchip,pins = <0x01 0x04 0x03 0xbe>;
				phandle = <0x7d>;
			};

			pdmm0-sdi0 {
				rockchip,pins = <0x01 0x0b 0x02 0xbe>;
				phandle = <0x7e>;
			};

			pdmm0-sdi1 {
				rockchip,pins = <0x01 0x0a 0x03 0xbe>;
				phandle = <0x7f>;
			};

			pdmm0-sdi2 {
				rockchip,pins = <0x01 0x09 0x03 0xbe>;
				phandle = <0x80>;
			};

			pdmm0-sdi3 {
				rockchip,pins = <0x01 0x08 0x03 0xbe>;
				phandle = <0x81>;
			};

			pdmm1-clk {
				rockchip,pins = <0x03 0x1e 0x05 0xbe>;
				phandle = <0x1f9>;
			};

			pdmm1-clk1 {
				rockchip,pins = <0x04 0x00 0x04 0xbe>;
				phandle = <0x1fa>;
			};

			pdmm1-sdi0 {
				rockchip,pins = <0x03 0x1f 0x05 0xbe>;
				phandle = <0x1fb>;
			};

			pdmm1-sdi1 {
				rockchip,pins = <0x04 0x01 0x04 0xbe>;
				phandle = <0x1fc>;
			};

			pdmm1-sdi2 {
				rockchip,pins = <0x04 0x02 0x05 0xbe>;
				phandle = <0x1fd>;
			};

			pdmm1-sdi3 {
				rockchip,pins = <0x04 0x03 0x05 0xbe>;
				phandle = <0x1fe>;
			};

			pdmm2-clk1 {
				rockchip,pins = <0x03 0x14 0x05 0xbe>;
				phandle = <0x1ff>;
			};

			pdmm2-sdi0 {
				rockchip,pins = <0x03 0x0b 0x05 0xbe>;
				phandle = <0x200>;
			};

			pdmm2-sdi1 {
				rockchip,pins = <0x03 0x0c 0x05 0xbe>;
				phandle = <0x201>;
			};

			pdmm2-sdi2 {
				rockchip,pins = <0x03 0x0f 0x05 0xbe>;
				phandle = <0x202>;
			};

			pdmm2-sdi3 {
				rockchip,pins = <0x03 0x10 0x05 0xbe>;
				phandle = <0x203>;
			};
		};

		pmic {

			pmic-pins {
				rockchip,pins = <0x00 0x02 0x01 0xbe>;
				phandle = <0x204>;
			};

			pmic_int {
				rockchip,pins = <0x00 0x03 0x00 0xc0>;
				phandle = <0x25>;
			};

			soc_slppin_gpio {
				rockchip,pins = <0x00 0x02 0x00 0xc4>;
				phandle = <0x29>;
			};

			soc_slppin_slp {
				rockchip,pins = <0x00 0x02 0x01 0xbe>;
				phandle = <0x27>;
			};

			soc_slppin_rst {
				rockchip,pins = <0x00 0x02 0x02 0xbe>;
				phandle = <0x205>;
			};
		};

		pmu {

			pmu-pins {
				rockchip,pins = <0x00 0x05 0x04 0xbe 0x00 0x06 0x03 0xbe 0x00 0x14 0x04 0xbe 0x00 0x15 0x04 0xbe 0x00 0x16 0x04 0xbe 0x00 0x17 0x04 0xbe>;
				phandle = <0x206>;
			};
		};

		pwm0 {

			pwm0m0-pins {
				rockchip,pins = <0x00 0x0f 0x01 0xbe>;
				phandle = <0x2f>;
			};

			pwm0m1-pins {
				rockchip,pins = <0x00 0x17 0x02 0xbe>;
				phandle = <0x207>;
			};
		};

		pwm1 {

			pwm1m0-pins {
				rockchip,pins = <0x00 0x10 0x01 0xbe>;
				phandle = <0x30>;
			};

			pwm1m1-pins {
				rockchip,pins = <0x00 0x0d 0x04 0xbe>;
				phandle = <0x208>;
			};
		};

		pwm2 {

			pwm2m0-pins {
				rockchip,pins = <0x00 0x11 0x01 0xbe>;
				phandle = <0x31>;
			};

			pwm2m1-pins {
				rockchip,pins = <0x00 0x0e 0x04 0xbe>;
				phandle = <0x209>;
			};
		};

		pwm3 {

			pwm3-pins {
				rockchip,pins = <0x00 0x12 0x01 0xbe>;
				phandle = <0x32>;
			};
		};

		pwm4 {

			pwm4-pins {
				rockchip,pins = <0x00 0x13 0x01 0xbe>;
				phandle = <0xaa>;
			};
		};

		pwm5 {

			pwm5-pins {
				rockchip,pins = <0x00 0x14 0x01 0xbe>;
				phandle = <0xab>;
			};
		};

		pwm6 {

			pwm6-pins {
				rockchip,pins = <0x00 0x15 0x01 0xbe>;
				phandle = <0xac>;
			};
		};

		pwm7 {

			pwm7-pins {
				rockchip,pins = <0x00 0x16 0x01 0xbe>;
				phandle = <0xad>;
			};
		};

		pwm8 {

			pwm8m0-pins {
				rockchip,pins = <0x03 0x09 0x05 0xbe>;
				phandle = <0xae>;
			};

			pwm8m1-pins {
				rockchip,pins = <0x01 0x1d 0x04 0xbe>;
				phandle = <0x20a>;
			};
		};

		pwm9 {

			pwm9m0-pins {
				rockchip,pins = <0x03 0x0a 0x05 0xbe>;
				phandle = <0xaf>;
			};

			pwm9m1-pins {
				rockchip,pins = <0x01 0x1e 0x04 0xbe>;
				phandle = <0x20b>;
			};
		};

		pwm10 {

			pwm10m0-pins {
				rockchip,pins = <0x03 0x0d 0x05 0xbe>;
				phandle = <0xb0>;
			};

			pwm10m1-pins {
				rockchip,pins = <0x02 0x01 0x02 0xbe>;
				phandle = <0x20c>;
			};
		};

		pwm11 {

			pwm11m0-pins {
				rockchip,pins = <0x03 0x0e 0x05 0xbe>;
				phandle = <0x20d>;
			};

			pwm11m1-pins {
				rockchip,pins = <0x04 0x10 0x03 0xbe>;
				phandle = <0xb1>;
			};
		};

		pwm12 {

			pwm12m0-pins {
				rockchip,pins = <0x03 0x0f 0x02 0xbe>;
				phandle = <0xb2>;
			};

			pwm12m1-pins {
				rockchip,pins = <0x04 0x15 0x01 0xbe>;
				phandle = <0x20e>;
			};
		};

		pwm13 {

			pwm13m0-pins {
				rockchip,pins = <0x03 0x10 0x02 0xbe>;
				phandle = <0xb3>;
			};

			pwm13m1-pins {
				rockchip,pins = <0x04 0x16 0x01 0xbe>;
				phandle = <0x20f>;
			};
		};

		pwm14 {

			pwm14m0-pins {
				rockchip,pins = <0x03 0x14 0x01 0xbe>;
				phandle = <0xb4>;
			};

			pwm14m1-pins {
				rockchip,pins = <0x04 0x12 0x01 0xbe>;
				phandle = <0x210>;
			};
		};

		pwm15 {

			pwm15m0-pins {
				rockchip,pins = <0x03 0x15 0x01 0xbe>;
				phandle = <0x211>;
			};

			pwm15m1-pins {
				rockchip,pins = <0x04 0x13 0x01 0xbe>;
				phandle = <0xb5>;
			};
		};

		refclk {

			refclk-pins {
				rockchip,pins = <0x00 0x00 0x01 0xbe>;
				phandle = <0x212>;
			};
		};

		sata {

			sata-pins {
				rockchip,pins = <0x00 0x04 0x02 0xbe 0x00 0x06 0x01 0xbe 0x00 0x05 0x02 0xbe>;
				phandle = <0x213>;
			};
		};

		sata0 {

			sata0-pins {
				rockchip,pins = <0x04 0x16 0x03 0xbe>;
				phandle = <0x214>;
			};
		};

		sata1 {

			sata1-pins {
				rockchip,pins = <0x04 0x15 0x03 0xbe>;
				phandle = <0x215>;
			};
		};

		sata2 {

			sata2-pins {
				rockchip,pins = <0x04 0x14 0x03 0xbe>;
				phandle = <0x216>;
			};
		};

		scr {

			scr-pins {
				rockchip,pins = <0x01 0x02 0x03 0xbe 0x01 0x07 0x03 0xc0 0x01 0x03 0x03 0xc0 0x01 0x05 0x03 0xbe>;
				phandle = <0x217>;
			};
		};

		sdmmc0 {

			sdmmc0-bus4 {
				rockchip,pins = <0x01 0x1d 0x01 0xbf 0x01 0x1e 0x01 0xbf 0x01 0x1f 0x01 0xbf 0x02 0x00 0x01 0xbf>;
				phandle = <0x67>;
			};

			sdmmc0-clk {
				rockchip,pins = <0x02 0x02 0x01 0xbf>;
				phandle = <0x68>;
			};

			sdmmc0-cmd {
				rockchip,pins = <0x02 0x01 0x01 0xbf>;
				phandle = <0x69>;
			};

			sdmmc0-det {
				rockchip,pins = <0x00 0x04 0x01 0xc0>;
				phandle = <0x6a>;
			};

			sdmmc0-pwren {
				rockchip,pins = <0x00 0x05 0x01 0xbe>;
				phandle = <0x218>;
			};
		};

		sdmmc1 {

			sdmmc1-bus4 {
				rockchip,pins = <0x02 0x03 0x01 0xbf 0x02 0x04 0x01 0xbf 0x02 0x05 0x01 0xbf 0x02 0x06 0x01 0xbf>;
				phandle = <0x6c>;
			};

			sdmmc1-clk {
				rockchip,pins = <0x02 0x08 0x01 0xbf>;
				phandle = <0x6e>;
			};

			sdmmc1-cmd {
				rockchip,pins = <0x02 0x07 0x01 0xbf>;
				phandle = <0x6d>;
			};

			sdmmc1-det {
				rockchip,pins = <0x02 0x0a 0x01 0xc0>;
				phandle = <0x219>;
			};

			sdmmc1-pwren {
				rockchip,pins = <0x02 0x09 0x01 0xbe>;
				phandle = <0x21a>;
			};
		};

		sdmmc2 {

			sdmmc2m0-bus4 {
				rockchip,pins = <0x03 0x16 0x03 0xbf 0x03 0x17 0x03 0xbf 0x03 0x18 0x03 0xbf 0x03 0x19 0x03 0xbf>;
				phandle = <0x21b>;
			};

			sdmmc2m0-clk {
				rockchip,pins = <0x03 0x1b 0x03 0xbf>;
				phandle = <0x21c>;
			};

			sdmmc2m0-cmd {
				rockchip,pins = <0x03 0x1a 0x03 0xbf>;
				phandle = <0x21d>;
			};

			sdmmc2m0-det {
				rockchip,pins = <0x03 0x1c 0x03 0xc0>;
				phandle = <0x21e>;
			};

			sdmmc2m0-pwren {
				rockchip,pins = <0x03 0x1d 0x03 0xbe>;
				phandle = <0x21f>;
			};

			sdmmc2m1-bus4 {
				rockchip,pins = <0x03 0x01 0x05 0xbf 0x03 0x02 0x05 0xbf 0x03 0x03 0x05 0xbf 0x03 0x04 0x05 0xbf>;
				phandle = <0x220>;
			};

			sdmmc2m1-clk {
				rockchip,pins = <0x03 0x06 0x05 0xbf>;
				phandle = <0x221>;
			};

			sdmmc2m1-cmd {
				rockchip,pins = <0x03 0x05 0x05 0xbf>;
				phandle = <0x222>;
			};

			sdmmc2m1-det {
				rockchip,pins = <0x03 0x07 0x04 0xc0>;
				phandle = <0x223>;
			};

			sdmmc2m1-pwren {
				rockchip,pins = <0x03 0x08 0x04 0xbe>;
				phandle = <0x224>;
			};
		};

		spdif {

			spdifm0-tx {
				rockchip,pins = <0x01 0x04 0x04 0xbe>;
				phandle = <0x82>;
			};

			spdifm1-tx {
				rockchip,pins = <0x03 0x15 0x02 0xbe>;
				phandle = <0x225>;
			};

			spdifm2-tx {
				rockchip,pins = <0x04 0x14 0x02 0xbe>;
				phandle = <0x226>;
			};
		};

		spi0 {

			spi0m0-pins {
				rockchip,pins = <0x00 0x0d 0x02 0xbe 0x00 0x15 0x02 0xbe 0x00 0x0e 0x02 0xbe>;
				phandle = <0x8a>;
			};

			spi0m0-cs0 {
				rockchip,pins = <0x00 0x16 0x02 0xbe>;
				phandle = <0x88>;
			};

			spi0m0-cs1 {
				rockchip,pins = <0x00 0x14 0x02 0xbe>;
				phandle = <0x89>;
			};

			spi0m1-pins {
				rockchip,pins = <0x02 0x1b 0x03 0xbe 0x02 0x18 0x03 0xbe 0x02 0x19 0x03 0xbe>;
				phandle = <0x227>;
			};

			spi0m1-cs0 {
				rockchip,pins = <0x02 0x1a 0x03 0xbe>;
				phandle = <0x228>;
			};
		};

		spi1 {

			spi1m0-pins {
				rockchip,pins = <0x02 0x0d 0x03 0xbe 0x02 0x0e 0x03 0xbe 0x02 0x0f 0x04 0xbe>;
				phandle = <0x8d>;
			};

			spi1m0-cs0 {
				rockchip,pins = <0x02 0x10 0x04 0xbe>;
				phandle = <0x8b>;
			};

			spi1m0-cs1 {
				rockchip,pins = <0x02 0x16 0x03 0xbe>;
				phandle = <0x8c>;
			};

			spi1m1-pins {
				rockchip,pins = <0x03 0x13 0x03 0xbe 0x03 0x12 0x03 0xbe 0x03 0x11 0x03 0xbe>;
				phandle = <0x229>;
			};

			spi1m1-cs0 {
				rockchip,pins = <0x03 0x01 0x03 0xbe>;
				phandle = <0x22a>;
			};
		};

		spi2 {

			spi2m0-pins {
				rockchip,pins = <0x02 0x11 0x04 0xbe 0x02 0x12 0x04 0xbe 0x02 0x13 0x04 0xbe>;
				phandle = <0x90>;
			};

			spi2m0-cs0 {
				rockchip,pins = <0x02 0x14 0x04 0xbe>;
				phandle = <0x8e>;
			};

			spi2m0-cs1 {
				rockchip,pins = <0x02 0x15 0x04 0xbe>;
				phandle = <0x8f>;
			};

			spi2m1-pins {
				rockchip,pins = <0x03 0x00 0x03 0xbe 0x02 0x1f 0x03 0xbe 0x02 0x1e 0x03 0xbe>;
				phandle = <0x22b>;
			};

			spi2m1-cs0 {
				rockchip,pins = <0x02 0x1d 0x03 0xbe>;
				phandle = <0x22c>;
			};

			spi2m1-cs1 {
				rockchip,pins = <0x02 0x1c 0x03 0xbe>;
				phandle = <0x22d>;
			};
		};

		spi3 {

			spi3m0-pins {
				rockchip,pins = <0x04 0x0b 0x04 0xbe 0x04 0x08 0x04 0xbe 0x04 0x0a 0x04 0xbe>;
				phandle = <0x92>;
			};

			spi3m0-cs0 {
				rockchip,pins = <0x04 0x06 0x04 0xbe>;
				phandle = <0x22e>;
			};

			spi3m0-cs1 {
				rockchip,pins = <0x04 0x07 0x04 0xbe>;
				phandle = <0x91>;
			};

			spi3m1-pins {
				rockchip,pins = <0x04 0x12 0x02 0xbe 0x04 0x15 0x02 0xbe 0x04 0x13 0x02 0xbe>;
				phandle = <0x22f>;
			};

			spi3m1-cs0 {
				rockchip,pins = <0x04 0x16 0x02 0xbe>;
				phandle = <0x230>;
			};

			spi3m1-cs1 {
				rockchip,pins = <0x04 0x19 0x02 0xbe>;
				phandle = <0x231>;
			};
		};

		tsadc {

			tsadcm0-shut {
				rockchip,pins = <0x00 0x01 0x01 0xbe>;
				phandle = <0x232>;
			};

			tsadcm1-shut {
				rockchip,pins = <0x00 0x02 0x02 0xbe>;
				phandle = <0x233>;
			};

			tsadc-shutorg {
				rockchip,pins = <0x00 0x01 0x02 0xbe>;
				phandle = <0xa8>;
			};

			tsadc-pin {
				rockchip,pins = <0x00 0x01 0x00 0xbe>;
				phandle = <0xa7>;
			};
		};

		uart0 {

			uart0-xfer {
				rockchip,pins = <0x00 0x10 0x03 0xc0 0x00 0x11 0x03 0xc0>;
				phandle = <0x2e>;
			};

			uart0-ctsn {
				rockchip,pins = <0x00 0x17 0x03 0xbe>;
				phandle = <0x234>;
			};

			uart0-rtsn {
				rockchip,pins = <0x00 0x14 0x03 0xbe>;
				phandle = <0x235>;
			};
		};

		uart1 {

			uart1m0-xfer {
				rockchip,pins = <0x02 0x0b 0x02 0xc0 0x02 0x0c 0x02 0xc0>;
				phandle = <0x93>;
			};

			uart1m0-ctsn {
				rockchip,pins = <0x02 0x0e 0x02 0xbe>;
				phandle = <0x94>;
			};

			uart1m0-rtsn {
				rockchip,pins = <0x02 0x0d 0x02 0xbe>;
				phandle = <0x95>;
			};

			uart1m1-xfer {
				rockchip,pins = <0x03 0x1f 0x04 0xc0 0x03 0x1e 0x04 0xc0>;
				phandle = <0x236>;
			};

			uart1m1-ctsn {
				rockchip,pins = <0x04 0x11 0x04 0xbe>;
				phandle = <0x237>;
			};

			uart1m1-rtsn {
				rockchip,pins = <0x04 0x0e 0x04 0xbe>;
				phandle = <0x238>;
			};
		};

		uart2 {

			uart2m0-xfer {
				rockchip,pins = <0x00 0x18 0x01 0xc0 0x00 0x19 0x01 0xc0>;
				phandle = <0x9b>;
			};

			uart2m1-xfer {
				rockchip,pins = <0x01 0x1e 0x02 0xc0 0x01 0x1d 0x02 0xc0>;
				phandle = <0x239>;
			};
		};

		uart3 {

			uart3m0-xfer {
				rockchip,pins = <0x01 0x00 0x02 0xc0 0x01 0x01 0x02 0xc0>;
				phandle = <0x9c>;
			};

			uart3m0-ctsn {
				rockchip,pins = <0x01 0x03 0x02 0xbe>;
				phandle = <0x23a>;
			};

			uart3m0-rtsn {
				rockchip,pins = <0x01 0x02 0x02 0xbe>;
				phandle = <0x23b>;
			};

			uart3m1-xfer {
				rockchip,pins = <0x03 0x10 0x04 0xc0 0x03 0x0f 0x04 0xc0>;
				phandle = <0x23c>;
			};
		};

		uart4 {

			uart4m0-xfer {
				rockchip,pins = <0x01 0x04 0x02 0xc0 0x01 0x06 0x02 0xc0>;
				phandle = <0x9d>;
			};

			uart4m0-ctsn {
				rockchip,pins = <0x01 0x07 0x02 0xbe>;
				phandle = <0x23d>;
			};

			uart4m0-rtsn {
				rockchip,pins = <0x01 0x05 0x02 0xbe>;
				phandle = <0x23e>;
			};

			uart4m1-xfer {
				rockchip,pins = <0x03 0x09 0x04 0xc0 0x03 0x0a 0x04 0xc0>;
				phandle = <0x23f>;
			};
		};

		uart5 {

			uart5m0-xfer {
				rockchip,pins = <0x02 0x01 0x03 0xc0 0x02 0x02 0x03 0xc0>;
				phandle = <0x9e>;
			};

			uart5m0-ctsn {
				rockchip,pins = <0x01 0x1f 0x03 0xbe>;
				phandle = <0x240>;
			};

			uart5m0-rtsn {
				rockchip,pins = <0x02 0x00 0x03 0xbe>;
				phandle = <0x241>;
			};

			uart5m1-xfer {
				rockchip,pins = <0x03 0x13 0x04 0xc0 0x03 0x12 0x04 0xc0>;
				phandle = <0x242>;
			};
		};

		uart6 {

			uart6m0-xfer {
				rockchip,pins = <0x02 0x03 0x03 0xc0 0x02 0x04 0x03 0xc0>;
				phandle = <0x9f>;
			};

			uart6m0-ctsn {
				rockchip,pins = <0x02 0x10 0x03 0xbe>;
				phandle = <0x243>;
			};

			uart6m0-rtsn {
				rockchip,pins = <0x02 0x0f 0x03 0xbe>;
				phandle = <0x244>;
			};

			uart6m1-xfer {
				rockchip,pins = <0x01 0x1e 0x03 0xc0 0x01 0x1d 0x03 0xc0>;
				phandle = <0x245>;
			};
		};

		uart7 {

			uart7m0-xfer {
				rockchip,pins = <0x02 0x05 0x03 0xc0 0x02 0x06 0x03 0xc0>;
				phandle = <0x246>;
			};

			uart7m0-ctsn {
				rockchip,pins = <0x02 0x12 0x03 0xbe>;
				phandle = <0x247>;
			};

			uart7m0-rtsn {
				rockchip,pins = <0x02 0x11 0x03 0xbe>;
				phandle = <0x248>;
			};

			uart7m1-xfer {
				rockchip,pins = <0x03 0x15 0x04 0xc0 0x03 0x14 0x04 0xc0>;
				phandle = <0x249>;
			};

			uart7m2-xfer {
				rockchip,pins = <0x04 0x03 0x04 0xc0 0x04 0x02 0x04 0xc0>;
				phandle = <0xa0>;
			};
		};

		uart8 {

			uart8m0-xfer {
				rockchip,pins = <0x02 0x16 0x02 0xc0 0x02 0x15 0x03 0xc0>;
				phandle = <0xa1>;
			};

			uart8m0-ctsn {
				rockchip,pins = <0x02 0x0a 0x03 0xbe>;
				phandle = <0x24a>;
			};

			uart8m0-rtsn {
				rockchip,pins = <0x02 0x09 0x03 0xbe>;
				phandle = <0x24b>;
			};

			uart8m1-xfer {
				rockchip,pins = <0x03 0x00 0x04 0xc0 0x02 0x1f 0x04 0xc0>;
				phandle = <0x24c>;
			};
		};

		uart9 {

			uart9m0-xfer {
				rockchip,pins = <0x02 0x07 0x03 0xc0 0x02 0x08 0x03 0xc0>;
				phandle = <0x24d>;
			};

			uart9m0-ctsn {
				rockchip,pins = <0x02 0x14 0x03 0xbe>;
				phandle = <0x24e>;
			};

			uart9m0-rtsn {
				rockchip,pins = <0x02 0x13 0x03 0xbe>;
				phandle = <0x24f>;
			};

			uart9m1-xfer {
				rockchip,pins = <0x04 0x16 0x04 0xc0 0x04 0x15 0x04 0xc0>;
				phandle = <0x250>;
			};

			uart9m2-xfer {
				rockchip,pins = <0x04 0x05 0x04 0xc0 0x04 0x04 0x04 0xc0>;
				phandle = <0xa2>;
			};
		};

		vop {

			vopm0-pins {
				rockchip,pins = <0x00 0x13 0x02 0xbe>;
				phandle = <0x251>;
			};

			vopm1-pins {
				rockchip,pins = <0x03 0x14 0x02 0xbe>;
				phandle = <0x252>;
			};
		};

		spi0-hs {

			spi0m0-pins {
				rockchip,pins = <0x00 0x0d 0x02 0xc5 0x00 0x15 0x02 0xc5 0x00 0x0e 0x02 0xc5>;
				phandle = <0x253>;
			};

			spi0m0-cs0 {
				rockchip,pins = <0x00 0x16 0x02 0xc5>;
				phandle = <0x254>;
			};

			spi0m0-cs1 {
				rockchip,pins = <0x00 0x14 0x02 0xc5>;
				phandle = <0x255>;
			};

			spi0m1-pins {
				rockchip,pins = <0x02 0x1b 0x03 0xc5 0x02 0x18 0x03 0xc5 0x02 0x19 0x03 0xc5>;
				phandle = <0x256>;
			};

			spi0m1-cs0 {
				rockchip,pins = <0x02 0x1a 0x03 0xc5>;
				phandle = <0x257>;
			};
		};

		spi1-hs {

			spi1m0-pins {
				rockchip,pins = <0x02 0x0d 0x03 0xc5 0x02 0x0e 0x03 0xc5 0x02 0x0f 0x04 0xc5>;
				phandle = <0x258>;
			};

			spi1m0-cs0 {
				rockchip,pins = <0x02 0x10 0x04 0xc5>;
				phandle = <0x259>;
			};

			spi1m0-cs1 {
				rockchip,pins = <0x02 0x16 0x03 0xc5>;
				phandle = <0x25a>;
			};

			spi1m1-pins {
				rockchip,pins = <0x03 0x13 0x03 0xc5 0x03 0x12 0x03 0xc5 0x03 0x11 0x03 0xc5>;
				phandle = <0x25b>;
			};

			spi1m1-cs0 {
				rockchip,pins = <0x03 0x01 0x03 0xc5>;
				phandle = <0x25c>;
			};
		};

		spi2-hs {

			spi2m0-pins {
				rockchip,pins = <0x02 0x11 0x04 0xc5 0x02 0x12 0x04 0xc5 0x02 0x13 0x04 0xc5>;
				phandle = <0x25d>;
			};

			spi2m0-cs0 {
				rockchip,pins = <0x02 0x14 0x04 0xc5>;
				phandle = <0x25e>;
			};

			spi2m0-cs1 {
				rockchip,pins = <0x02 0x15 0x04 0xc5>;
				phandle = <0x25f>;
			};

			spi2m1-pins {
				rockchip,pins = <0x03 0x00 0x03 0xc5 0x02 0x1f 0x03 0xc5 0x02 0x1e 0x03 0xc5>;
				phandle = <0x260>;
			};

			spi2m1-cs0 {
				rockchip,pins = <0x02 0x1d 0x03 0xc5>;
				phandle = <0x261>;
			};

			spi2m1-cs1 {
				rockchip,pins = <0x02 0x1c 0x03 0xc5>;
				phandle = <0x262>;
			};
		};

		spi3-hs {

			spi3m0-pins {
				rockchip,pins = <0x04 0x0b 0x04 0xc5 0x04 0x08 0x04 0xc5 0x04 0x0a 0x04 0xc5>;
				phandle = <0x263>;
			};

			spi3m0-cs0 {
				rockchip,pins = <0x04 0x06 0x04 0xc5>;
				phandle = <0x264>;
			};

			spi3m0-cs1 {
				rockchip,pins = <0x04 0x07 0x04 0xc5>;
				phandle = <0x265>;
			};

			spi3m1-pins {
				rockchip,pins = <0x04 0x12 0x02 0xc5 0x04 0x15 0x02 0xc5 0x04 0x13 0x02 0xc5>;
				phandle = <0x266>;
			};

			spi3m1-cs0 {
				rockchip,pins = <0x04 0x16 0x02 0xc5>;
				phandle = <0x267>;
			};

			spi3m1-cs1 {
				rockchip,pins = <0x04 0x19 0x02 0xc5>;
				phandle = <0x268>;
			};
		};

		gmac-txd-level3 {

			gmac0-tx-bus2-level3 {
				rockchip,pins = <0x02 0x0b 0x01 0xc6 0x02 0x0c 0x01 0xc6 0x02 0x0d 0x01 0xbe>;
				phandle = <0x269>;
			};

			gmac0-rgmii-bus-level3 {
				rockchip,pins = <0x02 0x03 0x02 0xbe 0x02 0x04 0x02 0xbe 0x02 0x06 0x02 0xc6 0x02 0x07 0x02 0xc6>;
				phandle = <0x26a>;
			};

			gmac1m0-tx-bus2-level3 {
				rockchip,pins = <0x03 0x0d 0x03 0xc6 0x03 0x0e 0x03 0xc6 0x03 0x0f 0x03 0xbe>;
				phandle = <0x26b>;
			};

			gmac1m0-rgmii-bus-level3 {
				rockchip,pins = <0x03 0x04 0x03 0xbe 0x03 0x05 0x03 0xbe 0x03 0x02 0x03 0xc6 0x03 0x03 0x03 0xc6>;
				phandle = <0x26c>;
			};

			gmac1m1-tx-bus2-level3 {
				rockchip,pins = <0x04 0x04 0x03 0xc6 0x04 0x05 0x03 0xc6 0x04 0x06 0x03 0xbe>;
				phandle = <0x26d>;
			};

			gmac1m1-rgmii-bus-level3 {
				rockchip,pins = <0x04 0x01 0x03 0xbe 0x04 0x02 0x03 0xbe 0x03 0x1e 0x03 0xc6 0x03 0x1f 0x03 0xc6>;
				phandle = <0x26e>;
			};
		};

		gmac-txc-level2 {

			gmac0-rgmii-clk-level2 {
				rockchip,pins = <0x02 0x05 0x02 0xbe 0x02 0x08 0x02 0xc1>;
				phandle = <0x26f>;
			};

			gmac1m0-rgmii-clk-level2 {
				rockchip,pins = <0x03 0x07 0x03 0xbe 0x03 0x06 0x03 0xc1>;
				phandle = <0x270>;
			};

			gmac1m1-rgmii-clk-level2 {
				rockchip,pins = <0x04 0x03 0x03 0xbe 0x04 0x00 0x03 0xc1>;
				phandle = <0x271>;
			};
		};

		bt {

			bt-reset-h {
				rockchip,pins = <0x02 0x0f 0x00 0xbe>;
				phandle = <0x9a>;
			};

			bt-host-wake-l {
				rockchip,pins = <0x02 0x10 0x00 0xc7>;
				phandle = <0x98>;
			};

			bt-wake-l {
				rockchip,pins = <0x02 0x11 0x00 0xbe>;
				phandle = <0x99>;
			};
		};

		sd {

			sdmmc0-pwr-h {
				rockchip,pins = <0x00 0x08 0x00 0xbe>;
				phandle = <0x272>;
			};
		};

		mxc6655xa {

			mxc6655xa_irq_gpio {
				rockchip,pins = <0x03 0x11 0x00 0xbe>;
				phandle = <0x273>;
			};
		};

		touch {

			touch-gpio {
				rockchip,pins = <0x00 0x0d 0x00 0xc0 0x00 0x0e 0x00 0xbe>;
				phandle = <0x274>;
			};
		};

		sdio-pwrseq {

			wifi-enable-h {
				rockchip,pins = <0x00 0x1b 0x00 0xbe>;
				phandle = <0xcd>;
			};
		};

		usb {

			vcc5v0-host-en {
				rockchip,pins = <0x00 0x06 0x00 0xbe>;
				phandle = <0xd0>;
			};

			vcc5v0-otg-en {
				rockchip,pins = <0x00 0x05 0x00 0xbe>;
				phandle = <0xd1>;
			};
		};

		work-led {

			leds-gpio {
				rockchip,pins = <0x00 0x10 0x00 0xbe>;
				phandle = <0xcb>;
			};
		};

		headphone {

			hp-det {
				rockchip,pins = <0x00 0x14 0x00 0xc7>;
				phandle = <0x275>;
			};
		};

		pcie {

			pcie-drv {
				rockchip,pins = <0x00 0x0f 0x00 0xbe>;
				phandle = <0xcf>;
			};
		};

		edp {

			edp-hpd {
				rockchip,pins = <0x00 0x00 0x00 0xbe>;
				phandle = <0x276>;
			};

			bl-en {
				rockchip,pins = <0x00 0x0d 0x00 0xc8>;
				phandle = <0x277>;
			};
		};
	};

	chosen {
		stdout-path = "serial2:1500000n8";
		phandle = <0x278>;
	};

	pwm-fan {
		compatible = "pwm-fan";
		#cooling-cells = <0x02>;
		pwms = <0xc9 0x00 0xc350 0x00>;
		cooling-levels = <0x00 0x32 0x64 0x96 0xc8 0xff>;
		rockchip,temp-trips = <0xc350 0x01 0xd6d8 0x02 0xea60 0x03 0xfde8 0x04 0x11170 0x05>;
		phandle = <0x279>;
	};

	hdmi-con {
		compatible = "hdmi-connector";
		type = "a";

		port {

			endpoint {
				remote-endpoint = <0xca>;
				phandle = <0x63>;
			};
		};
	};

	leds {
		compatible = "gpio-leds";
		pinctrl-names = "default";
		pinctrl-0 = <0xcb>;
		phandle = <0x27a>;

		led@1 {
			gpios = <0x24 0x10 0x00>;
			label = "status_led";
			linux,default-trigger = "heartbeat";
		};
	};

	rk809-sound {
		compatible = "simple-audio-card";
		simple-audio-card,format = "i2s";
		simple-audio-card,name = "Analog RK809";
		simple-audio-card,mclk-fs = <0x100>;

		simple-audio-card,cpu {
			sound-dai = <0xcc>;
		};

		simple-audio-card,codec {
			sound-dai = <0x96>;
		};
	};

	sdio-pwrseq {
		compatible = "mmc-pwrseq-simple";
		clocks = <0x96 0x01>;
		clock-names = "ext_clock";
		pinctrl-names = "default";
		pinctrl-0 = <0xcd>;
		post-power-on-delay-ms = <0xc8>;
		reset-gpios = <0x24 0x1b 0x01>;
		phandle = <0x6b>;
	};

	sprd-mtty {
		compatible = "sprd,mtty";
		sprd,name = "ttyBT";
	};

	vcc12v-dcin-regulator {
		compatible = "regulator-fixed";
		regulator-name = "vcc12v_dcin";
		regulator-always-on;
		regulator-boot-on;
		regulator-min-microvolt = <0xb71b00>;
		regulator-max-microvolt = <0xb71b00>;
		phandle = <0xce>;
	};

	vcc-5v-regulator {
		compatible = "regulator-fixed";
		regulator-name = "vcc_5v";
		regulator-always-on;
		regulator-boot-on;
		regulator-min-microvolt = <0x4c4b40>;
		regulator-max-microvolt = <0x4c4b40>;
		vin-supply = <0xce>;
		phandle = <0x27b>;
	};

	vbus {
		compatible = "regulator-fixed";
		regulator-name = "vbus";
		regulator-always-on;
		regulator-boot-on;
		regulator-min-microvolt = <0x4c4b40>;
		regulator-max-microvolt = <0x4c4b40>;
		phandle = <0xba>;
	};

	vcc3v3-pcie-regulator {
		compatible = "regulator-fixed";
		regulator-name = "vcc3v3_pcie";
		regulator-always-on;
		regulator-boot-on;
		enable-active-high;
		gpio = <0x24 0x0f 0x00>;
		pinctrl-names = "default";
		pinctrl-0 = <0xcf>;
		regulator-min-microvolt = <0x325aa0>;
		regulator-max-microvolt = <0x325aa0>;
		vin-supply = <0xce>;
		phandle = <0x65>;
	};

	vcc3v3-sys {
		compatible = "regulator-fixed";
		regulator-name = "vcc3v3_sys";
		regulator-always-on;
		regulator-boot-on;
		regulator-min-microvolt = <0x325aa0>;
		regulator-max-microvolt = <0x325aa0>;
		vin-supply = <0xba>;
		phandle = <0x2c>;
	};

	vcc5v0-sys {
		compatible = "regulator-fixed";
		regulator-name = "vcc5v0_sys";
		regulator-always-on;
		regulator-boot-on;
		regulator-min-microvolt = <0x4c4b40>;
		regulator-max-microvolt = <0x4c4b40>;
		vin-supply = <0xba>;
		phandle = <0x23>;
	};

	vcc5v0-usb {
		compatible = "regulator-fixed";
		regulator-name = "vcc5v0_usb";
		regulator-always-on;
		regulator-boot-on;
		regulator-min-microvolt = <0x4c4b40>;
		regulator-max-microvolt = <0x4c4b40>;
		vin-supply = <0xba>;
		phandle = <0x27c>;
	};

	vcc-sd {
		compatible = "regulator-fixed";
		regulator-max-microvolt = <0x325aa0>;
		regulator-min-microvolt = <0x325aa0>;
		regulator-name = "vcc_sd";
		vin-supply = <0x2c>;
		phandle = <0x66>;
	};

	vcc-phy-regulator {
		compatible = "regulator-fixed";
		regulator-max-microvolt = <0x1b7740>;
		regulator-min-microvolt = <0x1b7740>;
		regulator-name = "vccio_phy";
		regulator-always-on;
		regulator-boot-on;
		phandle = <0x1e>;
	};

	vcc5v0-host-regulator {
		compatible = "regulator-fixed";
		enable-active-high;
		gpio = <0x24 0x06 0x00>;
		pinctrl-names = "default";
		pinctrl-0 = <0xd0>;
		regulator-name = "vcc5v0_host";
		regulator-always-on;
		phandle = <0x27d>;
	};

	vcc5v0-otg-regulator {
		compatible = "regulator-fixed";
		enable-active-high;
		gpio = <0x24 0x05 0x00>;
		pinctrl-names = "default";
		pinctrl-0 = <0xd1>;
		regulator-name = "vcc5v0_otg";
		regulator-always-on;
		phandle = <0x27e>;
	};

	__symbols__ {
		cpu0 = "/cpus/cpu@0";
		cpu1 = "/cpus/cpu@100";
		cpu2 = "/cpus/cpu@200";
		cpu3 = "/cpus/cpu@300";
		cpu0_opp_table = "/opp-table-0";
		display_subsystem = "/display-subsystem";
		scmi = "/firmware/scmi";
		scmi_clk = "/firmware/scmi/protocol@14";
		gpu_opp_table = "/opp-table-1";
		hdmi_sound = "/hdmi-sound";
		xin24m = "/xin24m";
		xin32k = "/xin32k";
		scmi_shmem = "/sram@10f000/sram@0";
		sata1 = "/sata@fc400000";
		sata2 = "/sata@fc800000";
		usb_host0_xhci = "/usb@fcc00000";
		usb_host1_xhci = "/usb@fd000000";
		gic = "/interrupt-controller@fd400000";
		usb_host0_ehci = "/usb@fd800000";
		usb_host0_ohci = "/usb@fd840000";
		usb_host1_ehci = "/usb@fd880000";
		usb_host1_ohci = "/usb@fd8c0000";
		pmugrf = "/syscon@fdc20000";
		pmu_io_domains = "/syscon@fdc20000/io-domains";
		pipegrf = "/syscon@fdc50000";
		grf = "/syscon@fdc60000";
		pipe_phy_grf1 = "/syscon@fdc80000";
		pipe_phy_grf2 = "/syscon@fdc90000";
		usb2phy0_grf = "/syscon@fdca0000";
		usb2phy1_grf = "/syscon@fdca8000";
		pmucru = "/clock-controller@fdd00000";
		cru = "/clock-controller@fdd20000";
		i2c0 = "/i2c@fdd40000";
		vdd_cpu = "/i2c@fdd40000/syr837@40";
		rk809 = "/i2c@fdd40000/pmic@20";
		pinctrl_rk8xx = "/i2c@fdd40000/pmic@20/pinctrl_rk8xx";
		rk817_slppin_null = "/i2c@fdd40000/pmic@20/pinctrl_rk8xx/rk817_slppin_null";
		rk817_slppin_slp = "/i2c@fdd40000/pmic@20/pinctrl_rk8xx/rk817_slppin_slp";
		rk817_slppin_pwrdn = "/i2c@fdd40000/pmic@20/pinctrl_rk8xx/rk817_slppin_pwrdn";
		rk817_slppin_rst = "/i2c@fdd40000/pmic@20/pinctrl_rk8xx/rk817_slppin_rst";
		vdd_logic = "/i2c@fdd40000/pmic@20/regulators/DCDC_REG1";
		vdd_gpu = "/i2c@fdd40000/pmic@20/regulators/DCDC_REG2";
		vcc_ddr = "/i2c@fdd40000/pmic@20/regulators/DCDC_REG3";
		vdd_npu = "/i2c@fdd40000/pmic@20/regulators/DCDC_REG4";
		vdda0v9_image = "/i2c@fdd40000/pmic@20/regulators/LDO_REG1";
		vdda_0v9 = "/i2c@fdd40000/pmic@20/regulators/LDO_REG2";
		vdda0v9_pmu = "/i2c@fdd40000/pmic@20/regulators/LDO_REG3";
		vccio_acodec = "/i2c@fdd40000/pmic@20/regulators/LDO_REG4";
		vccio_sd = "/i2c@fdd40000/pmic@20/regulators/LDO_REG5";
		vcc3v3_pmu = "/i2c@fdd40000/pmic@20/regulators/LDO_REG6";
		vcca_1v8 = "/i2c@fdd40000/pmic@20/regulators/LDO_REG7";
		vcca1v8_pmu = "/i2c@fdd40000/pmic@20/regulators/LDO_REG8";
		vcca1v8_image = "/i2c@fdd40000/pmic@20/regulators/LDO_REG9";
		vcc_1v8 = "/i2c@fdd40000/pmic@20/regulators/DCDC_REG5";
		vcc_3v3 = "/i2c@fdd40000/pmic@20/regulators/SWITCH_REG1";
		vcc3v3_sd = "/i2c@fdd40000/pmic@20/regulators/SWITCH_REG2";
		uart0 = "/serial@fdd50000";
		pwm0 = "/pwm@fdd70000";
		pwm1 = "/pwm@fdd70010";
		pwm2 = "/pwm@fdd70020";
		pwm3 = "/pwm@fdd70030";
		pmu = "/power-management@fdd90000";
		power = "/power-management@fdd90000/power-controller";
		gpu = "/gpu@fde60000";
		vpu = "/video-codec@fdea0400";
		vdpu_mmu = "/iommu@fdea0800";
		rga = "/rga@fdeb0000";
		vepu = "/video-codec@fdee0000";
		vepu_mmu = "/iommu@fdee0800";
		sdmmc2 = "/mmc@fe000000";
		gmac1 = "/ethernet@fe010000";
		mdio1 = "/ethernet@fe010000/mdio";
		rgmii_phy0 = "/ethernet@fe010000/mdio/phy@0";
		gmac1_stmmac_axi_setup = "/ethernet@fe010000/stmmac-axi-config";
		gmac1_mtl_rx_setup = "/ethernet@fe010000/rx-queues-config";
		gmac1_mtl_tx_setup = "/ethernet@fe010000/tx-queues-config";
		vop = "/vop@fe040000";
		vop_out = "/vop@fe040000/ports";
		vp0 = "/vop@fe040000/ports/port@0";
		vp0_out_hdmi = "/vop@fe040000/ports/port@0/endpoint@2";
		vp1 = "/vop@fe040000/ports/port@1";
		vp2 = "/vop@fe040000/ports/port@2";
		vop_mmu = "/iommu@fe043e00";
		dsi0 = "/dsi@fe060000";
		dsi0_in = "/dsi@fe060000/ports/port@0";
		dsi0_out = "/dsi@fe060000/ports/port@1";
		dsi1 = "/dsi@fe070000";
		dsi1_in = "/dsi@fe070000/ports/port@0";
		dsi1_out = "/dsi@fe070000/ports/port@1";
		hdmi = "/hdmi@fe0a0000";
		hdmi_in = "/hdmi@fe0a0000/ports/port@0";
		hdmi_in_vp0 = "/hdmi@fe0a0000/ports/port@0/endpoint";
		hdmi_out = "/hdmi@fe0a0000/ports/port@1";
		hdmi_out_con = "/hdmi@fe0a0000/ports/port@1/endpoint";
		qos_gpu = "/qos@fe128000";
		qos_rkvenc_rd_m0 = "/qos@fe138080";
		qos_rkvenc_rd_m1 = "/qos@fe138100";
		qos_rkvenc_wr_m0 = "/qos@fe138180";
		qos_isp = "/qos@fe148000";
		qos_vicap0 = "/qos@fe148080";
		qos_vicap1 = "/qos@fe148100";
		qos_vpu = "/qos@fe150000";
		qos_ebc = "/qos@fe158000";
		qos_iep = "/qos@fe158100";
		qos_jpeg_dec = "/qos@fe158180";
		qos_jpeg_enc = "/qos@fe158200";
		qos_rga_rd = "/qos@fe158280";
		qos_rga_wr = "/qos@fe158300";
		qos_npu = "/qos@fe180000";
		qos_pcie2x1 = "/qos@fe190000";
		qos_sata1 = "/qos@fe190280";
		qos_sata2 = "/qos@fe190300";
		qos_usb3_0 = "/qos@fe190380";
		qos_usb3_1 = "/qos@fe190400";
		qos_rkvdec = "/qos@fe198000";
		qos_hdcp = "/qos@fe1a8000";
		qos_vop_m0 = "/qos@fe1a8080";
		qos_vop_m1 = "/qos@fe1a8100";
		pcie2x1 = "/pcie@fe260000";
		pcie_intc = "/pcie@fe260000/legacy-interrupt-controller";
		sdmmc0 = "/mmc@fe2b0000";
		sdmmc1 = "/mmc@fe2c0000";
		sfc = "/spi@fe300000";
		sdhci = "/mmc@fe310000";
		crypto = "/crypto@fe380000";
		otp = "/otp@fe38c000";
		cpu_code = "/otp@fe38c000/cpu-code@2";
		otp_cpu_version = "/otp@fe38c000/cpu-version@8";
		mbist_vmin = "/otp@fe38c000/mbist-vmin@9";
		otp_id = "/otp@fe38c000/id@a";
		cpu_leakage = "/otp@fe38c000/cpu-leakage@1a";
		log_leakage = "/otp@fe38c000/log-leakage@1b";
		npu_leakage = "/otp@fe38c000/npu-leakage@1c";
		gpu_leakage = "/otp@fe38c000/gpu-leakage@1d";
		core_pvtm = "/otp@fe38c000/core-pvtm@2a";
		cpu_tsadc_trim_l = "/otp@fe38c000/cpu-tsadc-trim-l@2e";
		cpu_tsadc_trim_h = "/otp@fe38c000/cpu-tsadc-trim-h@2f";
		gpu_tsadc_trim_l = "/otp@fe38c000/npu-tsadc-trim-l@30";
		gpu_tsadc_trim_h = "/otp@fe38c000/npu-tsadc-trim-h@31";
		tsadc_trim_base_frac = "/otp@fe38c000/tsadc-trim-base-frac@31";
		tsadc_trim_base = "/otp@fe38c000/tsadc-trim-base@32";
		cpu_opp_info = "/otp@fe38c000/cpu-opp-info@36";
		gpu_opp_info = "/otp@fe38c000/gpu-opp-info@3c";
		npu_opp_info = "/otp@fe38c000/npu-opp-info@42";
		dmc_opp_info = "/otp@fe38c000/dmc-opp-info@48";
		i2s0_8ch = "/i2s@fe400000";
		i2s1_8ch = "/i2s@fe410000";
		i2s2_2ch = "/i2s@fe420000";
		i2s3_2ch = "/i2s@fe430000";
		pdm = "/pdm@fe440000";
		spdif = "/spdif@fe460000";
		dmac0 = "/dma-controller@fe530000";
		dmac1 = "/dma-controller@fe550000";
		i2c1 = "/i2c@fe5a0000";
		i2c2 = "/i2c@fe5b0000";
		i2c3 = "/i2c@fe5c0000";
		i2c4 = "/i2c@fe5d0000";
		i2c5 = "/i2c@fe5e0000";
		wdt = "/watchdog@fe600000";
		spi0 = "/spi@fe610000";
		spi1 = "/spi@fe620000";
		spi2 = "/spi@fe630000";
		spi3 = "/spi@fe640000";
		uart1 = "/serial@fe650000";
		uart2 = "/serial@fe660000";
		uart3 = "/serial@fe670000";
		uart4 = "/serial@fe680000";
		uart5 = "/serial@fe690000";
		uart6 = "/serial@fe6a0000";
		uart7 = "/serial@fe6b0000";
		uart8 = "/serial@fe6c0000";
		uart9 = "/serial@fe6d0000";
		thermal_zones = "/thermal-zones";
		cpu_thermal = "/thermal-zones/cpu-thermal";
		cpu_alert0 = "/thermal-zones/cpu-thermal/trips/cpu_alert0";
		cpu_alert1 = "/thermal-zones/cpu-thermal/trips/cpu_alert1";
		cpu_crit = "/thermal-zones/cpu-thermal/trips/cpu_crit";
		gpu_thermal = "/thermal-zones/gpu-thermal";
		gpu_threshold = "/thermal-zones/gpu-thermal/trips/gpu-threshold";
		gpu_target = "/thermal-zones/gpu-thermal/trips/gpu-target";
		gpu_crit = "/thermal-zones/gpu-thermal/trips/gpu-crit";
		tsadc = "/tsadc@fe710000";
		saradc = "/saradc@fe720000";
		pwm4 = "/pwm@fe6e0000";
		pwm5 = "/pwm@fe6e0010";
		pwm6 = "/pwm@fe6e0020";
		pwm7 = "/pwm@fe6e0030";
		pwm8 = "/pwm@fe6f0000";
		pwm9 = "/pwm@fe6f0010";
		pwm10 = "/pwm@fe6f0020";
		pwm11 = "/pwm@fe6f0030";
		pwm12 = "/pwm@fe700000";
		pwm13 = "/pwm@fe700010";
		pwm14 = "/pwm@fe700020";
		pwm15 = "/pwm@fe700030";
		combphy1 = "/phy@fe830000";
		combphy2 = "/phy@fe840000";
		csi_dphy = "/phy@fe870000";
		dsi_dphy0 = "/mipi-dphy@fe850000";
		dsi_dphy1 = "/mipi-dphy@fe860000";
		usb2phy0 = "/usb2phy@fe8a0000";
		usb2phy0_host = "/usb2phy@fe8a0000/host-port";
		usb2phy0_otg = "/usb2phy@fe8a0000/otg-port";
		usb2phy1 = "/usb2phy@fe8b0000";
		usb2phy1_host = "/usb2phy@fe8b0000/host-port";
		usb2phy1_otg = "/usb2phy@fe8b0000/otg-port";
		pinctrl = "/pinctrl";
		gpio0 = "/pinctrl/gpio@fdd60000";
		gpio1 = "/pinctrl/gpio@fe740000";
		gpio2 = "/pinctrl/gpio@fe750000";
		gpio3 = "/pinctrl/gpio@fe760000";
		gpio4 = "/pinctrl/gpio@fe770000";
		pcfg_pull_up = "/pinctrl/pcfg-pull-up";
		pcfg_pull_down = "/pinctrl/pcfg-pull-down";
		pcfg_pull_none = "/pinctrl/pcfg-pull-none";
		pcfg_pull_none_drv_level_0 = "/pinctrl/pcfg-pull-none-drv-level-0";
		pcfg_pull_none_drv_level_1 = "/pinctrl/pcfg-pull-none-drv-level-1";
		pcfg_pull_none_drv_level_2 = "/pinctrl/pcfg-pull-none-drv-level-2";
		pcfg_pull_none_drv_level_3 = "/pinctrl/pcfg-pull-none-drv-level-3";
		pcfg_pull_none_drv_level_4 = "/pinctrl/pcfg-pull-none-drv-level-4";
		pcfg_pull_none_drv_level_5 = "/pinctrl/pcfg-pull-none-drv-level-5";
		pcfg_pull_none_drv_level_6 = "/pinctrl/pcfg-pull-none-drv-level-6";
		pcfg_pull_none_drv_level_7 = "/pinctrl/pcfg-pull-none-drv-level-7";
		pcfg_pull_none_drv_level_8 = "/pinctrl/pcfg-pull-none-drv-level-8";
		pcfg_pull_none_drv_level_9 = "/pinctrl/pcfg-pull-none-drv-level-9";
		pcfg_pull_none_drv_level_10 = "/pinctrl/pcfg-pull-none-drv-level-10";
		pcfg_pull_none_drv_level_11 = "/pinctrl/pcfg-pull-none-drv-level-11";
		pcfg_pull_none_drv_level_12 = "/pinctrl/pcfg-pull-none-drv-level-12";
		pcfg_pull_none_drv_level_13 = "/pinctrl/pcfg-pull-none-drv-level-13";
		pcfg_pull_none_drv_level_14 = "/pinctrl/pcfg-pull-none-drv-level-14";
		pcfg_pull_none_drv_level_15 = "/pinctrl/pcfg-pull-none-drv-level-15";
		pcfg_pull_up_drv_level_0 = "/pinctrl/pcfg-pull-up-drv-level-0";
		pcfg_pull_up_drv_level_1 = "/pinctrl/pcfg-pull-up-drv-level-1";
		pcfg_pull_up_drv_level_2 = "/pinctrl/pcfg-pull-up-drv-level-2";
		pcfg_pull_up_drv_level_3 = "/pinctrl/pcfg-pull-up-drv-level-3";
		pcfg_pull_up_drv_level_4 = "/pinctrl/pcfg-pull-up-drv-level-4";
		pcfg_pull_up_drv_level_5 = "/pinctrl/pcfg-pull-up-drv-level-5";
		pcfg_pull_up_drv_level_6 = "/pinctrl/pcfg-pull-up-drv-level-6";
		pcfg_pull_up_drv_level_7 = "/pinctrl/pcfg-pull-up-drv-level-7";
		pcfg_pull_up_drv_level_8 = "/pinctrl/pcfg-pull-up-drv-level-8";
		pcfg_pull_up_drv_level_9 = "/pinctrl/pcfg-pull-up-drv-level-9";
		pcfg_pull_up_drv_level_10 = "/pinctrl/pcfg-pull-up-drv-level-10";
		pcfg_pull_up_drv_level_11 = "/pinctrl/pcfg-pull-up-drv-level-11";
		pcfg_pull_up_drv_level_12 = "/pinctrl/pcfg-pull-up-drv-level-12";
		pcfg_pull_up_drv_level_13 = "/pinctrl/pcfg-pull-up-drv-level-13";
		pcfg_pull_up_drv_level_14 = "/pinctrl/pcfg-pull-up-drv-level-14";
		pcfg_pull_up_drv_level_15 = "/pinctrl/pcfg-pull-up-drv-level-15";
		pcfg_pull_down_drv_level_0 = "/pinctrl/pcfg-pull-down-drv-level-0";
		pcfg_pull_down_drv_level_1 = "/pinctrl/pcfg-pull-down-drv-level-1";
		pcfg_pull_down_drv_level_2 = "/pinctrl/pcfg-pull-down-drv-level-2";
		pcfg_pull_down_drv_level_3 = "/pinctrl/pcfg-pull-down-drv-level-3";
		pcfg_pull_down_drv_level_4 = "/pinctrl/pcfg-pull-down-drv-level-4";
		pcfg_pull_down_drv_level_5 = "/pinctrl/pcfg-pull-down-drv-level-5";
		pcfg_pull_down_drv_level_6 = "/pinctrl/pcfg-pull-down-drv-level-6";
		pcfg_pull_down_drv_level_7 = "/pinctrl/pcfg-pull-down-drv-level-7";
		pcfg_pull_down_drv_level_8 = "/pinctrl/pcfg-pull-down-drv-level-8";
		pcfg_pull_down_drv_level_9 = "/pinctrl/pcfg-pull-down-drv-level-9";
		pcfg_pull_down_drv_level_10 = "/pinctrl/pcfg-pull-down-drv-level-10";
		pcfg_pull_down_drv_level_11 = "/pinctrl/pcfg-pull-down-drv-level-11";
		pcfg_pull_down_drv_level_12 = "/pinctrl/pcfg-pull-down-drv-level-12";
		pcfg_pull_down_drv_level_13 = "/pinctrl/pcfg-pull-down-drv-level-13";
		pcfg_pull_down_drv_level_14 = "/pinctrl/pcfg-pull-down-drv-level-14";
		pcfg_pull_down_drv_level_15 = "/pinctrl/pcfg-pull-down-drv-level-15";
		pcfg_pull_up_smt = "/pinctrl/pcfg-pull-up-smt";
		pcfg_pull_down_smt = "/pinctrl/pcfg-pull-down-smt";
		pcfg_pull_none_smt = "/pinctrl/pcfg-pull-none-smt";
		pcfg_pull_none_drv_level_0_smt = "/pinctrl/pcfg-pull-none-drv-level-0-smt";
		pcfg_output_high = "/pinctrl/pcfg-output-high";
		pcfg_output_low = "/pinctrl/pcfg-output-low";
		acodec_pins = "/pinctrl/acodec/acodec-pins";
		audiopwm_lout = "/pinctrl/audiopwm/audiopwm-lout";
		audiopwm_loutn = "/pinctrl/audiopwm/audiopwm-loutn";
		audiopwm_loutp = "/pinctrl/audiopwm/audiopwm-loutp";
		audiopwm_rout = "/pinctrl/audiopwm/audiopwm-rout";
		audiopwm_routn = "/pinctrl/audiopwm/audiopwm-routn";
		audiopwm_routp = "/pinctrl/audiopwm/audiopwm-routp";
		bt656m0_pins = "/pinctrl/bt656/bt656m0-pins";
		bt656m1_pins = "/pinctrl/bt656/bt656m1-pins";
		bt1120_pins = "/pinctrl/bt1120/bt1120-pins";
		cam_clkout0 = "/pinctrl/cam/cam-clkout0";
		cam_clkout1 = "/pinctrl/cam/cam-clkout1";
		can0m0_pins = "/pinctrl/can0/can0m0-pins";
		can0m1_pins = "/pinctrl/can0/can0m1-pins";
		can1m0_pins = "/pinctrl/can1/can1m0-pins";
		can1m1_pins = "/pinctrl/can1/can1m1-pins";
		can2m0_pins = "/pinctrl/can2/can2m0-pins";
		can2m1_pins = "/pinctrl/can2/can2m1-pins";
		cif_clk = "/pinctrl/cif/cif-clk";
		cif_dvp_clk = "/pinctrl/cif/cif-dvp-clk";
		cif_dvp_bus16 = "/pinctrl/cif/cif-dvp-bus16";
		cif_dvp_bus8 = "/pinctrl/cif/cif-dvp-bus8";
		clk32k_in = "/pinctrl/clk32k/clk32k-in";
		clk32k_out0 = "/pinctrl/clk32k/clk32k-out0";
		clk32k_out1 = "/pinctrl/clk32k/clk32k-out1";
		cpu_pins = "/pinctrl/cpu/cpu-pins";
		ebc_extern = "/pinctrl/ebc/ebc-extern";
		ebc_pins = "/pinctrl/ebc/ebc-pins";
		edpdpm0_pins = "/pinctrl/edpdp/edpdpm0-pins";
		edpdpm1_pins = "/pinctrl/edpdp/edpdpm1-pins";
		emmc_rstnout = "/pinctrl/emmc/emmc-rstnout";
		emmc_bus8 = "/pinctrl/emmc/emmc-bus8";
		emmc_clk = "/pinctrl/emmc/emmc-clk";
		emmc_cmd = "/pinctrl/emmc/emmc-cmd";
		emmc_datastrobe = "/pinctrl/emmc/emmc-datastrobe";
		eth0_pins = "/pinctrl/eth0/eth0-pins";
		eth1m0_pins = "/pinctrl/eth1/eth1m0-pins";
		eth1m1_pins = "/pinctrl/eth1/eth1m1-pins";
		flash_pins = "/pinctrl/flash/flash-pins";
		fspi_pins = "/pinctrl/fspi/fspi-pins";
		fspi_cs1 = "/pinctrl/fspi/fspi-cs1";
		gmac0_miim = "/pinctrl/gmac0/gmac0-miim";
		gmac0_clkinout = "/pinctrl/gmac0/gmac0-clkinout";
		gmac0_rx_er = "/pinctrl/gmac0/gmac0-rx-er";
		gmac0_rx_bus2 = "/pinctrl/gmac0/gmac0-rx-bus2";
		gmac0_tx_bus2 = "/pinctrl/gmac0/gmac0-tx-bus2";
		gmac0_rgmii_clk = "/pinctrl/gmac0/gmac0-rgmii-clk";
		gmac0_rgmii_bus = "/pinctrl/gmac0/gmac0-rgmii-bus";
		gmac1m0_miim = "/pinctrl/gmac1/gmac1m0-miim";
		gmac1m0_clkinout = "/pinctrl/gmac1/gmac1m0-clkinout";
		gmac1m0_rx_er = "/pinctrl/gmac1/gmac1m0-rx-er";
		gmac1m0_rx_bus2 = "/pinctrl/gmac1/gmac1m0-rx-bus2";
		gmac1m0_tx_bus2 = "/pinctrl/gmac1/gmac1m0-tx-bus2";
		gmac1m0_rgmii_clk = "/pinctrl/gmac1/gmac1m0-rgmii-clk";
		gmac1m0_rgmii_bus = "/pinctrl/gmac1/gmac1m0-rgmii-bus";
		gmac1m1_miim = "/pinctrl/gmac1/gmac1m1-miim";
		gmac1m1_clkinout = "/pinctrl/gmac1/gmac1m1-clkinout";
		gmac1m1_rx_er = "/pinctrl/gmac1/gmac1m1-rx-er";
		gmac1m1_rx_bus2 = "/pinctrl/gmac1/gmac1m1-rx-bus2";
		gmac1m1_tx_bus2 = "/pinctrl/gmac1/gmac1m1-tx-bus2";
		gmac1m1_rgmii_clk = "/pinctrl/gmac1/gmac1m1-rgmii-clk";
		gmac1m1_rgmii_bus = "/pinctrl/gmac1/gmac1m1-rgmii-bus";
		gpu_pins = "/pinctrl/gpu/gpu-pins";
		hdmitxm0_cec = "/pinctrl/hdmitx/hdmitxm0-cec";
		hdmitxm1_cec = "/pinctrl/hdmitx/hdmitxm1-cec";
		hdmitx_scl = "/pinctrl/hdmitx/hdmitx-scl";
		hdmitx_sda = "/pinctrl/hdmitx/hdmitx-sda";
		i2c0_xfer = "/pinctrl/i2c0/i2c0-xfer";
		i2c1_xfer = "/pinctrl/i2c1/i2c1-xfer";
		i2c2m0_xfer = "/pinctrl/i2c2/i2c2m0-xfer";
		i2c2m1_xfer = "/pinctrl/i2c2/i2c2m1-xfer";
		i2c3m0_xfer = "/pinctrl/i2c3/i2c3m0-xfer";
		i2c3m1_xfer = "/pinctrl/i2c3/i2c3m1-xfer";
		i2c4m0_xfer = "/pinctrl/i2c4/i2c4m0-xfer";
		i2c4m1_xfer = "/pinctrl/i2c4/i2c4m1-xfer";
		i2c5m0_xfer = "/pinctrl/i2c5/i2c5m0-xfer";
		i2c5m1_xfer = "/pinctrl/i2c5/i2c5m1-xfer";
		i2s1m0_lrckrx = "/pinctrl/i2s1/i2s1m0-lrckrx";
		i2s1m0_lrcktx = "/pinctrl/i2s1/i2s1m0-lrcktx";
		i2s1m0_mclk = "/pinctrl/i2s1/i2s1m0-mclk";
		i2s1m0_sclkrx = "/pinctrl/i2s1/i2s1m0-sclkrx";
		i2s1m0_sclktx = "/pinctrl/i2s1/i2s1m0-sclktx";
		i2s1m0_sdi0 = "/pinctrl/i2s1/i2s1m0-sdi0";
		i2s1m0_sdi1 = "/pinctrl/i2s1/i2s1m0-sdi1";
		i2s1m0_sdi2 = "/pinctrl/i2s1/i2s1m0-sdi2";
		i2s1m0_sdi3 = "/pinctrl/i2s1/i2s1m0-sdi3";
		i2s1m0_sdo0 = "/pinctrl/i2s1/i2s1m0-sdo0";
		i2s1m0_sdo1 = "/pinctrl/i2s1/i2s1m0-sdo1";
		i2s1m0_sdo2 = "/pinctrl/i2s1/i2s1m0-sdo2";
		i2s1m0_sdo3 = "/pinctrl/i2s1/i2s1m0-sdo3";
		i2s1m1_lrckrx = "/pinctrl/i2s1/i2s1m1-lrckrx";
		i2s1m1_lrcktx = "/pinctrl/i2s1/i2s1m1-lrcktx";
		i2s1m1_mclk = "/pinctrl/i2s1/i2s1m1-mclk";
		i2s1m1_sclkrx = "/pinctrl/i2s1/i2s1m1-sclkrx";
		i2s1m1_sclktx = "/pinctrl/i2s1/i2s1m1-sclktx";
		i2s1m1_sdi0 = "/pinctrl/i2s1/i2s1m1-sdi0";
		i2s1m1_sdi1 = "/pinctrl/i2s1/i2s1m1-sdi1";
		i2s1m1_sdi2 = "/pinctrl/i2s1/i2s1m1-sdi2";
		i2s1m1_sdi3 = "/pinctrl/i2s1/i2s1m1-sdi3";
		i2s1m1_sdo0 = "/pinctrl/i2s1/i2s1m1-sdo0";
		i2s1m1_sdo1 = "/pinctrl/i2s1/i2s1m1-sdo1";
		i2s1m1_sdo2 = "/pinctrl/i2s1/i2s1m1-sdo2";
		i2s1m1_sdo3 = "/pinctrl/i2s1/i2s1m1-sdo3";
		i2s1m2_lrckrx = "/pinctrl/i2s1/i2s1m2-lrckrx";
		i2s1m2_lrcktx = "/pinctrl/i2s1/i2s1m2-lrcktx";
		i2s1m2_mclk = "/pinctrl/i2s1/i2s1m2-mclk";
		i2s1m2_sclkrx = "/pinctrl/i2s1/i2s1m2-sclkrx";
		i2s1m2_sclktx = "/pinctrl/i2s1/i2s1m2-sclktx";
		i2s1m2_sdi0 = "/pinctrl/i2s1/i2s1m2-sdi0";
		i2s1m2_sdi1 = "/pinctrl/i2s1/i2s1m2-sdi1";
		i2s1m2_sdi2 = "/pinctrl/i2s1/i2s1m2-sdi2";
		i2s1m2_sdi3 = "/pinctrl/i2s1/i2s1m2-sdi3";
		i2s1m2_sdo0 = "/pinctrl/i2s1/i2s1m2-sdo0";
		i2s1m2_sdo1 = "/pinctrl/i2s1/i2s1m2-sdo1";
		i2s1m2_sdo2 = "/pinctrl/i2s1/i2s1m2-sdo2";
		i2s1m2_sdo3 = "/pinctrl/i2s1/i2s1m2-sdo3";
		i2s2m0_lrckrx = "/pinctrl/i2s2/i2s2m0-lrckrx";
		i2s2m0_lrcktx = "/pinctrl/i2s2/i2s2m0-lrcktx";
		i2s2m0_mclk = "/pinctrl/i2s2/i2s2m0-mclk";
		i2s2m0_sclkrx = "/pinctrl/i2s2/i2s2m0-sclkrx";
		i2s2m0_sclktx = "/pinctrl/i2s2/i2s2m0-sclktx";
		i2s2m0_sdi = "/pinctrl/i2s2/i2s2m0-sdi";
		i2s2m0_sdo = "/pinctrl/i2s2/i2s2m0-sdo";
		i2s2m1_lrckrx = "/pinctrl/i2s2/i2s2m1-lrckrx";
		i2s2m1_lrcktx = "/pinctrl/i2s2/i2s2m1-lrcktx";
		i2s2m1_mclk = "/pinctrl/i2s2/i2s2m1-mclk";
		i2s2m1_sclkrx = "/pinctrl/i2s2/i2s2m1-sclkrx";
		i2s2m1_sclktx = "/pinctrl/i2s2/i2s2m1-sclktx";
		i2s2m1_sdi = "/pinctrl/i2s2/i2s2m1-sdi";
		i2s2m1_sdo = "/pinctrl/i2s2/i2s2m1-sdo";
		i2s3m0_lrck = "/pinctrl/i2s3/i2s3m0-lrck";
		i2s3m0_mclk = "/pinctrl/i2s3/i2s3m0-mclk";
		i2s3m0_sclk = "/pinctrl/i2s3/i2s3m0-sclk";
		i2s3m0_sdi = "/pinctrl/i2s3/i2s3m0-sdi";
		i2s3m0_sdo = "/pinctrl/i2s3/i2s3m0-sdo";
		i2s3m1_lrck = "/pinctrl/i2s3/i2s3m1-lrck";
		i2s3m1_mclk = "/pinctrl/i2s3/i2s3m1-mclk";
		i2s3m1_sclk = "/pinctrl/i2s3/i2s3m1-sclk";
		i2s3m1_sdi = "/pinctrl/i2s3/i2s3m1-sdi";
		i2s3m1_sdo = "/pinctrl/i2s3/i2s3m1-sdo";
		isp_pins = "/pinctrl/isp/isp-pins";
		jtag_pins = "/pinctrl/jtag/jtag-pins";
		lcdc_ctl = "/pinctrl/lcdc/lcdc-ctl";
		lcdc_clock = "/pinctrl/lcdc/lcdc-clock";
		lcdc_data16 = "/pinctrl/lcdc/lcdc-data16";
		lcdc_data18 = "/pinctrl/lcdc/lcdc-data18";
		mcu_pins = "/pinctrl/mcu/mcu-pins";
		npu_pins = "/pinctrl/npu/npu-pins";
		pcie20m0_pins = "/pinctrl/pcie20/pcie20m0-pins";
		pcie20m1_pins = "/pinctrl/pcie20/pcie20m1-pins";
		pcie20m2_pins = "/pinctrl/pcie20/pcie20m2-pins";
		pcie20_buttonrstn = "/pinctrl/pcie20/pcie20-buttonrstn";
		pcie30x1m0_pins = "/pinctrl/pcie30x1/pcie30x1m0-pins";
		pcie30x1m1_pins = "/pinctrl/pcie30x1/pcie30x1m1-pins";
		pcie30x1m2_pins = "/pinctrl/pcie30x1/pcie30x1m2-pins";
		pcie30x1_buttonrstn = "/pinctrl/pcie30x1/pcie30x1-buttonrstn";
		pcie30x2m0_pins = "/pinctrl/pcie30x2/pcie30x2m0-pins";
		pcie30x2m1_pins = "/pinctrl/pcie30x2/pcie30x2m1-pins";
		pcie30x2m2_pins = "/pinctrl/pcie30x2/pcie30x2m2-pins";
		pcie30x2_buttonrstn = "/pinctrl/pcie30x2/pcie30x2-buttonrstn";
		pdmm0_clk = "/pinctrl/pdm/pdmm0-clk";
		pdmm0_clk1 = "/pinctrl/pdm/pdmm0-clk1";
		pdmm0_sdi0 = "/pinctrl/pdm/pdmm0-sdi0";
		pdmm0_sdi1 = "/pinctrl/pdm/pdmm0-sdi1";
		pdmm0_sdi2 = "/pinctrl/pdm/pdmm0-sdi2";
		pdmm0_sdi3 = "/pinctrl/pdm/pdmm0-sdi3";
		pdmm1_clk = "/pinctrl/pdm/pdmm1-clk";
		pdmm1_clk1 = "/pinctrl/pdm/pdmm1-clk1";
		pdmm1_sdi0 = "/pinctrl/pdm/pdmm1-sdi0";
		pdmm1_sdi1 = "/pinctrl/pdm/pdmm1-sdi1";
		pdmm1_sdi2 = "/pinctrl/pdm/pdmm1-sdi2";
		pdmm1_sdi3 = "/pinctrl/pdm/pdmm1-sdi3";
		pdmm2_clk1 = "/pinctrl/pdm/pdmm2-clk1";
		pdmm2_sdi0 = "/pinctrl/pdm/pdmm2-sdi0";
		pdmm2_sdi1 = "/pinctrl/pdm/pdmm2-sdi1";
		pdmm2_sdi2 = "/pinctrl/pdm/pdmm2-sdi2";
		pdmm2_sdi3 = "/pinctrl/pdm/pdmm2-sdi3";
		pmic_pins = "/pinctrl/pmic/pmic-pins";
		pmic_int = "/pinctrl/pmic/pmic_int";
		soc_slppin_gpio = "/pinctrl/pmic/soc_slppin_gpio";
		soc_slppin_slp = "/pinctrl/pmic/soc_slppin_slp";
		soc_slppin_rst = "/pinctrl/pmic/soc_slppin_rst";
		pmu_pins = "/pinctrl/pmu/pmu-pins";
		pwm0m0_pins = "/pinctrl/pwm0/pwm0m0-pins";
		pwm0m1_pins = "/pinctrl/pwm0/pwm0m1-pins";
		pwm1m0_pins = "/pinctrl/pwm1/pwm1m0-pins";
		pwm1m1_pins = "/pinctrl/pwm1/pwm1m1-pins";
		pwm2m0_pins = "/pinctrl/pwm2/pwm2m0-pins";
		pwm2m1_pins = "/pinctrl/pwm2/pwm2m1-pins";
		pwm3_pins = "/pinctrl/pwm3/pwm3-pins";
		pwm4_pins = "/pinctrl/pwm4/pwm4-pins";
		pwm5_pins = "/pinctrl/pwm5/pwm5-pins";
		pwm6_pins = "/pinctrl/pwm6/pwm6-pins";
		pwm7_pins = "/pinctrl/pwm7/pwm7-pins";
		pwm8m0_pins = "/pinctrl/pwm8/pwm8m0-pins";
		pwm8m1_pins = "/pinctrl/pwm8/pwm8m1-pins";
		pwm9m0_pins = "/pinctrl/pwm9/pwm9m0-pins";
		pwm9m1_pins = "/pinctrl/pwm9/pwm9m1-pins";
		pwm10m0_pins = "/pinctrl/pwm10/pwm10m0-pins";
		pwm10m1_pins = "/pinctrl/pwm10/pwm10m1-pins";
		pwm11m0_pins = "/pinctrl/pwm11/pwm11m0-pins";
		pwm11m1_pins = "/pinctrl/pwm11/pwm11m1-pins";
		pwm12m0_pins = "/pinctrl/pwm12/pwm12m0-pins";
		pwm12m1_pins = "/pinctrl/pwm12/pwm12m1-pins";
		pwm13m0_pins = "/pinctrl/pwm13/pwm13m0-pins";
		pwm13m1_pins = "/pinctrl/pwm13/pwm13m1-pins";
		pwm14m0_pins = "/pinctrl/pwm14/pwm14m0-pins";
		pwm14m1_pins = "/pinctrl/pwm14/pwm14m1-pins";
		pwm15m0_pins = "/pinctrl/pwm15/pwm15m0-pins";
		pwm15m1_pins = "/pinctrl/pwm15/pwm15m1-pins";
		refclk_pins = "/pinctrl/refclk/refclk-pins";
		sata_pins = "/pinctrl/sata/sata-pins";
		sata0_pins = "/pinctrl/sata0/sata0-pins";
		sata1_pins = "/pinctrl/sata1/sata1-pins";
		sata2_pins = "/pinctrl/sata2/sata2-pins";
		scr_pins = "/pinctrl/scr/scr-pins";
		sdmmc0_bus4 = "/pinctrl/sdmmc0/sdmmc0-bus4";
		sdmmc0_clk = "/pinctrl/sdmmc0/sdmmc0-clk";
		sdmmc0_cmd = "/pinctrl/sdmmc0/sdmmc0-cmd";
		sdmmc0_det = "/pinctrl/sdmmc0/sdmmc0-det";
		sdmmc0_pwren = "/pinctrl/sdmmc0/sdmmc0-pwren";
		sdmmc1_bus4 = "/pinctrl/sdmmc1/sdmmc1-bus4";
		sdmmc1_clk = "/pinctrl/sdmmc1/sdmmc1-clk";
		sdmmc1_cmd = "/pinctrl/sdmmc1/sdmmc1-cmd";
		sdmmc1_det = "/pinctrl/sdmmc1/sdmmc1-det";
		sdmmc1_pwren = "/pinctrl/sdmmc1/sdmmc1-pwren";
		sdmmc2m0_bus4 = "/pinctrl/sdmmc2/sdmmc2m0-bus4";
		sdmmc2m0_clk = "/pinctrl/sdmmc2/sdmmc2m0-clk";
		sdmmc2m0_cmd = "/pinctrl/sdmmc2/sdmmc2m0-cmd";
		sdmmc2m0_det = "/pinctrl/sdmmc2/sdmmc2m0-det";
		sdmmc2m0_pwren = "/pinctrl/sdmmc2/sdmmc2m0-pwren";
		sdmmc2m1_bus4 = "/pinctrl/sdmmc2/sdmmc2m1-bus4";
		sdmmc2m1_clk = "/pinctrl/sdmmc2/sdmmc2m1-clk";
		sdmmc2m1_cmd = "/pinctrl/sdmmc2/sdmmc2m1-cmd";
		sdmmc2m1_det = "/pinctrl/sdmmc2/sdmmc2m1-det";
		sdmmc2m1_pwren = "/pinctrl/sdmmc2/sdmmc2m1-pwren";
		spdifm0_tx = "/pinctrl/spdif/spdifm0-tx";
		spdifm1_tx = "/pinctrl/spdif/spdifm1-tx";
		spdifm2_tx = "/pinctrl/spdif/spdifm2-tx";
		spi0m0_pins = "/pinctrl/spi0/spi0m0-pins";
		spi0m0_cs0 = "/pinctrl/spi0/spi0m0-cs0";
		spi0m0_cs1 = "/pinctrl/spi0/spi0m0-cs1";
		spi0m1_pins = "/pinctrl/spi0/spi0m1-pins";
		spi0m1_cs0 = "/pinctrl/spi0/spi0m1-cs0";
		spi1m0_pins = "/pinctrl/spi1/spi1m0-pins";
		spi1m0_cs0 = "/pinctrl/spi1/spi1m0-cs0";
		spi1m0_cs1 = "/pinctrl/spi1/spi1m0-cs1";
		spi1m1_pins = "/pinctrl/spi1/spi1m1-pins";
		spi1m1_cs0 = "/pinctrl/spi1/spi1m1-cs0";
		spi2m0_pins = "/pinctrl/spi2/spi2m0-pins";
		spi2m0_cs0 = "/pinctrl/spi2/spi2m0-cs0";
		spi2m0_cs1 = "/pinctrl/spi2/spi2m0-cs1";
		spi2m1_pins = "/pinctrl/spi2/spi2m1-pins";
		spi2m1_cs0 = "/pinctrl/spi2/spi2m1-cs0";
		spi2m1_cs1 = "/pinctrl/spi2/spi2m1-cs1";
		spi3m0_pins = "/pinctrl/spi3/spi3m0-pins";
		spi3m0_cs0 = "/pinctrl/spi3/spi3m0-cs0";
		spi3m0_cs1 = "/pinctrl/spi3/spi3m0-cs1";
		spi3m1_pins = "/pinctrl/spi3/spi3m1-pins";
		spi3m1_cs0 = "/pinctrl/spi3/spi3m1-cs0";
		spi3m1_cs1 = "/pinctrl/spi3/spi3m1-cs1";
		tsadcm0_shut = "/pinctrl/tsadc/tsadcm0-shut";
		tsadcm1_shut = "/pinctrl/tsadc/tsadcm1-shut";
		tsadc_shutorg = "/pinctrl/tsadc/tsadc-shutorg";
		tsadc_pin = "/pinctrl/tsadc/tsadc-pin";
		uart0_xfer = "/pinctrl/uart0/uart0-xfer";
		uart0_ctsn = "/pinctrl/uart0/uart0-ctsn";
		uart0_rtsn = "/pinctrl/uart0/uart0-rtsn";
		uart1m0_xfer = "/pinctrl/uart1/uart1m0-xfer";
		uart1m0_ctsn = "/pinctrl/uart1/uart1m0-ctsn";
		uart1m0_rtsn = "/pinctrl/uart1/uart1m0-rtsn";
		uart1m1_xfer = "/pinctrl/uart1/uart1m1-xfer";
		uart1m1_ctsn = "/pinctrl/uart1/uart1m1-ctsn";
		uart1m1_rtsn = "/pinctrl/uart1/uart1m1-rtsn";
		uart2m0_xfer = "/pinctrl/uart2/uart2m0-xfer";
		uart2m1_xfer = "/pinctrl/uart2/uart2m1-xfer";
		uart3m0_xfer = "/pinctrl/uart3/uart3m0-xfer";
		uart3m0_ctsn = "/pinctrl/uart3/uart3m0-ctsn";
		uart3m0_rtsn = "/pinctrl/uart3/uart3m0-rtsn";
		uart3m1_xfer = "/pinctrl/uart3/uart3m1-xfer";
		uart4m0_xfer = "/pinctrl/uart4/uart4m0-xfer";
		uart4m0_ctsn = "/pinctrl/uart4/uart4m0-ctsn";
		uart4m0_rtsn = "/pinctrl/uart4/uart4m0-rtsn";
		uart4m1_xfer = "/pinctrl/uart4/uart4m1-xfer";
		uart5m0_xfer = "/pinctrl/uart5/uart5m0-xfer";
		uart5m0_ctsn = "/pinctrl/uart5/uart5m0-ctsn";
		uart5m0_rtsn = "/pinctrl/uart5/uart5m0-rtsn";
		uart5m1_xfer = "/pinctrl/uart5/uart5m1-xfer";
		uart6m0_xfer = "/pinctrl/uart6/uart6m0-xfer";
		uart6m0_ctsn = "/pinctrl/uart6/uart6m0-ctsn";
		uart6m0_rtsn = "/pinctrl/uart6/uart6m0-rtsn";
		uart6m1_xfer = "/pinctrl/uart6/uart6m1-xfer";
		uart7m0_xfer = "/pinctrl/uart7/uart7m0-xfer";
		uart7m0_ctsn = "/pinctrl/uart7/uart7m0-ctsn";
		uart7m0_rtsn = "/pinctrl/uart7/uart7m0-rtsn";
		uart7m1_xfer = "/pinctrl/uart7/uart7m1-xfer";
		uart7m2_xfer = "/pinctrl/uart7/uart7m2-xfer";
		uart8m0_xfer = "/pinctrl/uart8/uart8m0-xfer";
		uart8m0_ctsn = "/pinctrl/uart8/uart8m0-ctsn";
		uart8m0_rtsn = "/pinctrl/uart8/uart8m0-rtsn";
		uart8m1_xfer = "/pinctrl/uart8/uart8m1-xfer";
		uart9m0_xfer = "/pinctrl/uart9/uart9m0-xfer";
		uart9m0_ctsn = "/pinctrl/uart9/uart9m0-ctsn";
		uart9m0_rtsn = "/pinctrl/uart9/uart9m0-rtsn";
		uart9m1_xfer = "/pinctrl/uart9/uart9m1-xfer";
		uart9m2_xfer = "/pinctrl/uart9/uart9m2-xfer";
		vopm0_pins = "/pinctrl/vop/vopm0-pins";
		vopm1_pins = "/pinctrl/vop/vopm1-pins";
		spi0m0_pins_hs = "/pinctrl/spi0-hs/spi0m0-pins";
		spi0m0_cs0_hs = "/pinctrl/spi0-hs/spi0m0-cs0";
		spi0m0_cs1_hs = "/pinctrl/spi0-hs/spi0m0-cs1";
		spi0m1_pins_hs = "/pinctrl/spi0-hs/spi0m1-pins";
		spi0m1_cs0_hs = "/pinctrl/spi0-hs/spi0m1-cs0";
		spi1m0_pins_hs = "/pinctrl/spi1-hs/spi1m0-pins";
		spi1m0_cs0_hs = "/pinctrl/spi1-hs/spi1m0-cs0";
		spi1m0_cs1_hs = "/pinctrl/spi1-hs/spi1m0-cs1";
		spi1m1_pins_hs = "/pinctrl/spi1-hs/spi1m1-pins";
		spi1m1_cs0_hs = "/pinctrl/spi1-hs/spi1m1-cs0";
		spi2m0_pins_hs = "/pinctrl/spi2-hs/spi2m0-pins";
		spi2m0_cs0_hs = "/pinctrl/spi2-hs/spi2m0-cs0";
		spi2m0_cs1_hs = "/pinctrl/spi2-hs/spi2m0-cs1";
		spi2m1_pins_hs = "/pinctrl/spi2-hs/spi2m1-pins";
		spi2m1_cs0_hs = "/pinctrl/spi2-hs/spi2m1-cs0";
		spi2m1_cs1_hs = "/pinctrl/spi2-hs/spi2m1-cs1";
		spi3m0_pins_hs = "/pinctrl/spi3-hs/spi3m0-pins";
		spi3m0_cs0_hs = "/pinctrl/spi3-hs/spi3m0-cs0";
		spi3m0_cs1_hs = "/pinctrl/spi3-hs/spi3m0-cs1";
		spi3m1_pins_hs = "/pinctrl/spi3-hs/spi3m1-pins";
		spi3m1_cs0_hs = "/pinctrl/spi3-hs/spi3m1-cs0";
		spi3m1_cs1_hs = "/pinctrl/spi3-hs/spi3m1-cs1";
		gmac0_tx_bus2_level3 = "/pinctrl/gmac-txd-level3/gmac0-tx-bus2-level3";
		gmac0_rgmii_bus_level3 = "/pinctrl/gmac-txd-level3/gmac0-rgmii-bus-level3";
		gmac1m0_tx_bus2_level3 = "/pinctrl/gmac-txd-level3/gmac1m0-tx-bus2-level3";
		gmac1m0_rgmii_bus_level3 = "/pinctrl/gmac-txd-level3/gmac1m0-rgmii-bus-level3";
		gmac1m1_tx_bus2_level3 = "/pinctrl/gmac-txd-level3/gmac1m1-tx-bus2-level3";
		gmac1m1_rgmii_bus_level3 = "/pinctrl/gmac-txd-level3/gmac1m1-rgmii-bus-level3";
		gmac0_rgmii_clk_level2 = "/pinctrl/gmac-txc-level2/gmac0-rgmii-clk-level2";
		gmac1m0_rgmii_clk_level2 = "/pinctrl/gmac-txc-level2/gmac1m0-rgmii-clk-level2";
		gmac1m1_rgmii_clk_level2 = "/pinctrl/gmac-txc-level2/gmac1m1-rgmii-clk-level2";
		bt_reset_h = "/pinctrl/bt/bt-reset-h";
		bt_host_wake_l = "/pinctrl/bt/bt-host-wake-l";
		bt_wake_l = "/pinctrl/bt/bt-wake-l";
		sdmmc0_pwr_h = "/pinctrl/sd/sdmmc0-pwr-h";
		mxc6655xa_irq_gpio = "/pinctrl/mxc6655xa/mxc6655xa_irq_gpio";
		touch_gpio = "/pinctrl/touch/touch-gpio";
		wifi_enable_h = "/pinctrl/sdio-pwrseq/wifi-enable-h";
		vcc5v0_host_en = "/pinctrl/usb/vcc5v0-host-en";
		vcc5v0_otg_en = "/pinctrl/usb/vcc5v0-otg-en";
		leds_gpio = "/pinctrl/work-led/leds-gpio";
		hp_det = "/pinctrl/headphone/hp-det";
		pcie_drv = "/pinctrl/pcie/pcie-drv";
		edp_hpd = "/pinctrl/edp/edp-hpd";
		bl_en = "/pinctrl/edp/bl-en";
		chosen = "/chosen";
		fan = "/pwm-fan";
		hdmi_con_in = "/hdmi-con/port/endpoint";
		leds = "/leds";
		sdio_pwrseq = "/sdio-pwrseq";
		vcc12v_dcin = "/vcc12v-dcin-regulator";
		vcc_5v = "/vcc-5v-regulator";
		vbus = "/vbus";
		vcc3v3_pcie = "/vcc3v3-pcie-regulator";
		vcc3v3_sys = "/vcc3v3-sys";
		vcc5v0_sys = "/vcc5v0-sys";
		vcc5v0_usb = "/vcc5v0-usb";
		vcc_sd = "/vcc-sd";
		vccio_phy = "/vcc-phy-regulator";
		vcc5v0_host = "/vcc5v0-host-regulator";
		vcc5v0_otg = "/vcc5v0-otg-regulator";
	};
};
